VERSION ""

NS_ :

BS_:

BU_: External_Tool CADM LRRF MRRRL MRRRR

BO_ 1539 MRR_RR_Detection_022_028: 64 MRRRR
 SG_ MRR_RR_CAN_DET_MID_TARGET_028 : 462|1@0+ (1,0) [0|1] ""  CADM
 SG_ MRR_RR_CAN_DET_MID_TARGET_027 : 461|1@0+ (1,0) [0|1] ""  CADM
 SG_ MRR_RR_CAN_DET_MID_TARGET_026 : 460|1@0+ (1,0) [0|1] ""  CADM
 SG_ MRR_RR_CAN_DET_MID_TARGET_025 : 459|1@0+ (1,0) [0|1] ""  CADM
 SG_ MRR_RR_CAN_DET_MID_TARGET_024 : 458|1@0+ (1,0) [0|1] ""  CADM
 SG_ MRR_RR_CAN_DET_MID_TARGET_023 : 457|1@0+ (1,0) [0|1] ""  CADM
 SG_ MRR_RR_CAN_DET_MID_TARGET_022 : 456|1@0+ (1,0) [0|1] ""  CADM
 SG_ MRR_RR_CAN_DET_Near_TARGET_022 : 448|1@0+ (1,0) [0|1] ""  CADM
 SG_ MRR_RR_CAN_DET_Near_TARGET_023 : 449|1@0+ (1,0) [0|1] ""  CADM
 SG_ MRR_RR_CAN_DET_Near_TARGET_024 : 450|1@0+ (1,0) [0|1] ""  CADM
 SG_ MRR_RR_CAN_DET_Near_TARGET_025 : 451|1@0+ (1,0) [0|1] ""  CADM
 SG_ MRR_RR_CAN_DET_Near_TARGET_026 : 452|1@0+ (1,0) [0|1] ""  CADM
 SG_ MRR_RR_CAN_DET_Near_TARGET_027 : 453|1@0+ (1,0) [0|1] ""  CADM
 SG_ MRR_RR_CAN_DET_Near_TARGET_028 : 454|1@0+ (1,0) [0|1] ""  CADM
 SG_ MRR_RR_CAN_DET_ELEVATION_022 : 63|7@0+ (0.002748,-0.1745) [-0.1745|0.174496] "rad"  CADM
 SG_ MRR_RR_CAN_DET_CONFID_AZIMU_0018 : 33|2@0+ (1,0) [0|3] ""  CADM
 SG_ MRR_RR_CAN_DET_SUPER_RES_TA_0020 : 56|1@0+ (1,0) [0|1] ""  CADM
 SG_ MRR_RR_CAN_DET_CONFID_ELEVA_0020 : 49|1@0+ (1,0) [0|1] ""  CADM
 SG_ MRR_RR_CAN_DET_HOST_VEH_CLU_0020 : 48|1@0+ (1,0) [0|1] ""  CADM
 SG_ MRR_RR_CAN_DET_VALID_LEVEL_022 : 0|1@0+ (1,0) [0|1] ""  CADM
 SG_ MRR_RR_CAN_DET_AZIMUTH_022 : 47|14@0+ (0.0003834,-3.1416) [-3.1416|3.1396422] "rad"  CADM
 SG_ MRR_RR_CAN_DET_RANGE_022 : 31|14@0+ (0.015625,0) [0|255.984375] "m"  CADM
 SG_ MRR_RR_CAN_DET_RANGE_RATE_022 : 15|14@0+ (0.015625,-128) [-128|127.984375] "m/s"  CADM
 SG_ MRR_RR_CAN_DET_AMPLITUDE_022 : 7|7@0+ (1,-64) [-64|63] "dBsm"  CADM
 SG_ MRR_RR_CAN_SCAN_INDEX_2LSB_022 : 17|2@0+ (1,0) [0|3] ""  CADM
 SG_ MRR_RR_DET_MC_004 : 491|4@0+ (1,0) [0|15] ""  CADM
 SG_ MRR_RR_DET_CRC_004 : 503|16@0+ (1,0) [0|65535] ""  CADM
 SG_ MRR_RR_CAN_DET_ELEVATION_028 : 447|7@0+ (0.002748,-0.1745) [-0.1745|0.174496] "rad"  CADM
 SG_ MRR_RR_CAN_DET_SUPER_RES_TA_0021 : 440|1@0+ (1,0) [0|1] ""  CADM
 SG_ MRR_RR_CAN_DET_AZIMUTH_028 : 431|14@0+ (0.0003834,-3.1416) [-3.1416|3.1396422] "rad"  CADM
 SG_ MRR_RR_CAN_DET_CONFID_ELEVA_0021 : 433|1@0+ (1,0) [0|1] ""  CADM
 SG_ MRR_RR_CAN_DET_HOST_VEH_CLU_0021 : 432|1@0+ (1,0) [0|1] ""  CADM
 SG_ MRR_RR_CAN_DET_RANGE_028 : 415|14@0+ (0.015625,0) [0|255.984375] "m"  CADM
 SG_ MRR_RR_CAN_DET_CONFID_AZIMU_0019 : 417|2@0+ (1,0) [0|3] ""  CADM
 SG_ MRR_RR_CAN_DET_RANGE_RATE_028 : 399|14@0+ (0.015625,-128) [-128|127.984375] "m/s"  CADM
 SG_ MRR_RR_CAN_SCAN_INDEX_2LSB_028 : 401|2@0+ (1,0) [0|3] ""  CADM
 SG_ MRR_RR_CAN_DET_AMPLITUDE_028 : 391|7@0+ (1,-64) [-64|63] "dBsm"  CADM
 SG_ MRR_RR_CAN_DET_VALID_LEVEL_028 : 384|1@0+ (1,0) [0|1] ""  CADM
 SG_ MRR_RR_CAN_DET_ELEVATION_027 : 383|7@0+ (0.002748,-0.1745) [-0.1745|0.174496] "rad"  CADM
 SG_ MRR_RR_CAN_DET_SUPER_RES_TA_0022 : 376|1@0+ (1,0) [0|1] ""  CADM
 SG_ MRR_RR_CAN_DET_AZIMUTH_027 : 367|14@0+ (0.0003834,-3.1416) [-3.1416|3.1396422] "rad"  CADM
 SG_ MRR_RR_CAN_DET_CONFID_ELEVA_0022 : 369|1@0+ (1,0) [0|1] ""  CADM
 SG_ MRR_RR_CAN_DET_HOST_VEH_CLU_0022 : 368|1@0+ (1,0) [0|1] ""  CADM
 SG_ MRR_RR_CAN_DET_RANGE_027 : 351|14@0+ (0.015625,0) [0|255.984375] "m"  CADM
 SG_ MRR_RR_CAN_DET_CONFID_AZIMU_0020 : 353|2@0+ (1,0) [0|3] ""  CADM
 SG_ MRR_RR_CAN_DET_RANGE_RATE_027 : 335|14@0+ (0.015625,-128) [-128|127.984375] "m/s"  CADM
 SG_ MRR_RR_CAN_SCAN_INDEX_2LSB_027 : 337|2@0+ (1,0) [0|3] ""  CADM
 SG_ MRR_RR_CAN_DET_AMPLITUDE_027 : 327|7@0+ (1,-64) [-64|63] "dBsm"  CADM
 SG_ MRR_RR_CAN_DET_VALID_LEVEL_027 : 320|1@0+ (1,0) [0|1] ""  CADM
 SG_ MRR_RR_CAN_DET_ELEVATION_026 : 319|7@0+ (0.002748,-0.1745) [-0.1745|0.174496] "rad"  CADM
 SG_ MRR_RR_CAN_DET_SUPER_RES_TA_0023 : 312|1@0+ (1,0) [0|1] ""  CADM
 SG_ MRR_RR_CAN_DET_AZIMUTH_026 : 303|14@0+ (0.0003834,-3.1416) [-3.1416|3.1396422] "rad"  CADM
 SG_ MRR_RR_CAN_DET_CONFID_ELEVA_0023 : 305|1@0+ (1,0) [0|1] ""  CADM
 SG_ MRR_RR_CAN_DET_HOST_VEH_CLU_0023 : 304|1@0+ (1,0) [0|1] ""  CADM
 SG_ MRR_RR_CAN_DET_RANGE_026 : 287|14@0+ (0.015625,0) [0|255.984375] "m"  CADM
 SG_ MRR_RR_CAN_DET_CONFID_AZIMU_0021 : 289|2@0+ (1,0) [0|3] ""  CADM
 SG_ MRR_RR_CAN_DET_RANGE_RATE_026 : 271|14@0+ (0.015625,-128) [-128|127.984375] "m/s"  CADM
 SG_ MRR_RR_CAN_SCAN_INDEX_2LSB_026 : 273|2@0+ (1,0) [0|3] ""  CADM
 SG_ MRR_RR_CAN_DET_AMPLITUDE_026 : 263|7@0+ (1,-64) [-64|63] "dBsm"  CADM
 SG_ MRR_RR_CAN_DET_VALID_LEVEL_026 : 256|1@0+ (1,0) [0|1] ""  CADM
 SG_ MRR_RR_CAN_DET_ELEVATION_025 : 255|7@0+ (0.002748,-0.1745) [-0.1745|0.174496] "rad"  CADM
 SG_ MRR_RR_CAN_DET_SUPER_RES_TA_0024 : 248|1@0+ (1,0) [0|1] ""  CADM
 SG_ MRR_RR_CAN_DET_AZIMUTH_025 : 239|14@0+ (0.0003834,-3.1416) [-3.1416|3.1396422] "rad"  CADM
 SG_ MRR_RR_CAN_DET_CONFID_ELEVA_0024 : 241|1@0+ (1,0) [0|1] ""  CADM
 SG_ MRR_RR_CAN_DET_HOST_VEH_CLU_0024 : 240|1@0+ (1,0) [0|1] ""  CADM
 SG_ MRR_RR_CAN_DET_RANGE_025 : 223|14@0+ (0.015625,0) [0|255.984375] "m"  CADM
 SG_ MRR_RR_CAN_DET_CONFID_AZIMU_0022 : 225|2@0+ (1,0) [0|3] ""  CADM
 SG_ MRR_RR_CAN_DET_RANGE_RATE_025 : 207|14@0+ (0.015625,-128) [-128|127.984375] "m/s"  CADM
 SG_ MRR_RR_CAN_SCAN_INDEX_2LSB_025 : 209|2@0+ (1,0) [0|3] ""  CADM
 SG_ MRR_RR_CAN_DET_AMPLITUDE_025 : 199|7@0+ (1,-64) [-64|63] "dBsm"  CADM
 SG_ MRR_RR_CAN_DET_VALID_LEVEL_025 : 192|1@0+ (1,0) [0|1] ""  CADM
 SG_ MRR_RR_CAN_DET_ELEVATION_024 : 191|7@0+ (0.002748,-0.1745) [-0.1745|0.174496] "rad"  CADM
 SG_ MRR_RR_CAN_DET_SUPER_RES_TA_0025 : 184|1@0+ (1,0) [0|1] ""  CADM
 SG_ MRR_RR_CAN_DET_AZIMUTH_024 : 175|14@0+ (0.0003834,-3.1416) [-3.1416|3.1396422] "rad"  CADM
 SG_ MRR_RR_CAN_DET_CONFID_ELEVA_0025 : 177|1@0+ (1,0) [0|1] ""  CADM
 SG_ MRR_RR_CAN_DET_HOST_VEH_CLU_0025 : 176|1@0+ (1,0) [0|1] ""  CADM
 SG_ MRR_RR_CAN_DET_RANGE_024 : 159|14@0+ (0.015625,0) [0|255.984375] "m"  CADM
 SG_ MRR_RR_CAN_DET_CONFID_AZIMU_0023 : 161|2@0+ (1,0) [0|3] ""  CADM
 SG_ MRR_RR_CAN_DET_RANGE_RATE_024 : 143|14@0+ (0.015625,-128) [-128|127.984375] "m/s"  CADM
 SG_ MRR_RR_CAN_SCAN_INDEX_2LSB_024 : 145|2@0+ (1,0) [0|3] ""  CADM
 SG_ MRR_RR_CAN_DET_AMPLITUDE_024 : 135|7@0+ (1,-64) [-64|63] "dBsm"  CADM
 SG_ MRR_RR_CAN_DET_VALID_LEVEL_024 : 128|1@0+ (1,0) [0|1] ""  CADM
 SG_ MRR_RR_CAN_DET_ELEVATION_023 : 127|7@0+ (0.002748,-0.1745) [-0.1745|0.174496] "rad"  CADM
 SG_ MRR_RR_CAN_DET_SUPER_RES_TA_0026 : 120|1@0+ (1,0) [0|1] ""  CADM
 SG_ MRR_RR_CAN_DET_AZIMUTH_023 : 111|14@0+ (0.0003834,-3.1416) [-3.1416|3.1396422] "rad"  CADM
 SG_ MRR_RR_CAN_DET_CONFID_ELEVA_0026 : 113|1@0+ (1,0) [0|1] ""  CADM
 SG_ MRR_RR_CAN_DET_HOST_VEH_CLU_0026 : 112|1@0+ (1,0) [0|1] ""  CADM
 SG_ MRR_RR_CAN_DET_RANGE_023 : 95|14@0+ (0.015625,0) [0|255.984375] "m"  CADM
 SG_ MRR_RR_CAN_DET_CONFID_AZIMU_0024 : 97|2@0+ (1,0) [0|3] ""  CADM
 SG_ MRR_RR_CAN_DET_RANGE_RATE_023 : 79|14@0+ (0.015625,-128) [-128|127.984375] "m/s"  CADM
 SG_ MRR_RR_CAN_SCAN_INDEX_2LSB_023 : 81|2@0+ (1,0) [0|3] ""  CADM
 SG_ MRR_RR_CAN_DET_AMPLITUDE_023 : 71|7@0+ (1,-64) [-64|63] "dBsm"  CADM
 SG_ MRR_RR_CAN_DET_VALID_LEVEL_023 : 64|1@0+ (1,0) [0|1] ""  CADM

BO_ 1540 MRR_RR_Detection_029_035: 64 MRRRR
 SG_ MRR_RR_CAN_DET_MID_TARGET_035 : 462|1@0+ (1,0) [0|1] ""  CADM
 SG_ MRR_RR_CAN_DET_MID_TARGET_034 : 461|1@0+ (1,0) [0|1] ""  CADM
 SG_ MRR_RR_CAN_DET_MID_TARGET_033 : 460|1@0+ (1,0) [0|1] ""  CADM
 SG_ MRR_RR_CAN_DET_MID_TARGET_032 : 459|1@0+ (1,0) [0|1] ""  CADM
 SG_ MRR_RR_CAN_DET_MID_TARGET_031 : 458|1@0+ (1,0) [0|1] ""  CADM
 SG_ MRR_RR_CAN_DET_MID_TARGET_030 : 457|1@0+ (1,0) [0|1] ""  CADM
 SG_ MRR_RR_CAN_DET_MID_TARGET_029 : 456|1@0+ (1,0) [0|1] ""  CADM
 SG_ MRR_RR_CAN_DET_Near_TARGET_029 : 448|1@0+ (1,0) [0|1] ""  CADM
 SG_ MRR_RR_CAN_DET_Near_TARGET_030 : 449|1@0+ (1,0) [0|1] ""  CADM
 SG_ MRR_RR_CAN_DET_Near_TARGET_031 : 450|1@0+ (1,0) [0|1] ""  CADM
 SG_ MRR_RR_CAN_DET_Near_TARGET_032 : 451|1@0+ (1,0) [0|1] ""  CADM
 SG_ MRR_RR_CAN_DET_Near_TARGET_033 : 452|1@0+ (1,0) [0|1] ""  CADM
 SG_ MRR_RR_CAN_DET_Near_TARGET_034 : 453|1@0+ (1,0) [0|1] ""  CADM
 SG_ MRR_RR_CAN_DET_Near_TARGET_035 : 454|1@0+ (1,0) [0|1] ""  CADM
 SG_ MRR_RR_CAN_DET_ELEVATION_029 : 63|7@0+ (0.002748,-0.1745) [-0.1745|0.174496] "rad"  CADM
 SG_ MRR_RR_CAN_DET_CONFID_AZIMU_0025 : 33|2@0+ (1,0) [0|3] ""  CADM
 SG_ MRR_RR_CAN_DET_SUPER_RES_TA_0027 : 56|1@0+ (1,0) [0|1] ""  CADM
 SG_ MRR_RR_CAN_DET_CONFID_ELEVA_0027 : 49|1@0+ (1,0) [0|1] ""  CADM
 SG_ MRR_RR_CAN_DET_HOST_VEH_CLU_0027 : 48|1@0+ (1,0) [0|1] ""  CADM
 SG_ MRR_RR_CAN_DET_VALID_LEVEL_029 : 0|1@0+ (1,0) [0|1] ""  CADM
 SG_ MRR_RR_CAN_DET_AZIMUTH_029 : 47|14@0+ (0.0003834,-3.1416) [-3.1416|3.1396422] "rad"  CADM
 SG_ MRR_RR_CAN_DET_RANGE_029 : 31|14@0+ (0.015625,0) [0|255.984375] "m"  CADM
 SG_ MRR_RR_CAN_DET_RANGE_RATE_029 : 15|14@0+ (0.015625,-128) [-128|127.984375] "m/s"  CADM
 SG_ MRR_RR_CAN_DET_AMPLITUDE_029 : 7|7@0+ (1,-64) [-64|63] "dBsm"  CADM
 SG_ MRR_RR_CAN_SCAN_INDEX_2LSB_029 : 17|2@0+ (1,0) [0|3] ""  CADM
 SG_ MRR_RR_DET_MC_005 : 491|4@0+ (1,0) [0|15] ""  CADM
 SG_ MRR_RR_DET_CRC_005 : 503|16@0+ (1,0) [0|65535] ""  CADM
 SG_ MRR_RR_CAN_DET_ELEVATION_035 : 447|7@0+ (0.002748,-0.1745) [-0.1745|0.174496] "rad"  CADM
 SG_ MRR_RR_CAN_DET_SUPER_RES_TA_0028 : 440|1@0+ (1,0) [0|1] ""  CADM
 SG_ MRR_RR_CAN_DET_AZIMUTH_035 : 431|14@0+ (0.0003834,-3.1416) [-3.1416|3.1396422] "rad"  CADM
 SG_ MRR_RR_CAN_DET_CONFID_ELEVA_0028 : 433|1@0+ (1,0) [0|1] ""  CADM
 SG_ MRR_RR_CAN_DET_HOST_VEH_CLU_0028 : 432|1@0+ (1,0) [0|1] ""  CADM
 SG_ MRR_RR_CAN_DET_RANGE_035 : 415|14@0+ (0.015625,0) [0|255.984375] "m"  CADM
 SG_ MRR_RR_CAN_DET_CONFID_AZIMUTH_03 : 417|2@0+ (1,0) [0|3] ""  CADM
 SG_ MRR_RR_CAN_DET_RANGE_RATE_035 : 399|14@0+ (0.015625,-128) [-128|127.984375] "m/s"  CADM
 SG_ MRR_RR_CAN_SCAN_INDEX_2LSB_035 : 401|2@0+ (1,0) [0|3] ""  CADM
 SG_ MRR_RR_CAN_DET_AMPLITUDE_035 : 391|7@0+ (1,-64) [-64|63] "dBsm"  CADM
 SG_ MRR_RR_CAN_DET_VALID_LEVEL_035 : 384|1@0+ (1,0) [0|1] ""  CADM
 SG_ MRR_RR_CAN_DET_ELEVATION_034 : 383|7@0+ (0.002748,-0.1745) [-0.1745|0.174496] "rad"  CADM
 SG_ MRR_RR_CAN_DET_SUPER_RES_TA_0029 : 376|1@0+ (1,0) [0|1] ""  CADM
 SG_ MRR_RR_CAN_DET_AZIMUTH_034 : 367|14@0+ (0.0003834,-3.1416) [-3.1416|3.1396422] "rad"  CADM
 SG_ MRR_RR_CAN_DET_CONFID_ELEVA_0029 : 369|1@0+ (1,0) [0|1] ""  CADM
 SG_ MRR_RR_CAN_DET_HOST_VEH_CLU_0029 : 368|1@0+ (1,0) [0|1] ""  CADM
 SG_ MRR_RR_CAN_DET_RANGE_034 : 351|14@0+ (0.015625,0) [0|255.984375] "m"  CADM
 SG_ MRR_RR_CAN_DET_CONFID_AZIMU_0026 : 353|2@0+ (1,0) [0|3] ""  CADM
 SG_ MRR_RR_CAN_DET_RANGE_RATE_034 : 335|14@0+ (0.015625,-128) [-128|127.984375] "m/s"  CADM
 SG_ MRR_RR_CAN_SCAN_INDEX_2LSB_034 : 337|2@0+ (1,0) [0|3] ""  CADM
 SG_ MRR_RR_CAN_DET_AMPLITUDE_034 : 327|7@0+ (1,-64) [-64|63] "dBsm"  CADM
 SG_ MRR_RR_CAN_DET_VALID_LEVEL_034 : 320|1@0+ (1,0) [0|1] ""  CADM
 SG_ MRR_RR_CAN_DET_ELEVATION_033 : 319|7@0+ (0.002748,-0.1745) [-0.1745|0.174496] "rad"  CADM
 SG_ MRR_RR_CAN_DET_SUPER_RES_TA_0030 : 312|1@0+ (1,0) [0|1] ""  CADM
 SG_ MRR_RR_CAN_DET_AZIMUTH_033 : 303|14@0+ (0.0003834,-3.1416) [-3.1416|3.1396422] "rad"  CADM
 SG_ MRR_RR_CAN_DET_CONFID_ELEVA_0030 : 305|1@0+ (1,0) [0|1] ""  CADM
 SG_ MRR_RR_CAN_DET_HOST_VEH_CLU_0030 : 304|1@0+ (1,0) [0|1] ""  CADM
 SG_ MRR_RR_CAN_DET_RANGE_033 : 287|14@0+ (0.015625,0) [0|255.984375] "m"  CADM
 SG_ MRR_RR_CAN_DET_CONFID_AZIMU_0027 : 289|2@0+ (1,0) [0|3] ""  CADM
 SG_ MRR_RR_CAN_DET_RANGE_RATE_033 : 271|14@0+ (0.015625,-128) [-128|127.984375] "m/s"  CADM
 SG_ MRR_RR_CAN_SCAN_INDEX_2LSB_033 : 273|2@0+ (1,0) [0|3] ""  CADM
 SG_ MRR_RR_CAN_DET_AMPLITUDE_033 : 263|7@0+ (1,-64) [-64|63] "dBsm"  CADM
 SG_ MRR_RR_CAN_DET_VALID_LEVEL_033 : 256|1@0+ (1,0) [0|1] ""  CADM
 SG_ MRR_RR_CAN_DET_ELEVATION_032 : 255|7@0+ (0.002748,-0.1745) [-0.1745|0.174496] "rad"  CADM
 SG_ MRR_RR_CAN_DET_SUPER_RES_TA_0031 : 248|1@0+ (1,0) [0|1] ""  CADM
 SG_ MRR_RR_CAN_DET_AZIMUTH_032 : 239|14@0+ (0.0003834,-3.1416) [-3.1416|3.1396422] "rad"  CADM
 SG_ MRR_RR_CAN_DET_CONFID_ELEVA_0031 : 241|1@0+ (1,0) [0|1] ""  CADM
 SG_ MRR_RR_CAN_DET_HOST_VEH_CLU_0031 : 240|1@0+ (1,0) [0|1] ""  CADM
 SG_ MRR_RR_CAN_DET_RANGE_032 : 223|14@0+ (0.015625,0) [0|255.984375] "m"  CADM
 SG_ MRR_RR_CAN_DET_CONFID_AZIMU_0028 : 225|2@0+ (1,0) [0|3] ""  CADM
 SG_ MRR_RR_CAN_DET_RANGE_RATE_032 : 207|14@0+ (0.015625,-128) [-128|127.984375] "m/s"  CADM
 SG_ MRR_RR_CAN_SCAN_INDEX_2LSB_032 : 209|2@0+ (1,0) [0|3] ""  CADM
 SG_ MRR_RR_CAN_DET_AMPLITUDE_032 : 199|7@0+ (1,-64) [-64|63] "dBsm"  CADM
 SG_ MRR_RR_CAN_DET_VALID_LEVEL_032 : 192|1@0+ (1,0) [0|1] ""  CADM
 SG_ MRR_RR_CAN_DET_ELEVATION_031 : 191|7@0+ (0.002748,-0.1745) [-0.1745|0.174496] "rad"  CADM
 SG_ MRR_RR_CAN_DET_SUPER_RES_TA_0032 : 184|1@0+ (1,0) [0|1] ""  CADM
 SG_ MRR_RR_CAN_DET_AZIMUTH_031 : 175|14@0+ (0.0003834,-3.1416) [-3.1416|3.1396422] "rad"  CADM
 SG_ MRR_RR_CAN_DET_CONFID_ELEVA_0032 : 177|1@0+ (1,0) [0|1] ""  CADM
 SG_ MRR_RR_CAN_DET_HOST_VEH_CLU_0032 : 176|1@0+ (1,0) [0|1] ""  CADM
 SG_ MRR_RR_CAN_DET_RANGE_031 : 159|14@0+ (0.015625,0) [0|255.984375] "m"  CADM
 SG_ MRR_RR_CAN_DET_CONFID_AZIMU_0029 : 161|2@0+ (1,0) [0|3] ""  CADM
 SG_ MRR_RR_CAN_DET_RANGE_RATE_031 : 143|14@0+ (0.015625,-128) [-128|127.984375] "m/s"  CADM
 SG_ MRR_RR_CAN_SCAN_INDEX_2LSB_031 : 145|2@0+ (1,0) [0|3] ""  CADM
 SG_ MRR_RR_CAN_DET_AMPLITUDE_031 : 135|7@0+ (1,-64) [-64|63] "dBsm"  CADM
 SG_ MRR_RR_CAN_DET_VALID_LEVEL_031 : 128|1@0+ (1,0) [0|1] ""  CADM
 SG_ MRR_RR_CAN_DET_ELEVATION_030 : 127|7@0+ (0.002748,-0.1745) [-0.1745|0.174496] "rad"  CADM
 SG_ MRR_RR_CAN_DET_SUPER_RES_TA_0033 : 120|1@0+ (1,0) [0|1] ""  CADM
 SG_ MRR_RR_CAN_DET_AZIMUTH_030 : 111|14@0+ (0.0003834,-3.1416) [-3.1416|3.1396422] "rad"  CADM
 SG_ MRR_RR_CAN_DET_CONFID_ELEVA_0033 : 113|1@0+ (1,0) [0|1] ""  CADM
 SG_ MRR_RR_CAN_DET_HOST_VEH_CLU_0033 : 112|1@0+ (1,0) [0|1] ""  CADM
 SG_ MRR_RR_CAN_DET_RANGE_030 : 95|14@0+ (0.015625,0) [0|255.984375] "m"  CADM
 SG_ MRR_RR_CAN_DET_CONFID_AZIMU_0030 : 97|2@0+ (1,0) [0|3] ""  CADM
 SG_ MRR_RR_CAN_DET_RANGE_RATE_030 : 79|14@0+ (0.015625,-128) [-128|127.984375] "m/s"  CADM
 SG_ MRR_RR_CAN_SCAN_INDEX_2LSB_030 : 81|2@0+ (1,0) [0|3] ""  CADM
 SG_ MRR_RR_CAN_DET_AMPLITUDE_030 : 71|7@0+ (1,-64) [-64|63] "dBsm"  CADM
 SG_ MRR_RR_CAN_DET_VALID_LEVEL_030 : 64|1@0+ (1,0) [0|1] ""  CADM

BO_ 1541 MRR_RR_Detection_036_042: 64 MRRRR
 SG_ MRR_RR_CAN_DET_MID_TARGET_042 : 462|1@0+ (1,0) [0|1] ""  CADM
 SG_ MRR_RR_CAN_DET_MID_TARGET_041 : 461|1@0+ (1,0) [0|1] ""  CADM
 SG_ MRR_RR_CAN_DET_MID_TARGET_040 : 460|1@0+ (1,0) [0|1] ""  CADM
 SG_ MRR_RR_CAN_DET_MID_TARGET_039 : 459|1@0+ (1,0) [0|1] ""  CADM
 SG_ MRR_RR_CAN_DET_MID_TARGET_038 : 458|1@0+ (1,0) [0|1] ""  CADM
 SG_ MRR_RR_CAN_DET_MID_TARGET_037 : 457|1@0+ (1,0) [0|1] ""  CADM
 SG_ MRR_RR_CAN_DET_MID_TARGET_036 : 456|1@0+ (1,0) [0|1] ""  CADM
 SG_ MRR_RR_CAN_DET_Near_TARGET_036 : 448|1@0+ (1,0) [0|1] ""  CADM
 SG_ MRR_RR_CAN_DET_Near_TARGET_037 : 449|1@0+ (1,0) [0|1] ""  CADM
 SG_ MRR_RR_CAN_DET_Near_TARGET_038 : 450|1@0+ (1,0) [0|1] ""  CADM
 SG_ MRR_RR_CAN_DET_Near_TARGET_039 : 451|1@0+ (1,0) [0|1] ""  CADM
 SG_ MRR_RR_CAN_DET_Near_TARGET_040 : 452|1@0+ (1,0) [0|1] ""  CADM
 SG_ MRR_RR_CAN_DET_Near_TARGET_041 : 453|1@0+ (1,0) [0|1] ""  CADM
 SG_ MRR_RR_CAN_DET_Near_TARGET_042 : 454|1@0+ (1,0) [0|1] ""  CADM
 SG_ MRR_RR_CAN_DET_ELEVATION_036 : 63|7@0+ (0.002748,-0.1745) [-0.1745|0.174496] "rad"  CADM
 SG_ MRR_RR_CAN_DET_CONFID_AZIMU_0031 : 33|2@0+ (1,0) [0|3] ""  CADM
 SG_ MRR_RR_CAN_DET_SUPER_RES_TA_0034 : 56|1@0+ (1,0) [0|1] ""  CADM
 SG_ MRR_RR_CAN_DET_CONFID_ELEVA_0034 : 49|1@0+ (1,0) [0|1] ""  CADM
 SG_ MRR_RR_CAN_DET_HOST_VEH_CLU_0034 : 48|1@0+ (1,0) [0|1] ""  CADM
 SG_ MRR_RR_CAN_DET_VALID_LEVEL_036 : 0|1@0+ (1,0) [0|1] ""  CADM
 SG_ MRR_RR_CAN_DET_AZIMUTH_036 : 47|14@0+ (0.0003834,-3.1416) [-3.1416|3.1396422] "rad"  CADM
 SG_ MRR_RR_CAN_DET_RANGE_036 : 31|14@0+ (0.015625,0) [0|255.984375] "m"  CADM
 SG_ MRR_RR_CAN_DET_RANGE_RATE_036 : 15|14@0+ (0.015625,-128) [-128|127.984375] "m/s"  CADM
 SG_ MRR_RR_CAN_DET_AMPLITUDE_036 : 7|7@0+ (1,-64) [-64|63] "dBsm"  CADM
 SG_ MRR_RR_CAN_SCAN_INDEX_2LSB_036 : 17|2@0+ (1,0) [0|3] ""  CADM
 SG_ MRR_RR_DET_MC_006 : 491|4@0+ (1,0) [0|15] ""  CADM
 SG_ MRR_RR_DET_CRC_006 : 503|16@0+ (1,0) [0|65535] ""  CADM
 SG_ MRR_RR_CAN_DET_ELEVATION_042 : 447|7@0+ (0.002748,-0.1745) [-0.1745|0.174496] "rad"  CADM
 SG_ MRR_RR_CAN_DET_SUPER_RES_TA_0035 : 440|1@0+ (1,0) [0|1] ""  CADM
 SG_ MRR_RR_CAN_DET_AZIMUTH_042 : 431|14@0+ (0.0003834,-3.1416) [-3.1416|3.1396422] "rad"  CADM
 SG_ MRR_RR_CAN_DET_CONFID_ELEVA_0035 : 433|1@0+ (1,0) [0|1] ""  CADM
 SG_ MRR_RR_CAN_DET_HOST_VEH_CLU_0035 : 432|1@0+ (1,0) [0|1] ""  CADM
 SG_ MRR_RR_CAN_DET_RANGE_042 : 415|14@0+ (0.015625,0) [0|255.984375] "m"  CADM
 SG_ MRR_RR_CAN_DET_CONFID_AZIMUTH_04 : 417|2@0+ (1,0) [0|3] ""  CADM
 SG_ MRR_RR_CAN_DET_RANGE_RATE_042 : 399|14@0+ (0.015625,-128) [-128|127.984375] "m/s"  CADM
 SG_ MRR_RR_CAN_SCAN_INDEX_2LSB_042 : 401|2@0+ (1,0) [0|3] ""  CADM
 SG_ MRR_RR_CAN_DET_AMPLITUDE_042 : 391|7@0+ (1,-64) [-64|63] "dBsm"  CADM
 SG_ MRR_RR_CAN_DET_VALID_LEVEL_042 : 384|1@0+ (1,0) [0|1] ""  CADM
 SG_ MRR_RR_CAN_DET_ELEVATION_041 : 383|7@0+ (0.002748,-0.1745) [-0.1745|0.174496] "rad"  CADM
 SG_ MRR_RR_CAN_DET_SUPER_RES_TA_0036 : 376|1@0+ (1,0) [0|1] ""  CADM
 SG_ MRR_RR_CAN_DET_AZIMUTH_041 : 367|14@0+ (0.0003834,-3.1416) [-3.1416|3.1396422] "rad"  CADM
 SG_ MRR_RR_CAN_DET_CONFID_ELEVA_0036 : 369|1@0+ (1,0) [0|1] ""  CADM
 SG_ MRR_RR_CAN_DET_HOST_VEH_CLU_0036 : 368|1@0+ (1,0) [0|1] ""  CADM
 SG_ MRR_RR_CAN_DET_RANGE_041 : 351|14@0+ (0.015625,0) [0|255.984375] "m"  CADM
 SG_ MRR_RR_CAN_DET_CONFID_AZIMU_0032 : 353|2@0+ (1,0) [0|3] ""  CADM
 SG_ MRR_RR_CAN_DET_RANGE_RATE_041 : 335|14@0+ (0.015625,-128) [-128|127.984375] "m/s"  CADM
 SG_ MRR_RR_CAN_SCAN_INDEX_2LSB_041 : 337|2@0+ (1,0) [0|3] ""  CADM
 SG_ MRR_RR_CAN_DET_AMPLITUDE_041 : 327|7@0+ (1,-64) [-64|63] "dBsm"  CADM
 SG_ MRR_RR_CAN_DET_VALID_LEVEL_041 : 320|1@0+ (1,0) [0|1] ""  CADM
 SG_ MRR_RR_CAN_DET_ELEVATION_040 : 319|7@0+ (0.002748,-0.1745) [-0.1745|0.174496] "rad"  CADM
 SG_ MRR_RR_CAN_DET_SUPER_RES_TA_0037 : 312|1@0+ (1,0) [0|1] ""  CADM
 SG_ MRR_RR_CAN_DET_AZIMUTH_040 : 303|14@0+ (0.0003834,-3.1416) [-3.1416|3.1396422] "rad"  CADM
 SG_ MRR_RR_CAN_DET_CONFID_ELEVA_0037 : 305|1@0+ (1,0) [0|1] ""  CADM
 SG_ MRR_RR_CAN_DET_HOST_VEH_CLU_0037 : 304|1@0+ (1,0) [0|1] ""  CADM
 SG_ MRR_RR_CAN_DET_RANGE_040 : 287|14@0+ (0.015625,0) [0|255.984375] "m"  CADM
 SG_ MRR_RR_CAN_DET_CONFID_AZIMU_0033 : 289|2@0+ (1,0) [0|3] ""  CADM
 SG_ MRR_RR_CAN_DET_RANGE_RATE_040 : 271|14@0+ (0.015625,-128) [-128|127.984375] "m/s"  CADM
 SG_ MRR_RR_CAN_SCAN_INDEX_2LSB_040 : 273|2@0+ (1,0) [0|3] ""  CADM
 SG_ MRR_RR_CAN_DET_AMPLITUDE_040 : 263|7@0+ (1,-64) [-64|63] "dBsm"  CADM
 SG_ MRR_RR_CAN_DET_VALID_LEVEL_040 : 256|1@0+ (1,0) [0|1] ""  CADM
 SG_ MRR_RR_CAN_DET_ELEVATION_039 : 255|7@0+ (0.002748,-0.1745) [-0.1745|0.174496] "rad"  CADM
 SG_ MRR_RR_CAN_DET_SUPER_RES_TA_0038 : 248|1@0+ (1,0) [0|1] ""  CADM
 SG_ MRR_RR_CAN_DET_AZIMUTH_039 : 239|14@0+ (0.0003834,-3.1416) [-3.1416|3.1396422] "rad"  CADM
 SG_ MRR_RR_CAN_DET_CONFID_ELEVA_0038 : 241|1@0+ (1,0) [0|1] ""  CADM
 SG_ MRR_RR_CAN_DET_HOST_VEH_CLU_0038 : 240|1@0+ (1,0) [0|1] ""  CADM
 SG_ MRR_RR_CAN_DET_RANGE_039 : 223|14@0+ (0.015625,0) [0|255.984375] "m"  CADM
 SG_ MRR_RR_CAN_DET_CONFID_AZIMU_0034 : 225|2@0+ (1,0) [0|3] ""  CADM
 SG_ MRR_RR_CAN_DET_RANGE_RATE_039 : 207|14@0+ (0.015625,-128) [-128|127.984375] "m/s"  CADM
 SG_ MRR_RR_CAN_SCAN_INDEX_2LSB_039 : 209|2@0+ (1,0) [0|3] ""  CADM
 SG_ MRR_RR_CAN_DET_AMPLITUDE_039 : 199|7@0+ (1,-64) [-64|63] "dBsm"  CADM
 SG_ MRR_RR_CAN_DET_VALID_LEVEL_039 : 192|1@0+ (1,0) [0|1] ""  CADM
 SG_ MRR_RR_CAN_DET_ELEVATION_038 : 191|7@0+ (0.002748,-0.1745) [-0.1745|0.174496] "rad"  CADM
 SG_ MRR_RR_CAN_DET_SUPER_RES_TA_0039 : 184|1@0+ (1,0) [0|1] ""  CADM
 SG_ MRR_RR_CAN_DET_AZIMUTH_038 : 175|14@0+ (0.0003834,-3.1416) [-3.1416|3.1396422] "rad"  CADM
 SG_ MRR_RR_CAN_DET_CONFID_ELEVA_0039 : 177|1@0+ (1,0) [0|1] ""  CADM
 SG_ MRR_RR_CAN_DET_HOST_VEH_CLU_0039 : 176|1@0+ (1,0) [0|1] ""  CADM
 SG_ MRR_RR_CAN_DET_RANGE_038 : 159|14@0+ (0.015625,0) [0|255.984375] "m"  CADM
 SG_ MRR_RR_CAN_DET_CONFID_AZIMU_0035 : 161|2@0+ (1,0) [0|3] ""  CADM
 SG_ MRR_RR_CAN_DET_RANGE_RATE_038 : 143|14@0+ (0.015625,-128) [-128|127.984375] "m/s"  CADM
 SG_ MRR_RR_CAN_SCAN_INDEX_2LSB_038 : 145|2@0+ (1,0) [0|3] ""  CADM
 SG_ MRR_RR_CAN_DET_AMPLITUDE_038 : 135|7@0+ (1,-64) [-64|63] "dBsm"  CADM
 SG_ MRR_RR_CAN_DET_VALID_LEVEL_038 : 128|1@0+ (1,0) [0|1] ""  CADM
 SG_ MRR_RR_CAN_DET_ELEVATION_037 : 127|7@0+ (0.002748,-0.1745) [-0.1745|0.174496] "rad"  CADM
 SG_ MRR_RR_CAN_DET_SUPER_RES_TA_0040 : 120|1@0+ (1,0) [0|1] ""  CADM
 SG_ MRR_RR_CAN_DET_AZIMUTH_037 : 111|14@0+ (0.0003834,-3.1416) [-3.1416|3.1396422] "rad"  CADM
 SG_ MRR_RR_CAN_DET_CONFID_ELEVA_0040 : 113|1@0+ (1,0) [0|1] ""  CADM
 SG_ MRR_RR_CAN_DET_HOST_VEH_CLU_0040 : 112|1@0+ (1,0) [0|1] ""  CADM
 SG_ MRR_RR_CAN_DET_RANGE_037 : 95|14@0+ (0.015625,0) [0|255.984375] "m"  CADM
 SG_ MRR_RR_CAN_DET_CONFID_AZIMU_0036 : 97|2@0+ (1,0) [0|3] ""  CADM
 SG_ MRR_RR_CAN_DET_RANGE_RATE_037 : 79|14@0+ (0.015625,-128) [-128|127.984375] "m/s"  CADM
 SG_ MRR_RR_CAN_SCAN_INDEX_2LSB_037 : 81|2@0+ (1,0) [0|3] ""  CADM
 SG_ MRR_RR_CAN_DET_AMPLITUDE_037 : 71|7@0+ (1,-64) [-64|63] "dBsm"  CADM
 SG_ MRR_RR_CAN_DET_VALID_LEVEL_037 : 64|1@0+ (1,0) [0|1] ""  CADM

BO_ 1542 MRR_RR_Detection_043_049: 64 MRRRR
 SG_ MRR_RR_CAN_DET_MID_TARGET_049 : 462|1@0+ (1,0) [0|1] ""  CADM
 SG_ MRR_RR_CAN_DET_MID_TARGET_048 : 461|1@0+ (1,0) [0|1] ""  CADM
 SG_ MRR_RR_CAN_DET_MID_TARGET_047 : 460|1@0+ (1,0) [0|1] ""  CADM
 SG_ MRR_RR_CAN_DET_MID_TARGET_046 : 459|1@0+ (1,0) [0|1] ""  CADM
 SG_ MRR_RR_CAN_DET_MID_TARGET_045 : 458|1@0+ (1,0) [0|1] ""  CADM
 SG_ MRR_RR_CAN_DET_MID_TARGET_044 : 457|1@0+ (1,0) [0|1] ""  CADM
 SG_ MRR_RR_CAN_DET_MID_TARGET_043 : 456|1@0+ (1,0) [0|1] ""  CADM
 SG_ MRR_RR_CAN_DET_Near_TARGET_043 : 448|1@0+ (1,0) [0|1] ""  CADM
 SG_ MRR_RR_CAN_DET_Near_TARGET_044 : 449|1@0+ (1,0) [0|1] ""  CADM
 SG_ MRR_RR_CAN_DET_Near_TARGET_045 : 450|1@0+ (1,0) [0|1] ""  CADM
 SG_ MRR_RR_CAN_DET_Near_TARGET_046 : 451|1@0+ (1,0) [0|1] ""  CADM
 SG_ MRR_RR_CAN_DET_Near_TARGET_047 : 452|1@0+ (1,0) [0|1] ""  CADM
 SG_ MRR_RR_CAN_DET_Near_TARGET_048 : 453|1@0+ (1,0) [0|1] ""  CADM
 SG_ MRR_RR_CAN_DET_Near_TARGET_049 : 454|1@0+ (1,0) [0|1] ""  CADM
 SG_ MRR_RR_CAN_DET_ELEVATION_043 : 63|7@0+ (0.002748,-0.1745) [-0.1745|0.174496] "rad"  CADM
 SG_ MRR_RR_CAN_DET_CONFID_AZIMU_0037 : 33|2@0+ (1,0) [0|3] ""  CADM
 SG_ MRR_RR_CAN_DET_SUPER_RES_TA_0041 : 56|1@0+ (1,0) [0|1] ""  CADM
 SG_ MRR_RR_CAN_DET_CONFID_ELEVA_0041 : 49|1@0+ (1,0) [0|1] ""  CADM
 SG_ MRR_RR_CAN_DET_HOST_VEH_CLU_0041 : 48|1@0+ (1,0) [0|1] ""  CADM
 SG_ MRR_RR_CAN_DET_VALID_LEVEL_043 : 0|1@0+ (1,0) [0|1] ""  CADM
 SG_ MRR_RR_CAN_DET_AZIMUTH_043 : 47|14@0+ (0.0003834,-3.1416) [-3.1416|3.1396422] "rad"  CADM
 SG_ MRR_RR_CAN_DET_RANGE_043 : 31|14@0+ (0.015625,0) [0|255.984375] "m"  CADM
 SG_ MRR_RR_CAN_DET_RANGE_RATE_043 : 15|14@0+ (0.015625,-128) [-128|127.984375] "m/s"  CADM
 SG_ MRR_RR_CAN_DET_AMPLITUDE_043 : 7|7@0+ (1,-64) [-64|63] "dBsm"  CADM
 SG_ MRR_RR_CAN_SCAN_INDEX_2LSB_043 : 17|2@0+ (1,0) [0|3] ""  CADM
 SG_ MRR_RR_DET_MC_007 : 491|4@0+ (1,0) [0|15] ""  CADM
 SG_ MRR_RR_DET_CRC_007 : 503|16@0+ (1,0) [0|65535] ""  CADM
 SG_ MRR_RR_CAN_DET_ELEVATION_049 : 447|7@0+ (0.002748,-0.1745) [-0.1745|0.174496] "rad"  CADM
 SG_ MRR_RR_CAN_DET_SUPER_RES_TA_0042 : 440|1@0+ (1,0) [0|1] ""  CADM
 SG_ MRR_RR_CAN_DET_AZIMUTH_049 : 431|14@0+ (0.0003834,-3.1416) [-3.1416|3.1396422] "rad"  CADM
 SG_ MRR_RR_CAN_DET_CONFID_ELEVA_0042 : 433|1@0+ (1,0) [0|1] ""  CADM
 SG_ MRR_RR_CAN_DET_HOST_VEH_CLU_0042 : 432|1@0+ (1,0) [0|1] ""  CADM
 SG_ MRR_RR_CAN_DET_RANGE_049 : 415|14@0+ (0.015625,0) [0|255.984375] "m"  CADM
 SG_ MRR_RR_CAN_DET_CONFID_AZIMU_0038 : 417|2@0+ (1,0) [0|3] ""  CADM
 SG_ MRR_RR_CAN_DET_RANGE_RATE_049 : 399|14@0+ (0.015625,-128) [-128|127.984375] "m/s"  CADM
 SG_ MRR_RR_CAN_SCAN_INDEX_2LSB_049 : 401|2@0+ (1,0) [0|3] ""  CADM
 SG_ MRR_RR_CAN_DET_AMPLITUDE_049 : 391|7@0+ (1,-64) [-64|63] "dBsm"  CADM
 SG_ MRR_RR_CAN_DET_VALID_LEVEL_049 : 384|1@0+ (1,0) [0|1] ""  CADM
 SG_ MRR_RR_CAN_DET_ELEVATION_048 : 383|7@0+ (0.002748,-0.1745) [-0.1745|0.174496] "rad"  CADM
 SG_ MRR_RR_CAN_DET_SUPER_RES_TA_0043 : 376|1@0+ (1,0) [0|1] ""  CADM
 SG_ MRR_RR_CAN_DET_AZIMUTH_048 : 367|14@0+ (0.0003834,-3.1416) [-3.1416|3.1396422] "rad"  CADM
 SG_ MRR_RR_CAN_DET_CONFID_ELEVA_0043 : 369|1@0+ (1,0) [0|1] ""  CADM
 SG_ MRR_RR_CAN_DET_HOST_VEH_CLU_0043 : 368|1@0+ (1,0) [0|1] ""  CADM
 SG_ MRR_RR_CAN_DET_RANGE_048 : 351|14@0+ (0.015625,0) [0|255.984375] "m"  CADM
 SG_ MRR_RR_CAN_DET_CONFID_AZIMU_0039 : 353|2@0+ (1,0) [0|3] ""  CADM
 SG_ MRR_RR_CAN_DET_RANGE_RATE_048 : 335|14@0+ (0.015625,-128) [-128|127.984375] "m/s"  CADM
 SG_ MRR_RR_CAN_SCAN_INDEX_2LSB_048 : 337|2@0+ (1,0) [0|3] ""  CADM
 SG_ MRR_RR_CAN_DET_AMPLITUDE_048 : 327|7@0+ (1,-64) [-64|63] "dBsm"  CADM
 SG_ MRR_RR_CAN_DET_VALID_LEVEL_048 : 320|1@0+ (1,0) [0|1] ""  CADM
 SG_ MRR_RR_CAN_DET_ELEVATION_047 : 319|7@0+ (0.002748,-0.1745) [-0.1745|0.174496] "rad"  CADM
 SG_ MRR_RR_CAN_DET_SUPER_RES_TA_0044 : 312|1@0+ (1,0) [0|1] ""  CADM
 SG_ MRR_RR_CAN_DET_AZIMUTH_047 : 303|14@0+ (0.0003834,-3.1416) [-3.1416|3.1396422] "rad"  CADM
 SG_ MRR_RR_CAN_DET_CONFID_ELEVA_0044 : 305|1@0+ (1,0) [0|1] ""  CADM
 SG_ MRR_RR_CAN_DET_HOST_VEH_CLU_0044 : 304|1@0+ (1,0) [0|1] ""  CADM
 SG_ MRR_RR_CAN_DET_RANGE_047 : 287|14@0+ (0.015625,0) [0|255.984375] "m"  CADM
 SG_ MRR_RR_CAN_DET_CONFID_AZIMU_0040 : 289|2@0+ (1,0) [0|3] ""  CADM
 SG_ MRR_RR_CAN_DET_RANGE_RATE_047 : 271|14@0+ (0.015625,-128) [-128|127.984375] "m/s"  CADM
 SG_ MRR_RR_CAN_SCAN_INDEX_2LSB_047 : 273|2@0+ (1,0) [0|3] ""  CADM
 SG_ MRR_RR_CAN_DET_AMPLITUDE_047 : 263|7@0+ (1,-64) [-64|63] "dBsm"  CADM
 SG_ MRR_RR_CAN_DET_VALID_LEVEL_047 : 256|1@0+ (1,0) [0|1] ""  CADM
 SG_ MRR_RR_CAN_DET_ELEVATION_046 : 255|7@0+ (0.002748,-0.1745) [-0.1745|0.174496] "rad"  CADM
 SG_ MRR_RR_CAN_DET_SUPER_RES_TA_0045 : 248|1@0+ (1,0) [0|1] ""  CADM
 SG_ MRR_RR_CAN_DET_AZIMUTH_046 : 239|14@0+ (0.0003834,-3.1416) [-3.1416|3.1396422] "rad"  CADM
 SG_ MRR_RR_CAN_DET_CONFID_ELEVA_0045 : 241|1@0+ (1,0) [0|1] ""  CADM
 SG_ MRR_RR_CAN_DET_HOST_VEH_CLU_0045 : 240|1@0+ (1,0) [0|1] ""  CADM
 SG_ MRR_RR_CAN_DET_RANGE_046 : 223|14@0+ (0.015625,0) [0|255.984375] "m"  CADM
 SG_ MRR_RR_CAN_DET_CONFID_AZIMU_0041 : 225|2@0+ (1,0) [0|3] ""  CADM
 SG_ MRR_RR_CAN_DET_RANGE_RATE_046 : 207|14@0+ (0.015625,-128) [-128|127.984375] "m/s"  CADM
 SG_ MRR_RR_CAN_SCAN_INDEX_2LSB_046 : 209|2@0+ (1,0) [0|3] ""  CADM
 SG_ MRR_RR_CAN_DET_AMPLITUDE_046 : 199|7@0+ (1,-64) [-64|63] "dBsm"  CADM
 SG_ MRR_RR_CAN_DET_VALID_LEVEL_046 : 192|1@0+ (1,0) [0|1] ""  CADM
 SG_ MRR_RR_CAN_DET_ELEVATION_045 : 191|7@0+ (0.002748,-0.1745) [-0.1745|0.174496] "rad"  CADM
 SG_ MRR_RR_CAN_DET_SUPER_RES_TA_0046 : 184|1@0+ (1,0) [0|1] ""  CADM
 SG_ MRR_RR_CAN_DET_AZIMUTH_045 : 175|14@0+ (0.0003834,-3.1416) [-3.1416|3.1396422] "rad"  CADM
 SG_ MRR_RR_CAN_DET_CONFID_ELEVA_0046 : 177|1@0+ (1,0) [0|1] ""  CADM
 SG_ MRR_RR_CAN_DET_HOST_VEH_CLU_0046 : 176|1@0+ (1,0) [0|1] ""  CADM
 SG_ MRR_RR_CAN_DET_RANGE_045 : 159|14@0+ (0.015625,0) [0|255.984375] "m"  CADM
 SG_ MRR_RR_CAN_DET_CONFID_AZIMU_0042 : 161|2@0+ (1,0) [0|3] ""  CADM
 SG_ MRR_RR_CAN_DET_RANGE_RATE_045 : 143|14@0+ (0.015625,-128) [-128|127.984375] "m/s"  CADM
 SG_ MRR_RR_CAN_SCAN_INDEX_2LSB_045 : 145|2@0+ (1,0) [0|3] ""  CADM
 SG_ MRR_RR_CAN_DET_AMPLITUDE_045 : 135|7@0+ (1,-64) [-64|63] "dBsm"  CADM
 SG_ MRR_RR_CAN_DET_VALID_LEVEL_045 : 128|1@0+ (1,0) [0|1] ""  CADM
 SG_ MRR_RR_CAN_DET_ELEVATION_044 : 127|7@0+ (0.002748,-0.1745) [-0.1745|0.174496] "rad"  CADM
 SG_ MRR_RR_CAN_DET_SUPER_RES_TA_0047 : 120|1@0+ (1,0) [0|1] ""  CADM
 SG_ MRR_RR_CAN_DET_AZIMUTH_044 : 111|14@0+ (0.0003834,-3.1416) [-3.1416|3.1396422] "rad"  CADM
 SG_ MRR_RR_CAN_DET_CONFID_ELEVA_0047 : 113|1@0+ (1,0) [0|1] ""  CADM
 SG_ MRR_RR_CAN_DET_HOST_VEH_CLU_0047 : 112|1@0+ (1,0) [0|1] ""  CADM
 SG_ MRR_RR_CAN_DET_RANGE_044 : 95|14@0+ (0.015625,0) [0|255.984375] "m"  CADM
 SG_ MRR_RR_CAN_DET_CONFID_AZIMU_0043 : 97|2@0+ (1,0) [0|3] ""  CADM
 SG_ MRR_RR_CAN_DET_RANGE_RATE_044 : 79|14@0+ (0.015625,-128) [-128|127.984375] "m/s"  CADM
 SG_ MRR_RR_CAN_SCAN_INDEX_2LSB_044 : 81|2@0+ (1,0) [0|3] ""  CADM
 SG_ MRR_RR_CAN_DET_AMPLITUDE_044 : 71|7@0+ (1,-64) [-64|63] "dBsm"  CADM
 SG_ MRR_RR_CAN_DET_VALID_LEVEL_044 : 64|1@0+ (1,0) [0|1] ""  CADM

BO_ 1543 MRR_RR_Detection_050_056: 64 MRRRR
 SG_ MRR_RR_CAN_DET_MID_TARGET_056 : 462|1@0+ (1,0) [0|1] ""  CADM
 SG_ MRR_RR_CAN_DET_MID_TARGET_055 : 461|1@0+ (1,0) [0|1] ""  CADM
 SG_ MRR_RR_CAN_DET_MID_TARGET_054 : 460|1@0+ (1,0) [0|1] ""  CADM
 SG_ MRR_RR_CAN_DET_MID_TARGET_053 : 459|1@0+ (1,0) [0|1] ""  CADM
 SG_ MRR_RR_CAN_DET_MID_TARGET_052 : 458|1@0+ (1,0) [0|1] ""  CADM
 SG_ MRR_RR_CAN_DET_MID_TARGET_051 : 457|1@0+ (1,0) [0|1] ""  CADM
 SG_ MRR_RR_CAN_DET_MID_TARGET_050 : 456|1@0+ (1,0) [0|1] ""  CADM
 SG_ MRR_RR_CAN_DET_Near_TARGET_050 : 448|1@0+ (1,0) [0|1] ""  CADM
 SG_ MRR_RR_CAN_DET_Near_TARGET_051 : 449|1@0+ (1,0) [0|1] ""  CADM
 SG_ MRR_RR_CAN_DET_Near_TARGET_052 : 450|1@0+ (1,0) [0|1] ""  CADM
 SG_ MRR_RR_CAN_DET_Near_TARGET_053 : 451|1@0+ (1,0) [0|1] ""  CADM
 SG_ MRR_RR_CAN_DET_Near_TARGET_054 : 452|1@0+ (1,0) [0|1] ""  CADM
 SG_ MRR_RR_CAN_DET_Near_TARGET_055 : 453|1@0+ (1,0) [0|1] ""  CADM
 SG_ MRR_RR_CAN_DET_Near_TARGET_056 : 454|1@0+ (1,0) [0|1] ""  CADM
 SG_ MRR_RR_CAN_DET_ELEVATION_050 : 63|7@0+ (0.002748,-0.1745) [-0.1745|0.174496] "rad"  CADM
 SG_ MRR_RR_CAN_DET_CONFID_AZIMUTH_05 : 33|2@0+ (1,0) [0|3] ""  CADM
 SG_ MRR_RR_CAN_DET_SUPER_RES_TA_0048 : 56|1@0+ (1,0) [0|1] ""  CADM
 SG_ MRR_RR_CAN_DET_CONFID_ELEVA_0048 : 49|1@0+ (1,0) [0|1] ""  CADM
 SG_ MRR_RR_CAN_DET_HOST_VEH_CLU_0048 : 48|1@0+ (1,0) [0|1] ""  CADM
 SG_ MRR_RR_CAN_DET_VALID_LEVEL_050 : 0|1@0+ (1,0) [0|1] ""  CADM
 SG_ MRR_RR_CAN_DET_AZIMUTH_050 : 47|14@0+ (0.0003834,-3.1416) [-3.1416|3.1396422] "rad"  CADM
 SG_ MRR_RR_CAN_DET_RANGE_050 : 31|14@0+ (0.015625,0) [0|255.984375] "m"  CADM
 SG_ MRR_RR_CAN_DET_RANGE_RATE_050 : 15|14@0+ (0.015625,-128) [-128|127.984375] "m/s"  CADM
 SG_ MRR_RR_CAN_DET_AMPLITUDE_050 : 7|7@0+ (1,-64) [-64|63] "dBsm"  CADM
 SG_ MRR_RR_CAN_SCAN_INDEX_2LSB_050 : 17|2@0+ (1,0) [0|3] ""  CADM
 SG_ MRR_RR_DET_MC_008 : 491|4@0+ (1,0) [0|15] ""  CADM
 SG_ MRR_RR_DET_CRC_008 : 503|16@0+ (1,0) [0|65535] ""  CADM
 SG_ MRR_RR_CAN_DET_ELEVATION_056 : 447|7@0+ (0.002748,-0.1745) [-0.1745|0.174496] "rad"  CADM
 SG_ MRR_RR_CAN_DET_SUPER_RES_TA_0049 : 440|1@0+ (1,0) [0|1] ""  CADM
 SG_ MRR_RR_CAN_DET_AZIMUTH_056 : 431|14@0+ (0.0003834,-3.1416) [-3.1416|3.1396422] "rad"  CADM
 SG_ MRR_RR_CAN_DET_CONFID_ELEVA_0049 : 433|1@0+ (1,0) [0|1] ""  CADM
 SG_ MRR_RR_CAN_DET_HOST_VEH_CLU_0049 : 432|1@0+ (1,0) [0|1] ""  CADM
 SG_ MRR_RR_CAN_DET_RANGE_056 : 415|14@0+ (0.015625,0) [0|255.984375] "m"  CADM
 SG_ MRR_RR_CAN_DET_CONFID_AZIMU_0044 : 417|2@0+ (1,0) [0|3] ""  CADM
 SG_ MRR_RR_CAN_DET_RANGE_RATE_056 : 399|14@0+ (0.015625,-128) [-128|127.984375] "m/s"  CADM
 SG_ MRR_RR_CAN_SCAN_INDEX_2LSB_056 : 401|2@0+ (1,0) [0|3] ""  CADM
 SG_ MRR_RR_CAN_DET_AMPLITUDE_056 : 391|7@0+ (1,-64) [-64|63] "dBsm"  CADM
 SG_ MRR_RR_CAN_DET_VALID_LEVEL_056 : 384|1@0+ (1,0) [0|1] ""  CADM
 SG_ MRR_RR_CAN_DET_ELEVATION_055 : 383|7@0+ (0.002748,-0.1745) [-0.1745|0.174496] "rad"  CADM
 SG_ MRR_RR_CAN_DET_SUPER_RES_TA_0050 : 376|1@0+ (1,0) [0|1] ""  CADM
 SG_ MRR_RR_CAN_DET_AZIMUTH_055 : 367|14@0+ (0.0003834,-3.1416) [-3.1416|3.1396422] "rad"  CADM
 SG_ MRR_RR_CAN_DET_CONFID_ELEVA_0050 : 369|1@0+ (1,0) [0|1] ""  CADM
 SG_ MRR_RR_CAN_DET_HOST_VEH_CLU_0050 : 368|1@0+ (1,0) [0|1] ""  CADM
 SG_ MRR_RR_CAN_DET_RANGE_055 : 351|14@0+ (0.015625,0) [0|255.984375] "m"  CADM
 SG_ MRR_RR_CAN_DET_CONFID_AZIMU_0045 : 353|2@0+ (1,0) [0|3] ""  CADM
 SG_ MRR_RR_CAN_DET_RANGE_RATE_055 : 335|14@0+ (0.015625,-128) [-128|127.984375] "m/s"  CADM
 SG_ MRR_RR_CAN_SCAN_INDEX_2LSB_055 : 337|2@0+ (1,0) [0|3] ""  CADM
 SG_ MRR_RR_CAN_DET_AMPLITUDE_055 : 327|7@0+ (1,-64) [-64|63] "dBsm"  CADM
 SG_ MRR_RR_CAN_DET_VALID_LEVEL_055 : 320|1@0+ (1,0) [0|1] ""  CADM
 SG_ MRR_RR_CAN_DET_ELEVATION_054 : 319|7@0+ (0.002748,-0.1745) [-0.1745|0.174496] "rad"  CADM
 SG_ MRR_RR_CAN_DET_SUPER_RES_TA_0051 : 312|1@0+ (1,0) [0|1] ""  CADM
 SG_ MRR_RR_CAN_DET_AZIMUTH_054 : 303|14@0+ (0.0003834,-3.1416) [-3.1416|3.1396422] "rad"  CADM
 SG_ MRR_RR_CAN_DET_CONFID_ELEVA_0051 : 305|1@0+ (1,0) [0|1] ""  CADM
 SG_ MRR_RR_CAN_DET_HOST_VEH_CLU_0051 : 304|1@0+ (1,0) [0|1] ""  CADM
 SG_ MRR_RR_CAN_DET_RANGE_054 : 287|14@0+ (0.015625,0) [0|255.984375] "m"  CADM
 SG_ MRR_RR_CAN_DET_CONFID_AZIMU_0046 : 289|2@0+ (1,0) [0|3] ""  CADM
 SG_ MRR_RR_CAN_DET_RANGE_RATE_054 : 271|14@0+ (0.015625,-128) [-128|127.984375] "m/s"  CADM
 SG_ MRR_RR_CAN_SCAN_INDEX_2LSB_054 : 273|2@0+ (1,0) [0|3] ""  CADM
 SG_ MRR_RR_CAN_DET_AMPLITUDE_054 : 263|7@0+ (1,-64) [-64|63] "dBsm"  CADM
 SG_ MRR_RR_CAN_DET_VALID_LEVEL_054 : 256|1@0+ (1,0) [0|1] ""  CADM
 SG_ MRR_RR_CAN_DET_ELEVATION_053 : 255|7@0+ (0.002748,-0.1745) [-0.1745|0.174496] "rad"  CADM
 SG_ MRR_RR_CAN_DET_SUPER_RES_TA_0052 : 248|1@0+ (1,0) [0|1] ""  CADM
 SG_ MRR_RR_CAN_DET_AZIMUTH_053 : 239|14@0+ (0.0003834,-3.1416) [-3.1416|3.1396422] "rad"  CADM
 SG_ MRR_RR_CAN_DET_CONFID_ELEVA_0052 : 241|1@0+ (1,0) [0|1] ""  CADM
 SG_ MRR_RR_CAN_DET_HOST_VEH_CLU_0052 : 240|1@0+ (1,0) [0|1] ""  CADM
 SG_ MRR_RR_CAN_DET_RANGE_053 : 223|14@0+ (0.015625,0) [0|255.984375] "m"  CADM
 SG_ MRR_RR_CAN_DET_CONFID_AZIMU_0047 : 225|2@0+ (1,0) [0|3] ""  CADM
 SG_ MRR_RR_CAN_DET_RANGE_RATE_053 : 207|14@0+ (0.015625,-128) [-128|127.984375] "m/s"  CADM
 SG_ MRR_RR_CAN_SCAN_INDEX_2LSB_053 : 209|2@0+ (1,0) [0|3] ""  CADM
 SG_ MRR_RR_CAN_DET_AMPLITUDE_053 : 199|7@0+ (1,-64) [-64|63] "dBsm"  CADM
 SG_ MRR_RR_CAN_DET_VALID_LEVEL_053 : 192|1@0+ (1,0) [0|1] ""  CADM
 SG_ MRR_RR_CAN_DET_ELEVATION_052 : 191|7@0+ (0.002748,-0.1745) [-0.1745|0.174496] "rad"  CADM
 SG_ MRR_RR_CAN_DET_SUPER_RES_TA_0053 : 184|1@0+ (1,0) [0|1] ""  CADM
 SG_ MRR_RR_CAN_DET_AZIMUTH_052 : 175|14@0+ (0.0003834,-3.1416) [-3.1416|3.1396422] "rad"  CADM
 SG_ MRR_RR_CAN_DET_CONFID_ELEVA_0053 : 177|1@0+ (1,0) [0|1] ""  CADM
 SG_ MRR_RR_CAN_DET_HOST_VEH_CLU_0053 : 176|1@0+ (1,0) [0|1] ""  CADM
 SG_ MRR_RR_CAN_DET_RANGE_052 : 159|14@0+ (0.015625,0) [0|255.984375] "m"  CADM
 SG_ MRR_RR_CAN_DET_CONFID_AZIMU_0048 : 161|2@0+ (1,0) [0|3] ""  CADM
 SG_ MRR_RR_CAN_DET_RANGE_RATE_052 : 143|14@0+ (0.015625,-128) [-128|127.984375] "m/s"  CADM
 SG_ MRR_RR_CAN_SCAN_INDEX_2LSB_052 : 145|2@0+ (1,0) [0|3] ""  CADM
 SG_ MRR_RR_CAN_DET_AMPLITUDE_052 : 135|7@0+ (1,-64) [-64|63] "dBsm"  CADM
 SG_ MRR_RR_CAN_DET_VALID_LEVEL_052 : 128|1@0+ (1,0) [0|1] ""  CADM
 SG_ MRR_RR_CAN_DET_ELEVATION_051 : 127|7@0+ (0.002748,-0.1745) [-0.1745|0.174496] "rad"  CADM
 SG_ MRR_RR_CAN_DET_SUPER_RES_TA_0054 : 120|1@0+ (1,0) [0|1] ""  CADM
 SG_ MRR_RR_CAN_DET_AZIMUTH_051 : 111|14@0+ (0.0003834,-3.1416) [-3.1416|3.1396422] "rad"  CADM
 SG_ MRR_RR_CAN_DET_CONFID_ELEVA_0054 : 113|1@0+ (1,0) [0|1] ""  CADM
 SG_ MRR_RR_CAN_DET_HOST_VEH_CLU_0054 : 112|1@0+ (1,0) [0|1] ""  CADM
 SG_ MRR_RR_CAN_DET_RANGE_051 : 95|14@0+ (0.015625,0) [0|255.984375] "m"  CADM
 SG_ MRR_RR_CAN_DET_CONFID_AZIMU_0049 : 97|2@0+ (1,0) [0|3] ""  CADM
 SG_ MRR_RR_CAN_DET_RANGE_RATE_051 : 79|14@0+ (0.015625,-128) [-128|127.984375] "m/s"  CADM
 SG_ MRR_RR_CAN_SCAN_INDEX_2LSB_051 : 81|2@0+ (1,0) [0|3] ""  CADM
 SG_ MRR_RR_CAN_DET_AMPLITUDE_051 : 71|7@0+ (1,-64) [-64|63] "dBsm"  CADM
 SG_ MRR_RR_CAN_DET_VALID_LEVEL_051 : 64|1@0+ (1,0) [0|1] ""  CADM

BO_ 1544 MRR_RR_Detection_057_063: 64 MRRRR
 SG_ MRR_RR_CAN_DET_MID_TARGET_063 : 462|1@0+ (1,0) [0|1] ""  CADM
 SG_ MRR_RR_CAN_DET_MID_TARGET_062 : 461|1@0+ (1,0) [0|1] ""  CADM
 SG_ MRR_RR_CAN_DET_MID_TARGET_061 : 460|1@0+ (1,0) [0|1] ""  CADM
 SG_ MRR_RR_CAN_DET_MID_TARGET_060 : 459|1@0+ (1,0) [0|1] ""  CADM
 SG_ MRR_RR_CAN_DET_MID_TARGET_059 : 458|1@0+ (1,0) [0|1] ""  CADM
 SG_ MRR_RR_CAN_DET_MID_TARGET_058 : 457|1@0+ (1,0) [0|1] ""  CADM
 SG_ MRR_RR_CAN_DET_MID_TARGET_057 : 456|1@0+ (1,0) [0|1] ""  CADM
 SG_ MRR_RR_CAN_DET_Near_TARGET_057 : 448|1@0+ (1,0) [0|1] ""  CADM
 SG_ MRR_RR_CAN_DET_Near_TARGET_058 : 449|1@0+ (1,0) [0|1] ""  CADM
 SG_ MRR_RR_CAN_DET_Near_TARGET_059 : 450|1@0+ (1,0) [0|1] ""  CADM
 SG_ MRR_RR_CAN_DET_Near_TARGET_060 : 451|1@0+ (1,0) [0|1] ""  CADM
 SG_ MRR_RR_CAN_DET_Near_TARGET_061 : 452|1@0+ (1,0) [0|1] ""  CADM
 SG_ MRR_RR_CAN_DET_Near_TARGET_062 : 453|1@0+ (1,0) [0|1] ""  CADM
 SG_ MRR_RR_CAN_DET_Near_TARGET_063 : 454|1@0+ (1,0) [0|1] ""  CADM
 SG_ MRR_RR_CAN_DET_ELEVATION_057 : 63|7@0+ (0.002748,-0.1745) [-0.1745|0.174496] "rad"  CADM
 SG_ MRR_RR_CAN_DET_CONFID_AZIMU_0050 : 33|2@0+ (1,0) [0|3] ""  CADM
 SG_ MRR_RR_CAN_DET_SUPER_RES_TA_0055 : 56|1@0+ (1,0) [0|1] ""  CADM
 SG_ MRR_RR_CAN_DET_CONFID_ELEVA_0055 : 49|1@0+ (1,0) [0|1] ""  CADM
 SG_ MRR_RR_CAN_DET_HOST_VEH_CLU_0055 : 48|1@0+ (1,0) [0|1] ""  CADM
 SG_ MRR_RR_CAN_DET_VALID_LEVEL_057 : 0|1@0+ (1,0) [0|1] ""  CADM
 SG_ MRR_RR_CAN_DET_AZIMUTH_057 : 47|14@0+ (0.0003834,-3.1416) [-3.1416|3.1396422] "rad"  CADM
 SG_ MRR_RR_CAN_DET_RANGE_057 : 31|14@0+ (0.015625,0) [0|255.984375] "m"  CADM
 SG_ MRR_RR_CAN_DET_RANGE_RATE_057 : 15|14@0+ (0.015625,-128) [-128|127.984375] "m/s"  CADM
 SG_ MRR_RR_CAN_DET_AMPLITUDE_057 : 7|7@0+ (1,-64) [-64|63] "dBsm"  CADM
 SG_ MRR_RR_CAN_SCAN_INDEX_2LSB_057 : 17|2@0+ (1,0) [0|3] ""  CADM
 SG_ MRR_RR_DET_MC_009 : 491|4@0+ (1,0) [0|15] ""  CADM
 SG_ MRR_RR_DET_CRC_009 : 503|16@0+ (1,0) [0|65535] ""  CADM
 SG_ MRR_RR_CAN_DET_ELEVATION_063 : 447|7@0+ (0.002748,-0.1745) [-0.1745|0.174496] "rad"  CADM
 SG_ MRR_RR_CAN_DET_SUPER_RES_TA_0056 : 440|1@0+ (1,0) [0|1] ""  CADM
 SG_ MRR_RR_CAN_DET_AZIMUTH_063 : 431|14@0+ (0.0003834,-3.1416) [-3.1416|3.1396422] "rad"  CADM
 SG_ MRR_RR_CAN_DET_CONFID_ELEVA_0056 : 433|1@0+ (1,0) [0|1] ""  CADM
 SG_ MRR_RR_CAN_DET_HOST_VEH_CLU_0056 : 432|1@0+ (1,0) [0|1] ""  CADM
 SG_ MRR_RR_CAN_DET_RANGE_063 : 415|14@0+ (0.015625,0) [0|255.984375] "m"  CADM
 SG_ MRR_RR_CAN_DET_CONFID_AZIMUTH_06 : 417|2@0+ (1,0) [0|3] ""  CADM
 SG_ MRR_RR_CAN_DET_RANGE_RATE_063 : 399|14@0+ (0.015625,-128) [-128|127.984375] "m/s"  CADM
 SG_ MRR_RR_CAN_SCAN_INDEX_2LSB_063 : 401|2@0+ (1,0) [0|3] ""  CADM
 SG_ MRR_RR_CAN_DET_AMPLITUDE_063 : 391|7@0+ (1,-64) [-64|63] "dBsm"  CADM
 SG_ MRR_RR_CAN_DET_VALID_LEVEL_063 : 384|1@0+ (1,0) [0|1] ""  CADM
 SG_ MRR_RR_CAN_DET_ELEVATION_062 : 383|7@0+ (0.002748,-0.1745) [-0.1745|0.174496] "rad"  CADM
 SG_ MRR_RR_CAN_DET_SUPER_RES_TA_0057 : 376|1@0+ (1,0) [0|1] ""  CADM
 SG_ MRR_RR_CAN_DET_AZIMUTH_062 : 367|14@0+ (0.0003834,-3.1416) [-3.1416|3.1396422] "rad"  CADM
 SG_ MRR_RR_CAN_DET_CONFID_ELEVA_0057 : 369|1@0+ (1,0) [0|1] ""  CADM
 SG_ MRR_RR_CAN_DET_HOST_VEH_CLU_0057 : 368|1@0+ (1,0) [0|1] ""  CADM
 SG_ MRR_RR_CAN_DET_RANGE_062 : 351|14@0+ (0.015625,0) [0|255.984375] "m"  CADM
 SG_ MRR_RR_CAN_DET_CONFID_AZIMU_0051 : 353|2@0+ (1,0) [0|3] ""  CADM
 SG_ MRR_RR_CAN_DET_RANGE_RATE_062 : 335|14@0+ (0.015625,-128) [-128|127.984375] "m/s"  CADM
 SG_ MRR_RR_CAN_SCAN_INDEX_2LSB_062 : 337|2@0+ (1,0) [0|3] ""  CADM
 SG_ MRR_RR_CAN_DET_AMPLITUDE_062 : 327|7@0+ (1,-64) [-64|63] "dBsm"  CADM
 SG_ MRR_RR_CAN_DET_VALID_LEVEL_062 : 320|1@0+ (1,0) [0|1] ""  CADM
 SG_ MRR_RR_CAN_DET_ELEVATION_061 : 319|7@0+ (0.002748,-0.1745) [-0.1745|0.174496] "rad"  CADM
 SG_ MRR_RR_CAN_DET_SUPER_RES_TA_0058 : 312|1@0+ (1,0) [0|1] ""  CADM
 SG_ MRR_RR_CAN_DET_AZIMUTH_061 : 303|14@0+ (0.0003834,-3.1416) [-3.1416|3.1396422] "rad"  CADM
 SG_ MRR_RR_CAN_DET_CONFID_ELEVA_0058 : 305|1@0+ (1,0) [0|1] ""  CADM
 SG_ MRR_RR_CAN_DET_HOST_VEH_CLU_0058 : 304|1@0+ (1,0) [0|1] ""  CADM
 SG_ MRR_RR_CAN_DET_RANGE_061 : 287|14@0+ (0.015625,0) [0|255.984375] "m"  CADM
 SG_ MRR_RR_CAN_DET_CONFID_AZIMU_0052 : 289|2@0+ (1,0) [0|3] ""  CADM
 SG_ MRR_RR_CAN_DET_RANGE_RATE_061 : 271|14@0+ (0.015625,-128) [-128|127.984375] "m/s"  CADM
 SG_ MRR_RR_CAN_SCAN_INDEX_2LSB_061 : 273|2@0+ (1,0) [0|3] ""  CADM
 SG_ MRR_RR_CAN_DET_AMPLITUDE_061 : 263|7@0+ (1,-64) [-64|63] "dBsm"  CADM
 SG_ MRR_RR_CAN_DET_VALID_LEVEL_061 : 256|1@0+ (1,0) [0|1] ""  CADM
 SG_ MRR_RR_CAN_DET_ELEVATION_060 : 255|7@0+ (0.002748,-0.1745) [-0.1745|0.174496] "rad"  CADM
 SG_ MRR_RR_CAN_DET_SUPER_RES_TA_0059 : 248|1@0+ (1,0) [0|1] ""  CADM
 SG_ MRR_RR_CAN_DET_AZIMUTH_060 : 239|14@0+ (0.0003834,-3.1416) [-3.1416|3.1396422] "rad"  CADM
 SG_ MRR_RR_CAN_DET_CONFID_ELEVA_0059 : 241|1@0+ (1,0) [0|1] ""  CADM
 SG_ MRR_RR_CAN_DET_HOST_VEH_CLU_0059 : 240|1@0+ (1,0) [0|1] ""  CADM
 SG_ MRR_RR_CAN_DET_RANGE_060 : 223|14@0+ (0.015625,0) [0|255.984375] "m"  CADM
 SG_ MRR_RR_CAN_DET_CONFID_AZIMU_0053 : 225|2@0+ (1,0) [0|3] ""  CADM
 SG_ MRR_RR_CAN_DET_RANGE_RATE_060 : 207|14@0+ (0.015625,-128) [-128|127.984375] "m/s"  CADM
 SG_ MRR_RR_CAN_SCAN_INDEX_2LSB_060 : 209|2@0+ (1,0) [0|3] ""  CADM
 SG_ MRR_RR_CAN_DET_AMPLITUDE_060 : 199|7@0+ (1,-64) [-64|63] "dBsm"  CADM
 SG_ MRR_RR_CAN_DET_VALID_LEVEL_060 : 192|1@0+ (1,0) [0|1] ""  CADM
 SG_ MRR_RR_CAN_DET_ELEVATION_059 : 191|7@0+ (0.002748,-0.1745) [-0.1745|0.174496] "rad"  CADM
 SG_ MRR_RR_CAN_DET_SUPER_RES_TA_0060 : 184|1@0+ (1,0) [0|1] ""  CADM
 SG_ MRR_RR_CAN_DET_AZIMUTH_059 : 175|14@0+ (0.0003834,-3.1416) [-3.1416|3.1396422] "rad"  CADM
 SG_ MRR_RR_CAN_DET_CONFID_ELEVA_0060 : 177|1@0+ (1,0) [0|1] ""  CADM
 SG_ MRR_RR_CAN_DET_HOST_VEH_CLU_0060 : 176|1@0+ (1,0) [0|1] ""  CADM
 SG_ MRR_RR_CAN_DET_RANGE_059 : 159|14@0+ (0.015625,0) [0|255.984375] "m"  CADM
 SG_ MRR_RR_CAN_DET_CONFID_AZIMU_0054 : 161|2@0+ (1,0) [0|3] ""  CADM
 SG_ MRR_RR_CAN_DET_RANGE_RATE_059 : 143|14@0+ (0.015625,-128) [-128|127.984375] "m/s"  CADM
 SG_ MRR_RR_CAN_SCAN_INDEX_2LSB_059 : 145|2@0+ (1,0) [0|3] ""  CADM
 SG_ MRR_RR_CAN_DET_AMPLITUDE_059 : 135|7@0+ (1,-64) [-64|63] "dBsm"  CADM
 SG_ MRR_RR_CAN_DET_VALID_LEVEL_059 : 128|1@0+ (1,0) [0|1] ""  CADM
 SG_ MRR_RR_CAN_DET_ELEVATION_058 : 127|7@0+ (0.002748,-0.1745) [-0.1745|0.174496] "rad"  CADM
 SG_ MRR_RR_CAN_DET_SUPER_RES_TA_0061 : 120|1@0+ (1,0) [0|1] ""  CADM
 SG_ MRR_RR_CAN_DET_AZIMUTH_058 : 111|14@0+ (0.0003834,-3.1416) [-3.1416|3.1396422] "rad"  CADM
 SG_ MRR_RR_CAN_DET_CONFID_ELEVA_0061 : 113|1@0+ (1,0) [0|1] ""  CADM
 SG_ MRR_RR_CAN_DET_HOST_VEH_CLU_0061 : 112|1@0+ (1,0) [0|1] ""  CADM
 SG_ MRR_RR_CAN_DET_RANGE_058 : 95|14@0+ (0.015625,0) [0|255.984375] "m"  CADM
 SG_ MRR_RR_CAN_DET_CONFID_AZIMU_0055 : 97|2@0+ (1,0) [0|3] ""  CADM
 SG_ MRR_RR_CAN_DET_RANGE_RATE_058 : 79|14@0+ (0.015625,-128) [-128|127.984375] "m/s"  CADM
 SG_ MRR_RR_CAN_SCAN_INDEX_2LSB_058 : 81|2@0+ (1,0) [0|3] ""  CADM
 SG_ MRR_RR_CAN_DET_AMPLITUDE_058 : 71|7@0+ (1,-64) [-64|63] "dBsm"  CADM
 SG_ MRR_RR_CAN_DET_VALID_LEVEL_058 : 64|1@0+ (1,0) [0|1] ""  CADM

BO_ 1545 MRR_RR_Detection_064: 12 MRRRR
 SG_ MRR_RR_CAN_DET_MID_TARGET_064 : 65|1@0+ (1,0) [0|1] ""  CADM
 SG_ MRR_RR_CAN_DET_Near_TARGET_064 : 64|1@0+ (1,0) [0|1] ""  CADM
 SG_ MRR_RR_DET_MC_010 : 75|4@0+ (1,0) [0|15] ""  CADM
 SG_ MRR_RR_DET_CRC_010 : 87|16@0+ (1,0) [0|65535] ""  CADM
 SG_ MRR_RR_CAN_DET_ELEVATION_064 : 63|7@0+ (0.002748,-0.1745) [-0.1745|0.174496] "rad"  CADM
 SG_ MRR_RR_CAN_DET_CONFID_AZIMU_0056 : 33|2@0+ (1,0) [0|3] ""  CADM
 SG_ MRR_RR_CAN_DET_SUPER_RES_TA_0062 : 56|1@0+ (1,0) [0|1] ""  CADM
 SG_ MRR_RR_CAN_DET_CONFID_ELEVA_0062 : 49|1@0+ (1,0) [0|1] ""  CADM
 SG_ MRR_RR_CAN_DET_HOST_VEH_CLU_0062 : 48|1@0+ (1,0) [0|1] ""  CADM
 SG_ MRR_RR_CAN_DET_VALID_LEVEL_064 : 0|1@0+ (1,0) [0|1] ""  CADM
 SG_ MRR_RR_CAN_DET_AZIMUTH_064 : 47|14@0+ (0.0003834,-3.1416) [-3.1416|3.1396422] "rad"  CADM
 SG_ MRR_RR_CAN_DET_RANGE_064 : 31|14@0+ (0.015625,0) [0|255.984375] "m"  CADM
 SG_ MRR_RR_CAN_DET_RANGE_RATE_064 : 15|14@0+ (0.015625,-128) [-128|127.984375] "m/s"  CADM
 SG_ MRR_RR_CAN_DET_AMPLITUDE_064 : 7|7@0+ (1,-64) [-64|63] "dBsm"  CADM
 SG_ MRR_RR_CAN_SCAN_INDEX_2LSB_064 : 17|2@0+ (1,0) [0|3] ""  CADM

BO_ 263 MRR_RR_Header_Timestamps: 20 MRRRR
 SG_ MRR_RR_Sensor_Position : 74|3@0+ (1,0) [0|7] ""  CADM
 SG_ MRR_RR_Sensor_Position_Lock : 135|1@0+ (1,0) [0|1] ""  CADM
 SG_ MRR_RR_CAN_NUMBER_OF_DET : 119|8@0+ (1,0) [0|255] ""  CADM
 SG_ MRR_RR_CAN_SCAN_INDEX_FUSED : 127|8@0+ (1,0) [0|255] ""  CADM
 SG_ MRR_RR_CAN_LOOK_ID : 76|2@0+ (1,0) [0|3] ""  CADM
 SG_ MRR_RR_CAN_LOOK_INDEX : 103|16@0+ (1,0) [0|65535] ""  CADM
 SG_ MRR_RR_CAN_DET_TIME_SINCE_MEAS : 71|11@0+ (0.1,0) [0|204.7] "ms"  CADM
 SG_ MRR_RR_TrackStatus_CRC : 151|16@0+ (1,0) [0|65535] ""  CADM
 SG_ MRR_RR_TrackStatus_MC : 139|4@0+ (1,0) [0|15] ""  CADM
 SG_ MRR_RR_CAN_ReSync_counter : 87|16@0+ (1,0) [0|65535] ""  CADM
 SG_ MRR_RR_CAN_TX_LOOK_INDEX_8 : 31|8@0+ (1,0) [0|255] ""  CADM
 SG_ MRR_RR_CAN_TX_SCAN_INDEX_TRACKER : 23|8@0+ (1,0) [0|255] ""  CADM
 SG_ MRR_RR_CAN_TX_SCN_INDEX_TRKER_FU : 7|8@0+ (1,0) [0|255] ""  CADM
 SG_ MRR_RR_CAN_TX_LOOK_TYPE : 15|1@0+ (1,0) [0|1] ""  CADM
 SG_ MRR_RR_CAN_TX_LOOK_ID : 14|7@0+ (1,0) [0|127] ""  CADM
 SG_ MRR_RR_CAN_TX_SYSTEM_TIME_STAMP : 39|32@0+ (1,0) [0|4294967295] "us"  CADM

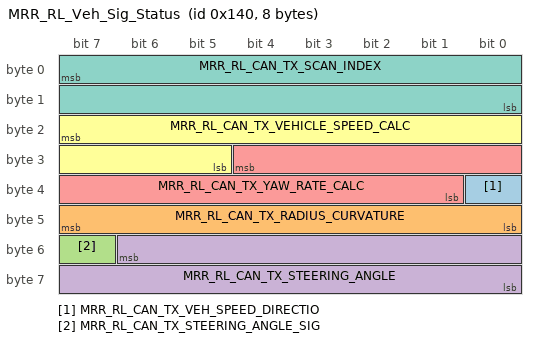
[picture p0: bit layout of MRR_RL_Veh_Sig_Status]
BO_ 320 MRR_RL_Veh_Sig_Status: 8 MRRRL
 SG_ MRR_RL_CAN_TX_VEH_SPEED_DIRECTIO : 32|1@0+ (1,0) [0|1] ""  CADM
 SG_ MRR_RL_CAN_TX_RADIUS_CURVATURE : 47|8@0- (25,0) [-3200|3175] "m"  CADM
 SG_ MRR_RL_CAN_TX_STEERING_ANGLE_SIG : 55|1@0+ (1,0) [0|1] ""  CADM
 SG_ MRR_RL_CAN_TX_STEERING_ANGLE : 54|15@0+ (1,0) [0|32767] "deg"  CADM
 SG_ MRR_RL_CAN_TX_YAW_RATE_CALC : 28|12@0- (0.0625,0) [-128|127.9375] "deg/s"  CADM
 SG_ MRR_RL_CAN_TX_VEHICLE_SPEED_CALC : 23|11@0+ (0.0625,0) [0|127.9375] "m/s"  CADM
 SG_ MRR_RL_CAN_TX_SCAN_INDEX : 7|16@0+ (1,0) [0|65535] ""  CADM

BO_ 327 MRR_RL_Header_Timestamps: 20 MRRRL
 SG_ MRR_RL_Sensor_Position : 74|3@0+ (1,0) [0|7] ""  CADM
 SG_ MRR_RL_Sensor_Position_Lock : 135|1@0+ (1,0) [0|1] ""  CADM
 SG_ MRR_RL_CAN_NUMBER_OF_DET : 119|8@0+ (1,0) [0|255] ""  CADM
 SG_ MRR_RL_CAN_SCAN_INDEX_FUSED : 127|8@0+ (1,0) [0|255] ""  CADM
 SG_ MRR_RL_CAN_LOOK_ID : 76|2@0+ (1,0) [0|3] ""  CADM
 SG_ MRR_RL_CAN_LOOK_INDEX : 103|16@0+ (1,0) [0|65535] ""  CADM
 SG_ MRR_RL_CAN_DET_TIME_SINCE_MEAS : 71|11@0+ (0.1,0) [0|204.7] "ms"  CADM
 SG_ MRR_RL_TrackStatus_CRC : 151|16@0+ (1,0) [0|65535] ""  CADM
 SG_ MRR_RL_TrackStatus_MC : 139|4@0+ (1,0) [0|15] ""  CADM
 SG_ MRR_RL_CAN_ReSync_counter : 87|16@0+ (1,0) [0|65535] ""  CADM
 SG_ MRR_RL_CAN_TX_LOOK_INDEX_8 : 31|8@0+ (1,0) [0|255] ""  CADM
 SG_ MRR_RL_CAN_TX_SCAN_INDEX_TRACKER : 23|8@0+ (1,0) [0|255] ""  CADM
 SG_ MRR_RL_CAN_TX_SCN_INDEX_TRKER_FU : 7|8@0+ (1,0) [0|255] ""  CADM
 SG_ MRR_RL_CAN_TX_LOOK_TYPE : 15|1@0+ (1,0) [0|1] ""  CADM
 SG_ MRR_RL_CAN_TX_LOOK_ID : 14|7@0+ (1,0) [0|127] ""  CADM
 SG_ MRR_RL_CAN_TX_SYSTEM_TIME_STAMP : 39|32@0+ (1,0) [0|4294967295] "us"  CADM

BO_ 322 MRR_RL_SW_Version_Status: 48 MRRRL
 SG_ MRR_RL_CAN_PCAN_PROTOCOL_PROMOTE : 263|8@0+ (1,0) [0|255] ""  CADM,External_Tool
 SG_ MRR_RL_CAN_TX_SW_VERSION_DSP : 295|24@0+ (1,0) [0|16777215] ""  External_Tool,CADM
 SG_ MRR_RL_CAN_TX_SW_VERSION_ARM : 271|24@0+ (1,0) [0|16777215] ""  External_Tool,CADM
 SG_ MRR_RL_CAN_TX_PCAN_PROTOCOL_MINO : 243|8@0+ (1,0) [0|255] ""  External_Tool,CADM
 SG_ MRR_RL_CAN_TX_PCAN_PROTOCOL_MAJO : 247|4@0+ (1,0) [0|15] ""  External_Tool,CADM
 SG_ MRR_RL_CAN_Dyn_Align_Algorithm_V : 223|8@0+ (1,0) [0|255] ""  External_Tool,CADM
 SG_ MRR_RL_CAN_Dyn_Align_Algori_0000 : 231|8@0+ (1,0) [0|255] ""  External_Tool,CADM
 SG_ MRR_RL_CAN_Dyn_Align_Algori_0001 : 239|8@0+ (1,0) [0|255] ""  External_Tool,CADM
 SG_ MRR_RL_Core_Radar_BB_Version_Fie : 215|8@0+ (1,0) [0|255] ""  CADM
 SG_ MRR_RL_Core_Radar_BB_Version_Pro : 207|8@0+ (1,0) [0|255] ""  CADM
 SG_ MRR_RL_Core_Radar_BB_Version_Min : 199|8@0+ (1,0) [0|255] ""  CADM
 SG_ MRR_RL_Core_Radar_BB_Version_Maj : 191|8@0+ (1,0) [0|255] ""  CADM
 SG_ MRR_RL_CAN_USC_Field : 183|8@0+ (1,0) [0|255] ""  CADM
 SG_ MRR_RL_CAN_USC_Promote : 175|8@0+ (1,0) [0|255] ""  CADM
 SG_ MRR_RL_CAN_USC_Minor : 167|8@0+ (1,0) [0|255] ""  CADM
 SG_ MRR_RL_CAN_USC_Major : 159|8@0+ (1,0) [0|255] ""  CADM
 SG_ MRR_RL_CAN_SMC_Field : 151|8@0+ (1,0) [0|255] ""  CADM
 SG_ MRR_RL_CAN_SMC_Promote : 143|8@0+ (1,0) [0|255] ""  CADM
 SG_ MRR_RL_CAN_SMC_Minor : 135|8@0+ (1,0) [0|255] ""  CADM
 SG_ MRR_RL_CAN_SMC_Major : 127|8@0+ (1,0) [0|255] ""  CADM
 SG_ MRR_RL_CAN_TX_Field : 23|8@0+ (1,0) [0|255] ""  CADM
 SG_ MRR_RL_CAN_TX_Promote : 13|6@0+ (1,0) [0|63] ""  CADM
 SG_ MRR_RL_CAN_TX_Major : 3|6@0+ (1,0) [0|63] ""  CADM
 SG_ MRR_RL_CAN_TX_Hardware : 7|4@0+ (1,0) [0|15] ""  CADM
 SG_ MRR_RL_CAN_TX_SERIAL_NUMBER_SEQU : 35|12@0+ (1,0) [0|4095] ""  CADM
 SG_ MRR_RL_CAN_TX_SERIAL_NUM_JULIAN_ : 38|3@0+ (1,2014) [2014|2021] ""  CADM
 SG_ MRR_RL_CAN_TX_SERIAL_NUM_JU_0000 : 31|9@0+ (1,0) [0|511] ""  CADM
 SG_ MRR_RL_CAN_TX_ARM_THROUGHPUT : 63|5@0+ (3.2258,0) [0|99.9998] ""  CADM
 SG_ MRR_RL_CAN_TX_SYSTEM_STATUS : 58|3@0+ (1,0) [0|7] ""  CADM
 SG_ MRR_RL_CAN_TX_LOOK_TYPE_1 : 50|1@0+ (1,0) [0|1] ""  CADM
 SG_ MRR_RL_CAN_TX_OVERHEAT_ERROR : 51|1@0+ (1,0) [0|1] ""  CADM
 SG_ MRR_RL_CAN_TX_RANGE_PERF_ERROR : 52|1@0+ (1,0) [0|1] ""  CADM
 SG_ MRR_RL_CAN_TX_COMM_ERROR : 53|1@0+ (1,0) [0|1] ""  CADM
 SG_ MRR_RL_CAN_TX_INTERNAL_ERROR : 54|1@0+ (1,0) [0|1] ""  CADM
 SG_ MRR_RL_CAN_TX_XCVR_OPERATIONAL : 55|1@0+ (1,0) [0|1] ""  CADM
 SG_ MRR_RL_CAN_PBL_Field_Revision : 119|8@0+ (1,0) [0|255] ""  CADM
 SG_ MRR_RL_CAN_PBL_Promote_Revision : 111|8@0+ (1,0) [0|255] ""  CADM
 SG_ MRR_RL_CAN_SW_Field_Revision : 87|8@0+ (1,0) [0|255] ""  CADM
 SG_ MRR_RL_CAN_SW_Promote_Revision : 79|8@0+ (1,0) [0|255] ""  CADM
 SG_ MRR_RL_CAN_SW_Field : 95|8@0+ (1,0) [0|255] ""  CADM
 SG_ MRR_RL_CAN_SW_Release_Revision : 71|8@0+ (1,0) [0|255] ""  CADM
 SG_ MRR_RL_CAN_PBL_Release_Revision : 103|8@0+ (1,0) [0|255] ""  CADM

BO_ 333 MRR_RL_Status_Temp_Volt: 12 MRRRL
 SG_ MRR_RL_CAN_Dolphin_AFC : 95|8@0+ (1,-50) [-50|205] "C"  CADM,External_Tool
 SG_ MRR_RL_CAN_Dolphin_Tx3 : 87|8@0+ (1,-50) [-50|205] "C"  CADM,External_Tool
 SG_ MRR_RL_CAN_Dolphin_Tx2 : 79|8@0+ (1,-50) [-50|205] "C"  CADM,External_Tool
 SG_ MRR_RL_CAN_1_8_V : 71|8@0+ (0.08,0) [0|20.4] "V"  External_Tool
 SG_ MRR_RL_CAN_BATT_VOLTS : 63|8@0+ (0.08,0) [0|20.4] "V"  External_Tool
 SG_ MRR_RL_CAN_1_25_V : 55|8@0+ (0.08,0) [0|20.4] "V"  External_Tool
 SG_ MRR_RL_CAN_5_V : 47|8@0+ (0.08,0) [0|20.4] "V"  External_Tool
 SG_ MRR_RL_CAN_1_1_V : 31|8@0+ (0.08,0) [0|20.4] "V"  External_Tool
 SG_ MRR_RL_CAN_2_3_V : 15|8@0+ (0.08,0) [0|20.4] "V"  External_Tool
 SG_ MRR_RL_CAN_Dolphin_Tx1 : 39|8@0+ (1,-50) [-50|205] "C"  CADM,External_Tool
 SG_ MRR_RL_CAN_RRU_Temp1 : 7|8@0+ (1,-50) [-50|205] "C"  CADM,External_Tool

BO_ 328 MRR_RL_Header_SensorCoverage: 12 MRRRL
 SG_ MRR_RL_Radar_Spec_Status_CRC : 87|16@0+ (1,0) [0|65535] ""  CADM,External_Tool
 SG_ MRR_RL_Radar_Spec_Status_MC : 75|4@0+ (1,0) [0|15] ""  CADM,External_Tool
 SG_ MRR_CAN_RadarWaveform_RL : 79|3@0+ (1,0) [0|7] ""  CADM,External_Tool
 SG_ MRR_RL_CAN_RANGE_COVERAGE : 7|14@0+ (0.015625,0) [0|255.984375] "m"  External_Tool,CADM
 SG_ MRR_RL_CAN_DOPPLER_COVERAGE : 23|14@0+ (0.015625,0) [0|255.984375] "m/s"  External_Tool,CADM
 SG_ MRR_RL_CAN_FOV_HOR : 39|8@0+ (1,0) [0|255] "deg"  External_Tool,CADM
 SG_ MRR_RL_CAN_FOV_VER : 47|8@0+ (1,0) [0|255] "deg"  External_Tool,CADM

BO_ 321 MRR_RL_HW_Version_Status: 64 MRRRL
 SG_ MRR_RL_Dolphin_Chip_ID_Part2 : 327|64@0+ (1,0) [0|1.84467440737096E+019] ""  CADM,External_Tool
 SG_ MRR_RL_Dolphin_Chip_ID_Part1 : 263|64@0+ (1,0) [0|1.84467440737096E+019] ""  CADM,External_Tool
 SG_ MRR_RL_RRU_Chip_ID_Part4 : 199|64@0+ (1,0) [0|1.84467440737096E+019] ""  CADM,External_Tool
 SG_ MRR_RL_RRU_Chip_ID_Part3 : 135|64@0+ (1,0) [0|1.84467440737096E+019] ""  CADM,External_Tool
 SG_ MRR_RL_RRU_Chip_ID_Part2 : 71|64@0+ (1,0) [0|1.84467440737096E+019] ""  CADM,External_Tool
 SG_ MRR_RL_RRU_Chip_ID_Part1 : 7|64@0+ (1,0) [0|1.84467440737096E+019] ""  CADM,External_Tool
 SG_ MRR_RL_CAN_TX_HW_VERSION : 391|4@0+ (1,0) [0|15] ""  CADM,External_Tool

BO_ 331 MRR_RL_Header_AlignmentState: 16 MRRRL
 SG_ MRR_RL_CAN_VRTCL_ALIGN_UPDATES_N : 87|16@0+ (1,0) [0|65535] ""  External_Tool,CADM
 SG_ MRR_RL_CAN_HRZNTL_ALIGN_UPDATES_ : 71|16@0+ (1,0) [0|65535] ""  CADM,External_Tool
 SG_ MRR_RL_Header_AlignmentState_CRC : 119|16@0+ (1,0) [0|65535] ""  CADM,External_Tool
 SG_ MRR_RL_Header_AlignmentState_MC : 107|4@0+ (1,0) [0|15] ""  CADM,External_Tool
 SG_ MRR_RL_Horizontal_Alignment_Stat : 27|4@0+ (1,0) [0|15] ""  CADM,External_Tool
 SG_ MRR_RL_Vertical_Alignment_Status : 59|4@0+ (1,0) [0|15] ""  CADM,External_Tool
 SG_ MRR_RL_Vertical_Alignment_State : 44|3@0+ (1,0) [0|7] ""  CADM,External_Tool
 SG_ MRR_RL_Horizontal_Alignment_0000 : 12|3@0+ (1,0) [0|7] ""  CADM,External_Tool
 SG_ MRR_RL_Align_Vertical_Ref : 55|10@0+ (0.000170608920038546,-0.0872664625997165) [-0.0872664625997165|0.0872664625997165] "Rad"  CADM,External_Tool
 SG_ MRR_RL_Align_Vertical_QF : 41|2@0+ (1,0) [0|3] ""  CADM,External_Tool
 SG_ MRR_RL_Align_Vertical_Angle : 39|10@0+ (0.000170608920038546,-0.0872664625997165) [-0.0872664625997165|0.0872664625997165] "Rad"  CADM,External_Tool
 SG_ MRR_RL_Align_Horizontal_Angle : 7|10@0+ (0.000341217840077093,-0.174532925199433) [-0.174532925199433|0.174532925199433] "Rad"  CADM,External_Tool
 SG_ MRR_RL_Align_Horizontal_Ref : 23|10@0+ (0.000341217840077093,-0.174532925199433) [-0.174532925199433|0.174532925199433] "Rad"  CADM,External_Tool
 SG_ MRR_RL_Align_Horizontal_QF : 9|2@0+ (1,0) [0|3] ""  CADM,External_Tool

BA_DEF_ SG_  "NWM_WakeupAllowed" ENUM  "0 No","1 Yes";
BA_DEF_ BO_  "GenMsgTimeoutTime" INT 0 2500;
BA_DEF_ BO_  "WakeupMessage" ENUM  "0 No","1 Yes";
BA_DEF_ SG_  "SignalDescription" STRING ;
BA_DEF_ SG_  "GenSigTimeoutTime_ABS_ESC" INT 0 100000;
BA_DEF_ SG_  "UsedOnPgmDBC" ENUM  "No","Yes";
BA_DEF_ BO_  "VFrameFormat" ENUM  "StandardCAN","ExtendedCAN","reserved","reserved","reserved","reserved","reserved","reserved","reserved","reserved","reserved","reserved","reserved","reserved","StandardCAN_FD","ExtendedCAN_FD";
BA_DEF_ BO_  "DiagConnection" INT 0 65535;
BA_DEF_ BO_  "CanTpBs" INT 0 255;
BA_DEF_ BO_  "EventRateOfChange" INT 10 10000;
BA_DEF_ BO_  "DiagState" ENUM  "No","Yes";
BA_DEF_ BO_  "DiagRequest" ENUM  "No","Yes";
BA_DEF_ BO_  "DiagResponse" ENUM  "No","Yes";
BA_DEF_ SG_  "GenSigCycleTime" INT 0 0;
BA_DEF_ SG_  "GenSigMarked" STRING ;
BA_DEF_ SG_  "GenSigVtName" STRING ;
BA_DEF_ SG_  "GenSigVtEn" STRING ;
BA_DEF_ SG_  "GenSigCmt" STRING ;
BA_DEF_ SG_  "GenSigSendType" ENUM  "Cyclic","OnWrite","vector_leerstring","OnChange","vector_leerstring","IfActive","vector_leerstring","NoSigSendType";
BA_DEF_ SG_  "GenSigInactiveValue" INT 0 100000;
BA_DEF_ SG_  "GenSigMissingSourceValue" INT 0 1000000000;
BA_DEF_ SG_  "GenSigStartValue" INT 0 1000000000;
BA_DEF_ BO_  "GenMsgILSupport" ENUM  "No","Yes";
BA_DEF_ BO_  "GenMsgSendType" ENUM  "FixedPeriodic","Event","EnabledPeriodic","NotUsed","NotUsed","EventPeriodic","NotUsed","NotUsed","NoMsgSendType";
BA_DEF_ BO_  "GenMsgCycleTime" INT 0 100000;
BA_DEF_ BO_  "GenMsgDelayTime" INT 0 10000;
BA_DEF_ BO_  "GenMsgNrOfRepetition" INT 0 100;
BA_DEF_ BO_  "GenMsgStartDelayTime" INT 0 10000;
BA_DEF_ BO_  "NetworkInitialization" ENUM  "No","Yes";
BA_DEF_ SG_  "SystemSignalLongSymbol" STRING ;
BA_DEF_DEF_  "NWM_WakeupAllowed" "0 No";
BA_DEF_DEF_  "GenMsgTimeoutTime" 2500;
BA_DEF_DEF_  "WakeupMessage" "0 No";
BA_DEF_DEF_  "SignalDescription" "";
BA_DEF_DEF_  "GenSigTimeoutTime_ABS_ESC" 0;
BA_DEF_DEF_  "UsedOnPgmDBC" "Yes";
BA_DEF_DEF_  "VFrameFormat" "StandardCAN_FD";
BA_DEF_DEF_  "DiagConnection" 0;
BA_DEF_DEF_  "CanTpBs" 255;
BA_DEF_DEF_  "EventRateOfChange" 10000;
BA_DEF_DEF_  "DiagState" "No";
BA_DEF_DEF_  "DiagRequest" "No";
BA_DEF_DEF_  "DiagResponse" "No";
BA_DEF_DEF_  "GenSigCycleTime" 0;
BA_DEF_DEF_  "GenSigMarked" "";
BA_DEF_DEF_  "GenSigVtName" "";
BA_DEF_DEF_  "GenSigVtEn" "";
BA_DEF_DEF_  "GenSigCmt" "";
BA_DEF_DEF_  "GenSigSendType" "NoSigSendType";
BA_DEF_DEF_  "GenSigInactiveValue" 0;
BA_DEF_DEF_  "GenSigMissingSourceValue" 0;
BA_DEF_DEF_  "GenSigStartValue" 0;
BA_DEF_DEF_  "GenMsgILSupport" "Yes";
BA_DEF_DEF_  "GenMsgSendType" "NoMsgSendType";
BA_DEF_DEF_  "GenMsgCycleTime" 0;
BA_DEF_DEF_  "GenMsgDelayTime" 0;
BA_DEF_DEF_  "GenMsgNrOfRepetition" 0;
BA_DEF_DEF_  "GenMsgStartDelayTime" 0;
BA_DEF_DEF_  "NetworkInitialization" "No";
BA_DEF_DEF_  "SystemSignalLongSymbol" "";
BA_ "GenMsgTimeoutTime" BO_ 1539 0;
BA_ "GenMsgSendType" BO_ 1539 1;
BA_ "GenMsgTimeoutTime" BO_ 1540 0;
BA_ "GenMsgSendType" BO_ 1540 1;
BA_ "GenMsgTimeoutTime" BO_ 1541 0;
BA_ "GenMsgSendType" BO_ 1541 1;
BA_ "GenMsgTimeoutTime" BO_ 1542 0;
BA_ "GenMsgSendType" BO_ 1542 1;
BA_ "GenMsgTimeoutTime" BO_ 1543 0;
BA_ "GenMsgSendType" BO_ 1543 1;
BA_ "GenMsgTimeoutTime" BO_ 1544 0;
BA_ "GenMsgSendType" BO_ 1544 1;
BA_ "GenMsgTimeoutTime" BO_ 1545 0;
BA_ "GenMsgSendType" BO_ 1545 1;
BA_ "GenMsgTimeoutTime" BO_ 263 0;
BA_ "GenMsgSendType" BO_ 263 1;
BA_ "GenMsgTimeoutTime" BO_ 320 0;
BA_ "GenMsgSendType" BO_ 320 1;
BA_ "GenMsgTimeoutTime" BO_ 327 0;
BA_ "GenMsgSendType" BO_ 327 1;
BA_ "GenMsgTimeoutTime" BO_ 322 0;
BA_ "GenMsgSendType" BO_ 322 0;
BA_ "GenMsgCycleTime" BO_ 322 1000;
BA_ "GenMsgTimeoutTime" BO_ 333 0;
BA_ "GenMsgCycleTime" BO_ 333 100;
BA_ "GenMsgSendType" BO_ 333 0;
BA_ "GenMsgTimeoutTime" BO_ 328 0;
BA_ "GenMsgSendType" BO_ 328 1;
BA_ "GenMsgTimeoutTime" BO_ 321 0;
BA_ "GenMsgSendType" BO_ 321 0;
BA_ "GenMsgCycleTime" BO_ 321 1000;
BA_ "GenMsgTimeoutTime" BO_ 331 0;
BA_ "GenMsgSendType" BO_ 331 1;
BA_ "GenSigSendType" SG_ 1539 MRR_RR_CAN_DET_MID_TARGET_028 1;
BA_ "SignalDescription" SG_ 1539 MRR_RR_CAN_DET_MID_TARGET_028 "MID_Target_Discrimination";
BA_ "SignalDescription" SG_ 1539 MRR_RR_CAN_DET_MID_TARGET_027 "MID_Target_Discrimination";
BA_ "SignalDescription" SG_ 1539 MRR_RR_CAN_DET_MID_TARGET_026 "MID_Target_Discrimination";
BA_ "SignalDescription" SG_ 1539 MRR_RR_CAN_DET_MID_TARGET_025 "MID_Target_Discrimination";
BA_ "SignalDescription" SG_ 1539 MRR_RR_CAN_DET_MID_TARGET_024 "MID_Target_Discrimination";
BA_ "SignalDescription" SG_ 1539 MRR_RR_CAN_DET_MID_TARGET_023 "MID_Target_Discrimination";
BA_ "SignalDescription" SG_ 1539 MRR_RR_CAN_DET_MID_TARGET_022 "MID_Target_Discrimination";
BA_ "SignalDescription" SG_ 1539 MRR_RR_CAN_DET_Near_TARGET_022 "Near_Target_Discrimination";
BA_ "SignalDescription" SG_ 1539 MRR_RR_CAN_DET_Near_TARGET_023 "Near_Target_Discrimination";
BA_ "SignalDescription" SG_ 1539 MRR_RR_CAN_DET_Near_TARGET_024 "Near_Target_Discrimination";
BA_ "SignalDescription" SG_ 1539 MRR_RR_CAN_DET_Near_TARGET_025 "Near_Target_Discrimination";
BA_ "SignalDescription" SG_ 1539 MRR_RR_CAN_DET_Near_TARGET_026 "Near_Target_Discrimination";
BA_ "SignalDescription" SG_ 1539 MRR_RR_CAN_DET_Near_TARGET_027 "Near_Target_Discrimination";
BA_ "SignalDescription" SG_ 1539 MRR_RR_CAN_DET_Near_TARGET_028 "Near_Target_Discrimination";
BA_ "GenSigCmt" SG_ 1539 MRR_RR_CAN_DET_ELEVATION_022 "Detected object elevation position";
BA_ "GenSigStartValue" SG_ 1539 MRR_RR_CAN_DET_ELEVATION_022 63.8646288209607;
BA_ "GenSigVtEn" SG_ 1539 MRR_RR_CAN_DET_CONFID_AZIMU_0018 "TRUE";
BA_ "GenSigCmt" SG_ 1539 MRR_RR_CAN_DET_CONFID_AZIMU_0018 "Signal to noise level";
BA_ "SystemSignalLongSymbol" SG_ 1539 MRR_RR_CAN_DET_CONFID_AZIMU_0018 "MRR_RR_CAN_DET_CONFID_AZIMUTH_022";
BA_ "GenSigCmt" SG_ 1539 MRR_RR_CAN_DET_SUPER_RES_TA_0020 "Super resolution target";
BA_ "SystemSignalLongSymbol" SG_ 1539 MRR_RR_CAN_DET_SUPER_RES_TA_0020 "MRR_RR_CAN_DET_SUPER_RES_TARGET_022";
BA_ "GenSigCmt" SG_ 1539 MRR_RR_CAN_DET_CONFID_ELEVA_0020 "Elevation Angle Confidence";
BA_ "SystemSignalLongSymbol" SG_ 1539 MRR_RR_CAN_DET_CONFID_ELEVA_0020 "MRR_RR_CAN_DET_CONFID_ELEVATION_022";
BA_ "GenSigCmt" SG_ 1539 MRR_RR_CAN_DET_HOST_VEH_CLU_0020 "Host vehicle clutter";
BA_ "SystemSignalLongSymbol" SG_ 1539 MRR_RR_CAN_DET_HOST_VEH_CLU_0020 "MRR_RR_CAN_DET_HOST_VEH_CLUTTER_022";
BA_ "GenSigCmt" SG_ 1539 MRR_RR_CAN_DET_VALID_LEVEL_022 "Detected object valid level";
BA_ "GenSigCmt" SG_ 1539 MRR_RR_CAN_DET_AZIMUTH_022 "Detected object azimuth position";
BA_ "GenSigStartValue" SG_ 1539 MRR_RR_CAN_DET_AZIMUTH_022 8194.05320813772;
BA_ "GenSigCmt" SG_ 1539 MRR_RR_CAN_DET_RANGE_022 "Detected object range";
BA_ "GenSigCmt" SG_ 1539 MRR_RR_CAN_DET_RANGE_RATE_022 "Detected object range rate";
BA_ "GenSigStartValue" SG_ 1539 MRR_RR_CAN_DET_RANGE_RATE_022 8192;
BA_ "GenSigCmt" SG_ 1539 MRR_RR_CAN_DET_AMPLITUDE_022 "Detected object amplitude";
BA_ "GenSigStartValue" SG_ 1539 MRR_RR_CAN_DET_AMPLITUDE_022 64;
BA_ "GenSigCmt" SG_ 1539 MRR_RR_CAN_SCAN_INDEX_2LSB_022 "The two LSB of scan index";
BA_ "GenSigStartValue" SG_ 1539 MRR_RR_CAN_DET_ELEVATION_028 63.8646288209607;
BA_ "GenSigCmt" SG_ 1539 MRR_RR_CAN_DET_ELEVATION_028 "Detected object elevation position";
BA_ "GenSigCmt" SG_ 1539 MRR_RR_CAN_DET_SUPER_RES_TA_0021 "Super resolution target";
BA_ "SystemSignalLongSymbol" SG_ 1539 MRR_RR_CAN_DET_SUPER_RES_TA_0021 "MRR_RR_CAN_DET_SUPER_RES_TARGET_028";
BA_ "GenSigCmt" SG_ 1539 MRR_RR_CAN_DET_AZIMUTH_028 "Detected object azimuth position";
BA_ "GenSigStartValue" SG_ 1539 MRR_RR_CAN_DET_AZIMUTH_028 8194.05320813772;
BA_ "GenSigCmt" SG_ 1539 MRR_RR_CAN_DET_CONFID_ELEVA_0021 "Elevation Angle Confidence";
BA_ "SystemSignalLongSymbol" SG_ 1539 MRR_RR_CAN_DET_CONFID_ELEVA_0021 "MRR_RR_CAN_DET_CONFID_ELEVATION_028";
BA_ "GenSigCmt" SG_ 1539 MRR_RR_CAN_DET_HOST_VEH_CLU_0021 "Host vehicle clutter";
BA_ "SystemSignalLongSymbol" SG_ 1539 MRR_RR_CAN_DET_HOST_VEH_CLU_0021 "MRR_RR_CAN_DET_HOST_VEH_CLUTTER_028";
BA_ "GenSigCmt" SG_ 1539 MRR_RR_CAN_DET_RANGE_028 "Detected object range";
BA_ "GenSigVtEn" SG_ 1539 MRR_RR_CAN_DET_CONFID_AZIMU_0019 "TRUE";
BA_ "GenSigCmt" SG_ 1539 MRR_RR_CAN_DET_CONFID_AZIMU_0019 "Signal to noise level";
BA_ "SystemSignalLongSymbol" SG_ 1539 MRR_RR_CAN_DET_CONFID_AZIMU_0019 "MRR_RR_CAN_DET_CONFID_AZIMUTH_028";
BA_ "GenSigCmt" SG_ 1539 MRR_RR_CAN_DET_RANGE_RATE_028 "Detected object range rate";
BA_ "GenSigStartValue" SG_ 1539 MRR_RR_CAN_DET_RANGE_RATE_028 8192;
BA_ "GenSigCmt" SG_ 1539 MRR_RR_CAN_SCAN_INDEX_2LSB_028 "The two LSB of scan index";
BA_ "GenSigCmt" SG_ 1539 MRR_RR_CAN_DET_AMPLITUDE_028 "Detected object amplitude";
BA_ "GenSigStartValue" SG_ 1539 MRR_RR_CAN_DET_AMPLITUDE_028 64;
BA_ "GenSigCmt" SG_ 1539 MRR_RR_CAN_DET_VALID_LEVEL_028 "Detected object valid level";
BA_ "GenSigCmt" SG_ 1539 MRR_RR_CAN_DET_ELEVATION_027 "Detected object elevation position";
BA_ "GenSigStartValue" SG_ 1539 MRR_RR_CAN_DET_ELEVATION_027 63.8646288209607;
BA_ "GenSigCmt" SG_ 1539 MRR_RR_CAN_DET_SUPER_RES_TA_0022 "Super resolution target";
BA_ "SystemSignalLongSymbol" SG_ 1539 MRR_RR_CAN_DET_SUPER_RES_TA_0022 "MRR_RR_CAN_DET_SUPER_RES_TARGET_027";
BA_ "GenSigCmt" SG_ 1539 MRR_RR_CAN_DET_AZIMUTH_027 "Detected object azimuth position";
BA_ "GenSigStartValue" SG_ 1539 MRR_RR_CAN_DET_AZIMUTH_027 8194.05320813772;
BA_ "GenSigCmt" SG_ 1539 MRR_RR_CAN_DET_CONFID_ELEVA_0022 "Elevation Angle Confidence";
BA_ "SystemSignalLongSymbol" SG_ 1539 MRR_RR_CAN_DET_CONFID_ELEVA_0022 "MRR_RR_CAN_DET_CONFID_ELEVATION_027";
BA_ "GenSigCmt" SG_ 1539 MRR_RR_CAN_DET_HOST_VEH_CLU_0022 "Host vehicle clutter";
BA_ "SystemSignalLongSymbol" SG_ 1539 MRR_RR_CAN_DET_HOST_VEH_CLU_0022 "MRR_RR_CAN_DET_HOST_VEH_CLUTTER_027";
BA_ "GenSigCmt" SG_ 1539 MRR_RR_CAN_DET_RANGE_027 "Detected object range";
BA_ "GenSigVtEn" SG_ 1539 MRR_RR_CAN_DET_CONFID_AZIMU_0020 "TRUE";
BA_ "GenSigCmt" SG_ 1539 MRR_RR_CAN_DET_CONFID_AZIMU_0020 "Signal to noise level";
BA_ "SystemSignalLongSymbol" SG_ 1539 MRR_RR_CAN_DET_CONFID_AZIMU_0020 "MRR_RR_CAN_DET_CONFID_AZIMUTH_027";
BA_ "GenSigCmt" SG_ 1539 MRR_RR_CAN_DET_RANGE_RATE_027 "Detected object range rate";
BA_ "GenSigStartValue" SG_ 1539 MRR_RR_CAN_DET_RANGE_RATE_027 8192;
BA_ "GenSigCmt" SG_ 1539 MRR_RR_CAN_SCAN_INDEX_2LSB_027 "The two LSB of scan index";
BA_ "GenSigCmt" SG_ 1539 MRR_RR_CAN_DET_AMPLITUDE_027 "Detected object amplitude";
BA_ "GenSigStartValue" SG_ 1539 MRR_RR_CAN_DET_AMPLITUDE_027 64;
BA_ "GenSigCmt" SG_ 1539 MRR_RR_CAN_DET_VALID_LEVEL_027 "Detected object valid level";
BA_ "GenSigCmt" SG_ 1539 MRR_RR_CAN_DET_ELEVATION_026 "Detected object elevation position";
BA_ "GenSigStartValue" SG_ 1539 MRR_RR_CAN_DET_ELEVATION_026 63.8646288209607;
BA_ "GenSigCmt" SG_ 1539 MRR_RR_CAN_DET_SUPER_RES_TA_0023 "Super resolution target";
BA_ "SystemSignalLongSymbol" SG_ 1539 MRR_RR_CAN_DET_SUPER_RES_TA_0023 "MRR_RR_CAN_DET_SUPER_RES_TARGET_026";
BA_ "GenSigCmt" SG_ 1539 MRR_RR_CAN_DET_AZIMUTH_026 "Detected object azimuth position";
BA_ "GenSigStartValue" SG_ 1539 MRR_RR_CAN_DET_AZIMUTH_026 8194.05320813772;
BA_ "GenSigCmt" SG_ 1539 MRR_RR_CAN_DET_CONFID_ELEVA_0023 "Elevation Angle Confidence";
BA_ "SystemSignalLongSymbol" SG_ 1539 MRR_RR_CAN_DET_CONFID_ELEVA_0023 "MRR_RR_CAN_DET_CONFID_ELEVATION_026";
BA_ "GenSigCmt" SG_ 1539 MRR_RR_CAN_DET_HOST_VEH_CLU_0023 "Host vehicle clutter";
BA_ "SystemSignalLongSymbol" SG_ 1539 MRR_RR_CAN_DET_HOST_VEH_CLU_0023 "MRR_RR_CAN_DET_HOST_VEH_CLUTTER_026";
BA_ "GenSigCmt" SG_ 1539 MRR_RR_CAN_DET_RANGE_026 "Detected object range";
BA_ "GenSigVtEn" SG_ 1539 MRR_RR_CAN_DET_CONFID_AZIMU_0021 "TRUE";
BA_ "GenSigCmt" SG_ 1539 MRR_RR_CAN_DET_CONFID_AZIMU_0021 "Signal to noise level";
BA_ "SystemSignalLongSymbol" SG_ 1539 MRR_RR_CAN_DET_CONFID_AZIMU_0021 "MRR_RR_CAN_DET_CONFID_AZIMUTH_026";
BA_ "GenSigCmt" SG_ 1539 MRR_RR_CAN_DET_RANGE_RATE_026 "Detected object range rate";
BA_ "GenSigStartValue" SG_ 1539 MRR_RR_CAN_DET_RANGE_RATE_026 8192;
BA_ "GenSigCmt" SG_ 1539 MRR_RR_CAN_SCAN_INDEX_2LSB_026 "The two LSB of scan index";
BA_ "GenSigCmt" SG_ 1539 MRR_RR_CAN_DET_AMPLITUDE_026 "Detected object amplitude";
BA_ "GenSigStartValue" SG_ 1539 MRR_RR_CAN_DET_AMPLITUDE_026 64;
BA_ "GenSigCmt" SG_ 1539 MRR_RR_CAN_DET_VALID_LEVEL_026 "Detected object valid level";
BA_ "GenSigCmt" SG_ 1539 MRR_RR_CAN_DET_ELEVATION_025 "Detected object elevation position";
BA_ "GenSigStartValue" SG_ 1539 MRR_RR_CAN_DET_ELEVATION_025 63.8646288209607;
BA_ "GenSigCmt" SG_ 1539 MRR_RR_CAN_DET_SUPER_RES_TA_0024 "Super resolution target";
BA_ "SystemSignalLongSymbol" SG_ 1539 MRR_RR_CAN_DET_SUPER_RES_TA_0024 "MRR_RR_CAN_DET_SUPER_RES_TARGET_025";
BA_ "GenSigCmt" SG_ 1539 MRR_RR_CAN_DET_AZIMUTH_025 "Detected object azimuth position";
BA_ "GenSigStartValue" SG_ 1539 MRR_RR_CAN_DET_AZIMUTH_025 8194.05320813772;
BA_ "GenSigCmt" SG_ 1539 MRR_RR_CAN_DET_CONFID_ELEVA_0024 "Elevation Angle Confidence";
BA_ "SystemSignalLongSymbol" SG_ 1539 MRR_RR_CAN_DET_CONFID_ELEVA_0024 "MRR_RR_CAN_DET_CONFID_ELEVATION_025";
BA_ "GenSigCmt" SG_ 1539 MRR_RR_CAN_DET_HOST_VEH_CLU_0024 "Host vehicle clutter";
BA_ "SystemSignalLongSymbol" SG_ 1539 MRR_RR_CAN_DET_HOST_VEH_CLU_0024 "MRR_RR_CAN_DET_HOST_VEH_CLUTTER_025";
BA_ "GenSigCmt" SG_ 1539 MRR_RR_CAN_DET_RANGE_025 "Detected object range";
BA_ "GenSigVtEn" SG_ 1539 MRR_RR_CAN_DET_CONFID_AZIMU_0022 "TRUE";
BA_ "GenSigCmt" SG_ 1539 MRR_RR_CAN_DET_CONFID_AZIMU_0022 "Signal to noise level";
BA_ "SystemSignalLongSymbol" SG_ 1539 MRR_RR_CAN_DET_CONFID_AZIMU_0022 "MRR_RR_CAN_DET_CONFID_AZIMUTH_025";
BA_ "GenSigCmt" SG_ 1539 MRR_RR_CAN_DET_RANGE_RATE_025 "Detected object range rate";
BA_ "GenSigStartValue" SG_ 1539 MRR_RR_CAN_DET_RANGE_RATE_025 8192;
BA_ "GenSigCmt" SG_ 1539 MRR_RR_CAN_SCAN_INDEX_2LSB_025 "The two LSB of scan index";
BA_ "GenSigCmt" SG_ 1539 MRR_RR_CAN_DET_AMPLITUDE_025 "Detected object amplitude";
BA_ "GenSigStartValue" SG_ 1539 MRR_RR_CAN_DET_AMPLITUDE_025 64;
BA_ "GenSigCmt" SG_ 1539 MRR_RR_CAN_DET_VALID_LEVEL_025 "Detected object valid level";
BA_ "GenSigCmt" SG_ 1539 MRR_RR_CAN_DET_ELEVATION_024 "Detected object elevation position";
BA_ "GenSigStartValue" SG_ 1539 MRR_RR_CAN_DET_ELEVATION_024 63.8646288209607;
BA_ "GenSigCmt" SG_ 1539 MRR_RR_CAN_DET_SUPER_RES_TA_0025 "Super resolution target";
BA_ "SystemSignalLongSymbol" SG_ 1539 MRR_RR_CAN_DET_SUPER_RES_TA_0025 "MRR_RR_CAN_DET_SUPER_RES_TARGET_024";
BA_ "GenSigCmt" SG_ 1539 MRR_RR_CAN_DET_AZIMUTH_024 "Detected object azimuth position";
BA_ "GenSigStartValue" SG_ 1539 MRR_RR_CAN_DET_AZIMUTH_024 8194.05320813772;
BA_ "GenSigCmt" SG_ 1539 MRR_RR_CAN_DET_CONFID_ELEVA_0025 "Elevation Angle Confidence";
BA_ "SystemSignalLongSymbol" SG_ 1539 MRR_RR_CAN_DET_CONFID_ELEVA_0025 "MRR_RR_CAN_DET_CONFID_ELEVATION_024";
BA_ "GenSigCmt" SG_ 1539 MRR_RR_CAN_DET_HOST_VEH_CLU_0025 "Host vehicle clutter";
BA_ "SystemSignalLongSymbol" SG_ 1539 MRR_RR_CAN_DET_HOST_VEH_CLU_0025 "MRR_RR_CAN_DET_HOST_VEH_CLUTTER_024";
BA_ "GenSigCmt" SG_ 1539 MRR_RR_CAN_DET_RANGE_024 "Detected object range";
BA_ "GenSigVtEn" SG_ 1539 MRR_RR_CAN_DET_CONFID_AZIMU_0023 "TRUE";
BA_ "GenSigCmt" SG_ 1539 MRR_RR_CAN_DET_CONFID_AZIMU_0023 "Signal to noise level";
BA_ "SystemSignalLongSymbol" SG_ 1539 MRR_RR_CAN_DET_CONFID_AZIMU_0023 "MRR_RR_CAN_DET_CONFID_AZIMUTH_024";
BA_ "GenSigCmt" SG_ 1539 MRR_RR_CAN_DET_RANGE_RATE_024 "Detected object range rate";
BA_ "GenSigStartValue" SG_ 1539 MRR_RR_CAN_DET_RANGE_RATE_024 8192;
BA_ "GenSigCmt" SG_ 1539 MRR_RR_CAN_SCAN_INDEX_2LSB_024 "The two LSB of scan index";
BA_ "GenSigCmt" SG_ 1539 MRR_RR_CAN_DET_AMPLITUDE_024 "Detected object amplitude";
BA_ "GenSigStartValue" SG_ 1539 MRR_RR_CAN_DET_AMPLITUDE_024 64;
BA_ "GenSigCmt" SG_ 1539 MRR_RR_CAN_DET_VALID_LEVEL_024 "Detected object valid level";
BA_ "GenSigCmt" SG_ 1539 MRR_RR_CAN_DET_ELEVATION_023 "Detected object elevation position";
BA_ "GenSigStartValue" SG_ 1539 MRR_RR_CAN_DET_ELEVATION_023 63.8646288209607;
BA_ "GenSigCmt" SG_ 1539 MRR_RR_CAN_DET_SUPER_RES_TA_0026 "Super resolution target";
BA_ "SystemSignalLongSymbol" SG_ 1539 MRR_RR_CAN_DET_SUPER_RES_TA_0026 "MRR_RR_CAN_DET_SUPER_RES_TARGET_023";
BA_ "GenSigCmt" SG_ 1539 MRR_RR_CAN_DET_AZIMUTH_023 "Detected object azimuth position";
BA_ "GenSigStartValue" SG_ 1539 MRR_RR_CAN_DET_AZIMUTH_023 8194.05320813772;
BA_ "GenSigCmt" SG_ 1539 MRR_RR_CAN_DET_CONFID_ELEVA_0026 "Elevation Angle Confidence";
BA_ "SystemSignalLongSymbol" SG_ 1539 MRR_RR_CAN_DET_CONFID_ELEVA_0026 "MRR_RR_CAN_DET_CONFID_ELEVATION_023";
BA_ "GenSigCmt" SG_ 1539 MRR_RR_CAN_DET_HOST_VEH_CLU_0026 "Host vehicle clutter";
BA_ "SystemSignalLongSymbol" SG_ 1539 MRR_RR_CAN_DET_HOST_VEH_CLU_0026 "MRR_RR_CAN_DET_HOST_VEH_CLUTTER_023";
BA_ "GenSigCmt" SG_ 1539 MRR_RR_CAN_DET_RANGE_023 "Detected object range";
BA_ "GenSigVtEn" SG_ 1539 MRR_RR_CAN_DET_CONFID_AZIMU_0024 "TRUE";
BA_ "GenSigCmt" SG_ 1539 MRR_RR_CAN_DET_CONFID_AZIMU_0024 "Signal to noise level";
BA_ "SystemSignalLongSymbol" SG_ 1539 MRR_RR_CAN_DET_CONFID_AZIMU_0024 "MRR_RR_CAN_DET_CONFID_AZIMUTH_023";
BA_ "GenSigCmt" SG_ 1539 MRR_RR_CAN_DET_RANGE_RATE_023 "Detected object range rate";
BA_ "GenSigStartValue" SG_ 1539 MRR_RR_CAN_DET_RANGE_RATE_023 8192;
BA_ "GenSigCmt" SG_ 1539 MRR_RR_CAN_SCAN_INDEX_2LSB_023 "The two LSB of scan index";
BA_ "GenSigCmt" SG_ 1539 MRR_RR_CAN_DET_AMPLITUDE_023 "Detected object amplitude";
BA_ "GenSigStartValue" SG_ 1539 MRR_RR_CAN_DET_AMPLITUDE_023 64;
BA_ "GenSigCmt" SG_ 1539 MRR_RR_CAN_DET_VALID_LEVEL_023 "Detected object valid level";
BA_ "GenSigSendType" SG_ 1540 MRR_RR_CAN_DET_MID_TARGET_035 1;
BA_ "SignalDescription" SG_ 1540 MRR_RR_CAN_DET_MID_TARGET_035 "MID_Target_Discrimination";
BA_ "SignalDescription" SG_ 1540 MRR_RR_CAN_DET_MID_TARGET_034 "MID_Target_Discrimination";
BA_ "SignalDescription" SG_ 1540 MRR_RR_CAN_DET_MID_TARGET_033 "MID_Target_Discrimination";
BA_ "SignalDescription" SG_ 1540 MRR_RR_CAN_DET_MID_TARGET_032 "MID_Target_Discrimination";
BA_ "SignalDescription" SG_ 1540 MRR_RR_CAN_DET_MID_TARGET_031 "MID_Target_Discrimination";
BA_ "SignalDescription" SG_ 1540 MRR_RR_CAN_DET_MID_TARGET_030 "MID_Target_Discrimination";
BA_ "SignalDescription" SG_ 1540 MRR_RR_CAN_DET_MID_TARGET_029 "MID_Target_Discrimination";
BA_ "SignalDescription" SG_ 1540 MRR_RR_CAN_DET_Near_TARGET_029 "Near_Target_Discrimination";
BA_ "SignalDescription" SG_ 1540 MRR_RR_CAN_DET_Near_TARGET_030 "Near_Target_Discrimination";
BA_ "SignalDescription" SG_ 1540 MRR_RR_CAN_DET_Near_TARGET_031 "Near_Target_Discrimination";
BA_ "SignalDescription" SG_ 1540 MRR_RR_CAN_DET_Near_TARGET_032 "Near_Target_Discrimination";
BA_ "SignalDescription" SG_ 1540 MRR_RR_CAN_DET_Near_TARGET_033 "Near_Target_Discrimination";
BA_ "SignalDescription" SG_ 1540 MRR_RR_CAN_DET_Near_TARGET_034 "Near_Target_Discrimination";
BA_ "SignalDescription" SG_ 1540 MRR_RR_CAN_DET_Near_TARGET_035 "Near_Target_Discrimination";
BA_ "GenSigCmt" SG_ 1540 MRR_RR_CAN_DET_ELEVATION_029 "Detected object elevation position";
BA_ "GenSigStartValue" SG_ 1540 MRR_RR_CAN_DET_ELEVATION_029 63.8646288209607;
BA_ "GenSigVtEn" SG_ 1540 MRR_RR_CAN_DET_CONFID_AZIMU_0025 "TRUE";
BA_ "GenSigCmt" SG_ 1540 MRR_RR_CAN_DET_CONFID_AZIMU_0025 "Signal to noise level";
BA_ "SystemSignalLongSymbol" SG_ 1540 MRR_RR_CAN_DET_CONFID_AZIMU_0025 "MRR_RR_CAN_DET_CONFID_AZIMUTH_029";
BA_ "GenSigCmt" SG_ 1540 MRR_RR_CAN_DET_SUPER_RES_TA_0027 "Super resolution target";
BA_ "SystemSignalLongSymbol" SG_ 1540 MRR_RR_CAN_DET_SUPER_RES_TA_0027 "MRR_RR_CAN_DET_SUPER_RES_TARGET_029";
BA_ "GenSigCmt" SG_ 1540 MRR_RR_CAN_DET_CONFID_ELEVA_0027 "Elevation Angle Confidence";
BA_ "SystemSignalLongSymbol" SG_ 1540 MRR_RR_CAN_DET_CONFID_ELEVA_0027 "MRR_RR_CAN_DET_CONFID_ELEVATION_029";
BA_ "GenSigCmt" SG_ 1540 MRR_RR_CAN_DET_HOST_VEH_CLU_0027 "Host vehicle clutter";
BA_ "SystemSignalLongSymbol" SG_ 1540 MRR_RR_CAN_DET_HOST_VEH_CLU_0027 "MRR_RR_CAN_DET_HOST_VEH_CLUTTER_029";
BA_ "GenSigCmt" SG_ 1540 MRR_RR_CAN_DET_VALID_LEVEL_029 "Detected object valid level";
BA_ "GenSigCmt" SG_ 1540 MRR_RR_CAN_DET_AZIMUTH_029 "Detected object azimuth position";
BA_ "GenSigStartValue" SG_ 1540 MRR_RR_CAN_DET_AZIMUTH_029 8194.05320813772;
BA_ "GenSigCmt" SG_ 1540 MRR_RR_CAN_DET_RANGE_029 "Detected object range";
BA_ "GenSigCmt" SG_ 1540 MRR_RR_CAN_DET_RANGE_RATE_029 "Detected object range rate";
BA_ "GenSigStartValue" SG_ 1540 MRR_RR_CAN_DET_RANGE_RATE_029 8192;
BA_ "GenSigCmt" SG_ 1540 MRR_RR_CAN_DET_AMPLITUDE_029 "Detected object amplitude";
BA_ "GenSigStartValue" SG_ 1540 MRR_RR_CAN_DET_AMPLITUDE_029 64;
BA_ "GenSigCmt" SG_ 1540 MRR_RR_CAN_SCAN_INDEX_2LSB_029 "The two LSB of scan index";
BA_ "GenSigStartValue" SG_ 1540 MRR_RR_CAN_DET_ELEVATION_035 63.8646288209607;
BA_ "GenSigCmt" SG_ 1540 MRR_RR_CAN_DET_ELEVATION_035 "Detected object elevation position";
BA_ "GenSigCmt" SG_ 1540 MRR_RR_CAN_DET_SUPER_RES_TA_0028 "Super resolution target";
BA_ "SystemSignalLongSymbol" SG_ 1540 MRR_RR_CAN_DET_SUPER_RES_TA_0028 "MRR_RR_CAN_DET_SUPER_RES_TARGET_035";
BA_ "GenSigCmt" SG_ 1540 MRR_RR_CAN_DET_AZIMUTH_035 "Detected object azimuth position";
BA_ "GenSigStartValue" SG_ 1540 MRR_RR_CAN_DET_AZIMUTH_035 8194.05320813772;
BA_ "GenSigCmt" SG_ 1540 MRR_RR_CAN_DET_CONFID_ELEVA_0028 "Elevation Angle Confidence";
BA_ "SystemSignalLongSymbol" SG_ 1540 MRR_RR_CAN_DET_CONFID_ELEVA_0028 "MRR_RR_CAN_DET_CONFID_ELEVATION_035";
BA_ "GenSigCmt" SG_ 1540 MRR_RR_CAN_DET_HOST_VEH_CLU_0028 "Host vehicle clutter";
BA_ "SystemSignalLongSymbol" SG_ 1540 MRR_RR_CAN_DET_HOST_VEH_CLU_0028 "MRR_RR_CAN_DET_HOST_VEH_CLUTTER_035";
BA_ "GenSigCmt" SG_ 1540 MRR_RR_CAN_DET_RANGE_035 "Detected object range";
BA_ "GenSigVtEn" SG_ 1540 MRR_RR_CAN_DET_CONFID_AZIMUTH_03 "TRUE";
BA_ "GenSigCmt" SG_ 1540 MRR_RR_CAN_DET_CONFID_AZIMUTH_03 "Signal to noise level";
BA_ "SystemSignalLongSymbol" SG_ 1540 MRR_RR_CAN_DET_CONFID_AZIMUTH_03 "MRR_RR_CAN_DET_CONFID_AZIMUTH_035";
BA_ "GenSigCmt" SG_ 1540 MRR_RR_CAN_DET_RANGE_RATE_035 "Detected object range rate";
BA_ "GenSigStartValue" SG_ 1540 MRR_RR_CAN_DET_RANGE_RATE_035 8192;
BA_ "GenSigCmt" SG_ 1540 MRR_RR_CAN_SCAN_INDEX_2LSB_035 "The two LSB of scan index";
BA_ "GenSigCmt" SG_ 1540 MRR_RR_CAN_DET_AMPLITUDE_035 "Detected object amplitude";
BA_ "GenSigStartValue" SG_ 1540 MRR_RR_CAN_DET_AMPLITUDE_035 64;
BA_ "GenSigCmt" SG_ 1540 MRR_RR_CAN_DET_VALID_LEVEL_035 "Detected object valid level";
BA_ "GenSigCmt" SG_ 1540 MRR_RR_CAN_DET_ELEVATION_034 "Detected object elevation position";
BA_ "GenSigStartValue" SG_ 1540 MRR_RR_CAN_DET_ELEVATION_034 63.8646288209607;
BA_ "GenSigCmt" SG_ 1540 MRR_RR_CAN_DET_SUPER_RES_TA_0029 "Super resolution target";
BA_ "SystemSignalLongSymbol" SG_ 1540 MRR_RR_CAN_DET_SUPER_RES_TA_0029 "MRR_RR_CAN_DET_SUPER_RES_TARGET_034";
BA_ "GenSigCmt" SG_ 1540 MRR_RR_CAN_DET_AZIMUTH_034 "Detected object azimuth position";
BA_ "GenSigStartValue" SG_ 1540 MRR_RR_CAN_DET_AZIMUTH_034 8194.05320813772;
BA_ "GenSigCmt" SG_ 1540 MRR_RR_CAN_DET_CONFID_ELEVA_0029 "Elevation Angle Confidence";
BA_ "SystemSignalLongSymbol" SG_ 1540 MRR_RR_CAN_DET_CONFID_ELEVA_0029 "MRR_RR_CAN_DET_CONFID_ELEVATION_034";
BA_ "GenSigCmt" SG_ 1540 MRR_RR_CAN_DET_HOST_VEH_CLU_0029 "Host vehicle clutter";
BA_ "SystemSignalLongSymbol" SG_ 1540 MRR_RR_CAN_DET_HOST_VEH_CLU_0029 "MRR_RR_CAN_DET_HOST_VEH_CLUTTER_034";
BA_ "GenSigCmt" SG_ 1540 MRR_RR_CAN_DET_RANGE_034 "Detected object range";
BA_ "GenSigVtEn" SG_ 1540 MRR_RR_CAN_DET_CONFID_AZIMU_0026 "TRUE";
BA_ "GenSigCmt" SG_ 1540 MRR_RR_CAN_DET_CONFID_AZIMU_0026 "Signal to noise level";
BA_ "SystemSignalLongSymbol" SG_ 1540 MRR_RR_CAN_DET_CONFID_AZIMU_0026 "MRR_RR_CAN_DET_CONFID_AZIMUTH_034";
BA_ "GenSigCmt" SG_ 1540 MRR_RR_CAN_DET_RANGE_RATE_034 "Detected object range rate";
BA_ "GenSigStartValue" SG_ 1540 MRR_RR_CAN_DET_RANGE_RATE_034 8192;
BA_ "GenSigCmt" SG_ 1540 MRR_RR_CAN_SCAN_INDEX_2LSB_034 "The two LSB of scan index";
BA_ "GenSigCmt" SG_ 1540 MRR_RR_CAN_DET_AMPLITUDE_034 "Detected object amplitude";
BA_ "GenSigStartValue" SG_ 1540 MRR_RR_CAN_DET_AMPLITUDE_034 64;
BA_ "GenSigCmt" SG_ 1540 MRR_RR_CAN_DET_VALID_LEVEL_034 "Detected object valid level";
BA_ "GenSigCmt" SG_ 1540 MRR_RR_CAN_DET_ELEVATION_033 "Detected object elevation position";
BA_ "GenSigStartValue" SG_ 1540 MRR_RR_CAN_DET_ELEVATION_033 63.8646288209607;
BA_ "GenSigCmt" SG_ 1540 MRR_RR_CAN_DET_SUPER_RES_TA_0030 "Super resolution target";
BA_ "SystemSignalLongSymbol" SG_ 1540 MRR_RR_CAN_DET_SUPER_RES_TA_0030 "MRR_RR_CAN_DET_SUPER_RES_TARGET_033";
BA_ "GenSigCmt" SG_ 1540 MRR_RR_CAN_DET_AZIMUTH_033 "Detected object azimuth position";
BA_ "GenSigStartValue" SG_ 1540 MRR_RR_CAN_DET_AZIMUTH_033 8194.05320813772;
BA_ "GenSigCmt" SG_ 1540 MRR_RR_CAN_DET_CONFID_ELEVA_0030 "Elevation Angle Confidence";
BA_ "SystemSignalLongSymbol" SG_ 1540 MRR_RR_CAN_DET_CONFID_ELEVA_0030 "MRR_RR_CAN_DET_CONFID_ELEVATION_033";
BA_ "GenSigCmt" SG_ 1540 MRR_RR_CAN_DET_HOST_VEH_CLU_0030 "Host vehicle clutter";
BA_ "SystemSignalLongSymbol" SG_ 1540 MRR_RR_CAN_DET_HOST_VEH_CLU_0030 "MRR_RR_CAN_DET_HOST_VEH_CLUTTER_033";
BA_ "GenSigCmt" SG_ 1540 MRR_RR_CAN_DET_RANGE_033 "Detected object range";
BA_ "GenSigVtEn" SG_ 1540 MRR_RR_CAN_DET_CONFID_AZIMU_0027 "TRUE";
BA_ "GenSigCmt" SG_ 1540 MRR_RR_CAN_DET_CONFID_AZIMU_0027 "Signal to noise level";
BA_ "SystemSignalLongSymbol" SG_ 1540 MRR_RR_CAN_DET_CONFID_AZIMU_0027 "MRR_RR_CAN_DET_CONFID_AZIMUTH_033";
BA_ "GenSigCmt" SG_ 1540 MRR_RR_CAN_DET_RANGE_RATE_033 "Detected object range rate";
BA_ "GenSigStartValue" SG_ 1540 MRR_RR_CAN_DET_RANGE_RATE_033 8192;
BA_ "GenSigCmt" SG_ 1540 MRR_RR_CAN_SCAN_INDEX_2LSB_033 "The two LSB of scan index";
BA_ "GenSigCmt" SG_ 1540 MRR_RR_CAN_DET_AMPLITUDE_033 "Detected object amplitude";
BA_ "GenSigStartValue" SG_ 1540 MRR_RR_CAN_DET_AMPLITUDE_033 64;
BA_ "GenSigCmt" SG_ 1540 MRR_RR_CAN_DET_VALID_LEVEL_033 "Detected object valid level";
BA_ "GenSigCmt" SG_ 1540 MRR_RR_CAN_DET_ELEVATION_032 "Detected object elevation position";
BA_ "GenSigStartValue" SG_ 1540 MRR_RR_CAN_DET_ELEVATION_032 63.8646288209607;
BA_ "GenSigCmt" SG_ 1540 MRR_RR_CAN_DET_SUPER_RES_TA_0031 "Super resolution target";
BA_ "SystemSignalLongSymbol" SG_ 1540 MRR_RR_CAN_DET_SUPER_RES_TA_0031 "MRR_RR_CAN_DET_SUPER_RES_TARGET_032";
BA_ "GenSigCmt" SG_ 1540 MRR_RR_CAN_DET_AZIMUTH_032 "Detected object azimuth position";
BA_ "GenSigStartValue" SG_ 1540 MRR_RR_CAN_DET_AZIMUTH_032 8194.05320813772;
BA_ "GenSigCmt" SG_ 1540 MRR_RR_CAN_DET_CONFID_ELEVA_0031 "Elevation Angle Confidence";
BA_ "SystemSignalLongSymbol" SG_ 1540 MRR_RR_CAN_DET_CONFID_ELEVA_0031 "MRR_RR_CAN_DET_CONFID_ELEVATION_032";
BA_ "GenSigCmt" SG_ 1540 MRR_RR_CAN_DET_HOST_VEH_CLU_0031 "Host vehicle clutter";
BA_ "SystemSignalLongSymbol" SG_ 1540 MRR_RR_CAN_DET_HOST_VEH_CLU_0031 "MRR_RR_CAN_DET_HOST_VEH_CLUTTER_032";
BA_ "GenSigCmt" SG_ 1540 MRR_RR_CAN_DET_RANGE_032 "Detected object range";
BA_ "GenSigVtEn" SG_ 1540 MRR_RR_CAN_DET_CONFID_AZIMU_0028 "TRUE";
BA_ "GenSigCmt" SG_ 1540 MRR_RR_CAN_DET_CONFID_AZIMU_0028 "Signal to noise level";
BA_ "SystemSignalLongSymbol" SG_ 1540 MRR_RR_CAN_DET_CONFID_AZIMU_0028 "MRR_RR_CAN_DET_CONFID_AZIMUTH_032";
BA_ "GenSigCmt" SG_ 1540 MRR_RR_CAN_DET_RANGE_RATE_032 "Detected object range rate";
BA_ "GenSigStartValue" SG_ 1540 MRR_RR_CAN_DET_RANGE_RATE_032 8192;
BA_ "GenSigCmt" SG_ 1540 MRR_RR_CAN_SCAN_INDEX_2LSB_032 "The two LSB of scan index";
BA_ "GenSigCmt" SG_ 1540 MRR_RR_CAN_DET_AMPLITUDE_032 "Detected object amplitude";
BA_ "GenSigStartValue" SG_ 1540 MRR_RR_CAN_DET_AMPLITUDE_032 64;
BA_ "GenSigCmt" SG_ 1540 MRR_RR_CAN_DET_VALID_LEVEL_032 "Detected object valid level";
BA_ "GenSigCmt" SG_ 1540 MRR_RR_CAN_DET_ELEVATION_031 "Detected object elevation position";
BA_ "GenSigStartValue" SG_ 1540 MRR_RR_CAN_DET_ELEVATION_031 63.8646288209607;
BA_ "GenSigCmt" SG_ 1540 MRR_RR_CAN_DET_SUPER_RES_TA_0032 "Super resolution target";
BA_ "SystemSignalLongSymbol" SG_ 1540 MRR_RR_CAN_DET_SUPER_RES_TA_0032 "MRR_RR_CAN_DET_SUPER_RES_TARGET_031";
BA_ "GenSigCmt" SG_ 1540 MRR_RR_CAN_DET_AZIMUTH_031 "Detected object azimuth position";
BA_ "GenSigStartValue" SG_ 1540 MRR_RR_CAN_DET_AZIMUTH_031 8194.05320813772;
BA_ "GenSigCmt" SG_ 1540 MRR_RR_CAN_DET_CONFID_ELEVA_0032 "Elevation Angle Confidence";
BA_ "SystemSignalLongSymbol" SG_ 1540 MRR_RR_CAN_DET_CONFID_ELEVA_0032 "MRR_RR_CAN_DET_CONFID_ELEVATION_031";
BA_ "GenSigCmt" SG_ 1540 MRR_RR_CAN_DET_HOST_VEH_CLU_0032 "Host vehicle clutter";
BA_ "SystemSignalLongSymbol" SG_ 1540 MRR_RR_CAN_DET_HOST_VEH_CLU_0032 "MRR_RR_CAN_DET_HOST_VEH_CLUTTER_031";
BA_ "GenSigCmt" SG_ 1540 MRR_RR_CAN_DET_RANGE_031 "Detected object range";
BA_ "GenSigVtEn" SG_ 1540 MRR_RR_CAN_DET_CONFID_AZIMU_0029 "TRUE";
BA_ "GenSigCmt" SG_ 1540 MRR_RR_CAN_DET_CONFID_AZIMU_0029 "Signal to noise level";
BA_ "SystemSignalLongSymbol" SG_ 1540 MRR_RR_CAN_DET_CONFID_AZIMU_0029 "MRR_RR_CAN_DET_CONFID_AZIMUTH_031";
BA_ "GenSigCmt" SG_ 1540 MRR_RR_CAN_DET_RANGE_RATE_031 "Detected object range rate";
BA_ "GenSigStartValue" SG_ 1540 MRR_RR_CAN_DET_RANGE_RATE_031 8192;
BA_ "GenSigCmt" SG_ 1540 MRR_RR_CAN_SCAN_INDEX_2LSB_031 "The two LSB of scan index";
BA_ "GenSigCmt" SG_ 1540 MRR_RR_CAN_DET_AMPLITUDE_031 "Detected object amplitude";
BA_ "GenSigStartValue" SG_ 1540 MRR_RR_CAN_DET_AMPLITUDE_031 64;
BA_ "GenSigCmt" SG_ 1540 MRR_RR_CAN_DET_VALID_LEVEL_031 "Detected object valid level";
BA_ "GenSigCmt" SG_ 1540 MRR_RR_CAN_DET_ELEVATION_030 "Detected object elevation position";
BA_ "GenSigStartValue" SG_ 1540 MRR_RR_CAN_DET_ELEVATION_030 63.8646288209607;
BA_ "GenSigCmt" SG_ 1540 MRR_RR_CAN_DET_SUPER_RES_TA_0033 "Super resolution target";
BA_ "SystemSignalLongSymbol" SG_ 1540 MRR_RR_CAN_DET_SUPER_RES_TA_0033 "MRR_RR_CAN_DET_SUPER_RES_TARGET_030";
BA_ "GenSigCmt" SG_ 1540 MRR_RR_CAN_DET_AZIMUTH_030 "Detected object azimuth position";
BA_ "GenSigStartValue" SG_ 1540 MRR_RR_CAN_DET_AZIMUTH_030 8194.05320813772;
BA_ "GenSigCmt" SG_ 1540 MRR_RR_CAN_DET_CONFID_ELEVA_0033 "Elevation Angle Confidence";
BA_ "SystemSignalLongSymbol" SG_ 1540 MRR_RR_CAN_DET_CONFID_ELEVA_0033 "MRR_RR_CAN_DET_CONFID_ELEVATION_030";
BA_ "GenSigCmt" SG_ 1540 MRR_RR_CAN_DET_HOST_VEH_CLU_0033 "Host vehicle clutter";
BA_ "SystemSignalLongSymbol" SG_ 1540 MRR_RR_CAN_DET_HOST_VEH_CLU_0033 "MRR_RR_CAN_DET_HOST_VEH_CLUTTER_030";
BA_ "GenSigCmt" SG_ 1540 MRR_RR_CAN_DET_RANGE_030 "Detected object range";
BA_ "GenSigVtEn" SG_ 1540 MRR_RR_CAN_DET_CONFID_AZIMU_0030 "TRUE";
BA_ "GenSigCmt" SG_ 1540 MRR_RR_CAN_DET_CONFID_AZIMU_0030 "Signal to noise level";
BA_ "SystemSignalLongSymbol" SG_ 1540 MRR_RR_CAN_DET_CONFID_AZIMU_0030 "MRR_RR_CAN_DET_CONFID_AZIMUTH_030";
BA_ "GenSigCmt" SG_ 1540 MRR_RR_CAN_DET_RANGE_RATE_030 "Detected object range rate";
BA_ "GenSigStartValue" SG_ 1540 MRR_RR_CAN_DET_RANGE_RATE_030 8192;
BA_ "GenSigCmt" SG_ 1540 MRR_RR_CAN_SCAN_INDEX_2LSB_030 "The two LSB of scan index";
BA_ "GenSigCmt" SG_ 1540 MRR_RR_CAN_DET_AMPLITUDE_030 "Detected object amplitude";
BA_ "GenSigStartValue" SG_ 1540 MRR_RR_CAN_DET_AMPLITUDE_030 64;
BA_ "GenSigCmt" SG_ 1540 MRR_RR_CAN_DET_VALID_LEVEL_030 "Detected object valid level";
BA_ "GenSigSendType" SG_ 1541 MRR_RR_CAN_DET_MID_TARGET_042 1;
BA_ "SignalDescription" SG_ 1541 MRR_RR_CAN_DET_MID_TARGET_042 "MID_Target_Discrimination";
BA_ "SignalDescription" SG_ 1541 MRR_RR_CAN_DET_MID_TARGET_041 "MID_Target_Discrimination";
BA_ "SignalDescription" SG_ 1541 MRR_RR_CAN_DET_MID_TARGET_040 "MID_Target_Discrimination";
BA_ "SignalDescription" SG_ 1541 MRR_RR_CAN_DET_MID_TARGET_039 "MID_Target_Discrimination";
BA_ "SignalDescription" SG_ 1541 MRR_RR_CAN_DET_MID_TARGET_038 "MID_Target_Discrimination";
BA_ "SignalDescription" SG_ 1541 MRR_RR_CAN_DET_MID_TARGET_037 "MID_Target_Discrimination";
BA_ "SignalDescription" SG_ 1541 MRR_RR_CAN_DET_MID_TARGET_036 "MID_Target_Discrimination";
BA_ "SignalDescription" SG_ 1541 MRR_RR_CAN_DET_Near_TARGET_036 "Near_Target_Discrimination";
BA_ "SignalDescription" SG_ 1541 MRR_RR_CAN_DET_Near_TARGET_037 "Near_Target_Discrimination";
BA_ "SignalDescription" SG_ 1541 MRR_RR_CAN_DET_Near_TARGET_038 "Near_Target_Discrimination";
BA_ "SignalDescription" SG_ 1541 MRR_RR_CAN_DET_Near_TARGET_039 "Near_Target_Discrimination";
BA_ "SignalDescription" SG_ 1541 MRR_RR_CAN_DET_Near_TARGET_040 "Near_Target_Discrimination";
BA_ "SignalDescription" SG_ 1541 MRR_RR_CAN_DET_Near_TARGET_041 "Near_Target_Discrimination";
BA_ "SignalDescription" SG_ 1541 MRR_RR_CAN_DET_Near_TARGET_042 "Near_Target_Discrimination";
BA_ "GenSigCmt" SG_ 1541 MRR_RR_CAN_DET_ELEVATION_036 "Detected object elevation position";
BA_ "GenSigStartValue" SG_ 1541 MRR_RR_CAN_DET_ELEVATION_036 63.8646288209607;
BA_ "GenSigVtEn" SG_ 1541 MRR_RR_CAN_DET_CONFID_AZIMU_0031 "TRUE";
BA_ "GenSigCmt" SG_ 1541 MRR_RR_CAN_DET_CONFID_AZIMU_0031 "Signal to noise level";
BA_ "SystemSignalLongSymbol" SG_ 1541 MRR_RR_CAN_DET_CONFID_AZIMU_0031 "MRR_RR_CAN_DET_CONFID_AZIMUTH_036";
BA_ "GenSigCmt" SG_ 1541 MRR_RR_CAN_DET_SUPER_RES_TA_0034 "Super resolution target";
BA_ "SystemSignalLongSymbol" SG_ 1541 MRR_RR_CAN_DET_SUPER_RES_TA_0034 "MRR_RR_CAN_DET_SUPER_RES_TARGET_036";
BA_ "GenSigCmt" SG_ 1541 MRR_RR_CAN_DET_CONFID_ELEVA_0034 "Elevation Angle Confidence";
BA_ "SystemSignalLongSymbol" SG_ 1541 MRR_RR_CAN_DET_CONFID_ELEVA_0034 "MRR_RR_CAN_DET_CONFID_ELEVATION_036";
BA_ "GenSigCmt" SG_ 1541 MRR_RR_CAN_DET_HOST_VEH_CLU_0034 "Host vehicle clutter";
BA_ "SystemSignalLongSymbol" SG_ 1541 MRR_RR_CAN_DET_HOST_VEH_CLU_0034 "MRR_RR_CAN_DET_HOST_VEH_CLUTTER_036";
BA_ "GenSigCmt" SG_ 1541 MRR_RR_CAN_DET_VALID_LEVEL_036 "Detected object valid level";
BA_ "GenSigCmt" SG_ 1541 MRR_RR_CAN_DET_AZIMUTH_036 "Detected object azimuth position";
BA_ "GenSigStartValue" SG_ 1541 MRR_RR_CAN_DET_AZIMUTH_036 8194.05320813772;
BA_ "GenSigCmt" SG_ 1541 MRR_RR_CAN_DET_RANGE_036 "Detected object range";
BA_ "GenSigCmt" SG_ 1541 MRR_RR_CAN_DET_RANGE_RATE_036 "Detected object range rate";
BA_ "GenSigStartValue" SG_ 1541 MRR_RR_CAN_DET_RANGE_RATE_036 8192;
BA_ "GenSigCmt" SG_ 1541 MRR_RR_CAN_DET_AMPLITUDE_036 "Detected object amplitude";
BA_ "GenSigStartValue" SG_ 1541 MRR_RR_CAN_DET_AMPLITUDE_036 64;
BA_ "GenSigCmt" SG_ 1541 MRR_RR_CAN_SCAN_INDEX_2LSB_036 "The two LSB of scan index";
BA_ "GenSigStartValue" SG_ 1541 MRR_RR_CAN_DET_ELEVATION_042 63.8646288209607;
BA_ "GenSigCmt" SG_ 1541 MRR_RR_CAN_DET_ELEVATION_042 "Detected object elevation position";
BA_ "GenSigCmt" SG_ 1541 MRR_RR_CAN_DET_SUPER_RES_TA_0035 "Super resolution target";
BA_ "SystemSignalLongSymbol" SG_ 1541 MRR_RR_CAN_DET_SUPER_RES_TA_0035 "MRR_RR_CAN_DET_SUPER_RES_TARGET_042";
BA_ "GenSigCmt" SG_ 1541 MRR_RR_CAN_DET_AZIMUTH_042 "Detected object azimuth position";
BA_ "GenSigStartValue" SG_ 1541 MRR_RR_CAN_DET_AZIMUTH_042 8194.05320813772;
BA_ "GenSigCmt" SG_ 1541 MRR_RR_CAN_DET_CONFID_ELEVA_0035 "Elevation Angle Confidence";
BA_ "SystemSignalLongSymbol" SG_ 1541 MRR_RR_CAN_DET_CONFID_ELEVA_0035 "MRR_RR_CAN_DET_CONFID_ELEVATION_042";
BA_ "GenSigCmt" SG_ 1541 MRR_RR_CAN_DET_HOST_VEH_CLU_0035 "Host vehicle clutter";
BA_ "SystemSignalLongSymbol" SG_ 1541 MRR_RR_CAN_DET_HOST_VEH_CLU_0035 "MRR_RR_CAN_DET_HOST_VEH_CLUTTER_042";
BA_ "GenSigCmt" SG_ 1541 MRR_RR_CAN_DET_RANGE_042 "Detected object range";
BA_ "GenSigVtEn" SG_ 1541 MRR_RR_CAN_DET_CONFID_AZIMUTH_04 "TRUE";
BA_ "GenSigCmt" SG_ 1541 MRR_RR_CAN_DET_CONFID_AZIMUTH_04 "Signal to noise level";
BA_ "SystemSignalLongSymbol" SG_ 1541 MRR_RR_CAN_DET_CONFID_AZIMUTH_04 "MRR_RR_CAN_DET_CONFID_AZIMUTH_042";
BA_ "GenSigCmt" SG_ 1541 MRR_RR_CAN_DET_RANGE_RATE_042 "Detected object range rate";
BA_ "GenSigStartValue" SG_ 1541 MRR_RR_CAN_DET_RANGE_RATE_042 8192;
BA_ "GenSigCmt" SG_ 1541 MRR_RR_CAN_SCAN_INDEX_2LSB_042 "The two LSB of scan index";
BA_ "GenSigCmt" SG_ 1541 MRR_RR_CAN_DET_AMPLITUDE_042 "Detected object amplitude";
BA_ "GenSigStartValue" SG_ 1541 MRR_RR_CAN_DET_AMPLITUDE_042 64;
BA_ "GenSigCmt" SG_ 1541 MRR_RR_CAN_DET_VALID_LEVEL_042 "Detected object valid level";
BA_ "GenSigCmt" SG_ 1541 MRR_RR_CAN_DET_ELEVATION_041 "Detected object elevation position";
BA_ "GenSigStartValue" SG_ 1541 MRR_RR_CAN_DET_ELEVATION_041 63.8646288209607;
BA_ "GenSigCmt" SG_ 1541 MRR_RR_CAN_DET_SUPER_RES_TA_0036 "Super resolution target";
BA_ "SystemSignalLongSymbol" SG_ 1541 MRR_RR_CAN_DET_SUPER_RES_TA_0036 "MRR_RR_CAN_DET_SUPER_RES_TARGET_041";
BA_ "GenSigCmt" SG_ 1541 MRR_RR_CAN_DET_AZIMUTH_041 "Detected object azimuth position";
BA_ "GenSigStartValue" SG_ 1541 MRR_RR_CAN_DET_AZIMUTH_041 8194.05320813772;
BA_ "GenSigCmt" SG_ 1541 MRR_RR_CAN_DET_CONFID_ELEVA_0036 "Elevation Angle Confidence";
BA_ "SystemSignalLongSymbol" SG_ 1541 MRR_RR_CAN_DET_CONFID_ELEVA_0036 "MRR_RR_CAN_DET_CONFID_ELEVATION_041";
BA_ "GenSigCmt" SG_ 1541 MRR_RR_CAN_DET_HOST_VEH_CLU_0036 "Host vehicle clutter";
BA_ "SystemSignalLongSymbol" SG_ 1541 MRR_RR_CAN_DET_HOST_VEH_CLU_0036 "MRR_RR_CAN_DET_HOST_VEH_CLUTTER_041";
BA_ "GenSigCmt" SG_ 1541 MRR_RR_CAN_DET_RANGE_041 "Detected object range";
BA_ "GenSigVtEn" SG_ 1541 MRR_RR_CAN_DET_CONFID_AZIMU_0032 "TRUE";
BA_ "GenSigCmt" SG_ 1541 MRR_RR_CAN_DET_CONFID_AZIMU_0032 "Signal to noise level";
BA_ "SystemSignalLongSymbol" SG_ 1541 MRR_RR_CAN_DET_CONFID_AZIMU_0032 "MRR_RR_CAN_DET_CONFID_AZIMUTH_041";
BA_ "GenSigCmt" SG_ 1541 MRR_RR_CAN_DET_RANGE_RATE_041 "Detected object range rate";
BA_ "GenSigStartValue" SG_ 1541 MRR_RR_CAN_DET_RANGE_RATE_041 8192;
BA_ "GenSigCmt" SG_ 1541 MRR_RR_CAN_SCAN_INDEX_2LSB_041 "The two LSB of scan index";
BA_ "GenSigCmt" SG_ 1541 MRR_RR_CAN_DET_AMPLITUDE_041 "Detected object amplitude";
BA_ "GenSigStartValue" SG_ 1541 MRR_RR_CAN_DET_AMPLITUDE_041 64;
BA_ "GenSigCmt" SG_ 1541 MRR_RR_CAN_DET_VALID_LEVEL_041 "Detected object valid level";
BA_ "GenSigCmt" SG_ 1541 MRR_RR_CAN_DET_ELEVATION_040 "Detected object elevation position";
BA_ "GenSigStartValue" SG_ 1541 MRR_RR_CAN_DET_ELEVATION_040 63.8646288209607;
BA_ "GenSigCmt" SG_ 1541 MRR_RR_CAN_DET_SUPER_RES_TA_0037 "Super resolution target";
BA_ "SystemSignalLongSymbol" SG_ 1541 MRR_RR_CAN_DET_SUPER_RES_TA_0037 "MRR_RR_CAN_DET_SUPER_RES_TARGET_040";
BA_ "GenSigCmt" SG_ 1541 MRR_RR_CAN_DET_AZIMUTH_040 "Detected object azimuth position";
BA_ "GenSigStartValue" SG_ 1541 MRR_RR_CAN_DET_AZIMUTH_040 8194.05320813772;
BA_ "GenSigCmt" SG_ 1541 MRR_RR_CAN_DET_CONFID_ELEVA_0037 "Elevation Angle Confidence";
BA_ "SystemSignalLongSymbol" SG_ 1541 MRR_RR_CAN_DET_CONFID_ELEVA_0037 "MRR_RR_CAN_DET_CONFID_ELEVATION_040";
BA_ "GenSigCmt" SG_ 1541 MRR_RR_CAN_DET_HOST_VEH_CLU_0037 "Host vehicle clutter";
BA_ "SystemSignalLongSymbol" SG_ 1541 MRR_RR_CAN_DET_HOST_VEH_CLU_0037 "MRR_RR_CAN_DET_HOST_VEH_CLUTTER_040";
BA_ "GenSigCmt" SG_ 1541 MRR_RR_CAN_DET_RANGE_040 "Detected object range";
BA_ "GenSigVtEn" SG_ 1541 MRR_RR_CAN_DET_CONFID_AZIMU_0033 "TRUE";
BA_ "GenSigCmt" SG_ 1541 MRR_RR_CAN_DET_CONFID_AZIMU_0033 "Signal to noise level";
BA_ "SystemSignalLongSymbol" SG_ 1541 MRR_RR_CAN_DET_CONFID_AZIMU_0033 "MRR_RR_CAN_DET_CONFID_AZIMUTH_040";
BA_ "GenSigCmt" SG_ 1541 MRR_RR_CAN_DET_RANGE_RATE_040 "Detected object range rate";
BA_ "GenSigStartValue" SG_ 1541 MRR_RR_CAN_DET_RANGE_RATE_040 8192;
BA_ "GenSigCmt" SG_ 1541 MRR_RR_CAN_SCAN_INDEX_2LSB_040 "The two LSB of scan index";
BA_ "GenSigCmt" SG_ 1541 MRR_RR_CAN_DET_AMPLITUDE_040 "Detected object amplitude";
BA_ "GenSigStartValue" SG_ 1541 MRR_RR_CAN_DET_AMPLITUDE_040 64;
BA_ "GenSigCmt" SG_ 1541 MRR_RR_CAN_DET_VALID_LEVEL_040 "Detected object valid level";
BA_ "GenSigCmt" SG_ 1541 MRR_RR_CAN_DET_ELEVATION_039 "Detected object elevation position";
BA_ "GenSigStartValue" SG_ 1541 MRR_RR_CAN_DET_ELEVATION_039 63.8646288209607;
BA_ "GenSigCmt" SG_ 1541 MRR_RR_CAN_DET_SUPER_RES_TA_0038 "Super resolution target";
BA_ "SystemSignalLongSymbol" SG_ 1541 MRR_RR_CAN_DET_SUPER_RES_TA_0038 "MRR_RR_CAN_DET_SUPER_RES_TARGET_039";
BA_ "GenSigCmt" SG_ 1541 MRR_RR_CAN_DET_AZIMUTH_039 "Detected object azimuth position";
BA_ "GenSigStartValue" SG_ 1541 MRR_RR_CAN_DET_AZIMUTH_039 8194.05320813772;
BA_ "GenSigCmt" SG_ 1541 MRR_RR_CAN_DET_CONFID_ELEVA_0038 "Elevation Angle Confidence";
BA_ "SystemSignalLongSymbol" SG_ 1541 MRR_RR_CAN_DET_CONFID_ELEVA_0038 "MRR_RR_CAN_DET_CONFID_ELEVATION_039";
BA_ "GenSigCmt" SG_ 1541 MRR_RR_CAN_DET_HOST_VEH_CLU_0038 "Host vehicle clutter";
BA_ "SystemSignalLongSymbol" SG_ 1541 MRR_RR_CAN_DET_HOST_VEH_CLU_0038 "MRR_RR_CAN_DET_HOST_VEH_CLUTTER_039";
BA_ "GenSigCmt" SG_ 1541 MRR_RR_CAN_DET_RANGE_039 "Detected object range";
BA_ "GenSigVtEn" SG_ 1541 MRR_RR_CAN_DET_CONFID_AZIMU_0034 "TRUE";
BA_ "GenSigCmt" SG_ 1541 MRR_RR_CAN_DET_CONFID_AZIMU_0034 "Signal to noise level";
BA_ "SystemSignalLongSymbol" SG_ 1541 MRR_RR_CAN_DET_CONFID_AZIMU_0034 "MRR_RR_CAN_DET_CONFID_AZIMUTH_039";
BA_ "GenSigCmt" SG_ 1541 MRR_RR_CAN_DET_RANGE_RATE_039 "Detected object range rate";
BA_ "GenSigStartValue" SG_ 1541 MRR_RR_CAN_DET_RANGE_RATE_039 8192;
BA_ "GenSigCmt" SG_ 1541 MRR_RR_CAN_SCAN_INDEX_2LSB_039 "The two LSB of scan index";
BA_ "GenSigCmt" SG_ 1541 MRR_RR_CAN_DET_AMPLITUDE_039 "Detected object amplitude";
BA_ "GenSigStartValue" SG_ 1541 MRR_RR_CAN_DET_AMPLITUDE_039 64;
BA_ "GenSigCmt" SG_ 1541 MRR_RR_CAN_DET_VALID_LEVEL_039 "Detected object valid level";
BA_ "GenSigCmt" SG_ 1541 MRR_RR_CAN_DET_ELEVATION_038 "Detected object elevation position";
BA_ "GenSigStartValue" SG_ 1541 MRR_RR_CAN_DET_ELEVATION_038 63.8646288209607;
BA_ "GenSigCmt" SG_ 1541 MRR_RR_CAN_DET_SUPER_RES_TA_0039 "Super resolution target";
BA_ "SystemSignalLongSymbol" SG_ 1541 MRR_RR_CAN_DET_SUPER_RES_TA_0039 "MRR_RR_CAN_DET_SUPER_RES_TARGET_038";
BA_ "GenSigCmt" SG_ 1541 MRR_RR_CAN_DET_AZIMUTH_038 "Detected object azimuth position";
BA_ "GenSigStartValue" SG_ 1541 MRR_RR_CAN_DET_AZIMUTH_038 8194.05320813772;
BA_ "GenSigCmt" SG_ 1541 MRR_RR_CAN_DET_CONFID_ELEVA_0039 "Elevation Angle Confidence";
BA_ "SystemSignalLongSymbol" SG_ 1541 MRR_RR_CAN_DET_CONFID_ELEVA_0039 "MRR_RR_CAN_DET_CONFID_ELEVATION_038";
BA_ "GenSigCmt" SG_ 1541 MRR_RR_CAN_DET_HOST_VEH_CLU_0039 "Host vehicle clutter";
BA_ "SystemSignalLongSymbol" SG_ 1541 MRR_RR_CAN_DET_HOST_VEH_CLU_0039 "MRR_RR_CAN_DET_HOST_VEH_CLUTTER_038";
BA_ "GenSigCmt" SG_ 1541 MRR_RR_CAN_DET_RANGE_038 "Detected object range";
BA_ "GenSigVtEn" SG_ 1541 MRR_RR_CAN_DET_CONFID_AZIMU_0035 "TRUE";
BA_ "GenSigCmt" SG_ 1541 MRR_RR_CAN_DET_CONFID_AZIMU_0035 "Signal to noise level";
BA_ "SystemSignalLongSymbol" SG_ 1541 MRR_RR_CAN_DET_CONFID_AZIMU_0035 "MRR_RR_CAN_DET_CONFID_AZIMUTH_038";
BA_ "GenSigCmt" SG_ 1541 MRR_RR_CAN_DET_RANGE_RATE_038 "Detected object range rate";
BA_ "GenSigStartValue" SG_ 1541 MRR_RR_CAN_DET_RANGE_RATE_038 8192;
BA_ "GenSigCmt" SG_ 1541 MRR_RR_CAN_SCAN_INDEX_2LSB_038 "The two LSB of scan index";
BA_ "GenSigCmt" SG_ 1541 MRR_RR_CAN_DET_AMPLITUDE_038 "Detected object amplitude";
BA_ "GenSigStartValue" SG_ 1541 MRR_RR_CAN_DET_AMPLITUDE_038 64;
BA_ "GenSigCmt" SG_ 1541 MRR_RR_CAN_DET_VALID_LEVEL_038 "Detected object valid level";
BA_ "GenSigCmt" SG_ 1541 MRR_RR_CAN_DET_ELEVATION_037 "Detected object elevation position";
BA_ "GenSigStartValue" SG_ 1541 MRR_RR_CAN_DET_ELEVATION_037 63.8646288209607;
BA_ "GenSigCmt" SG_ 1541 MRR_RR_CAN_DET_SUPER_RES_TA_0040 "Super resolution target";
BA_ "SystemSignalLongSymbol" SG_ 1541 MRR_RR_CAN_DET_SUPER_RES_TA_0040 "MRR_RR_CAN_DET_SUPER_RES_TARGET_037";
BA_ "GenSigCmt" SG_ 1541 MRR_RR_CAN_DET_AZIMUTH_037 "Detected object azimuth position";
BA_ "GenSigStartValue" SG_ 1541 MRR_RR_CAN_DET_AZIMUTH_037 8194.05320813772;
BA_ "GenSigCmt" SG_ 1541 MRR_RR_CAN_DET_CONFID_ELEVA_0040 "Elevation Angle Confidence";
BA_ "SystemSignalLongSymbol" SG_ 1541 MRR_RR_CAN_DET_CONFID_ELEVA_0040 "MRR_RR_CAN_DET_CONFID_ELEVATION_037";
BA_ "GenSigCmt" SG_ 1541 MRR_RR_CAN_DET_HOST_VEH_CLU_0040 "Host vehicle clutter";
BA_ "SystemSignalLongSymbol" SG_ 1541 MRR_RR_CAN_DET_HOST_VEH_CLU_0040 "MRR_RR_CAN_DET_HOST_VEH_CLUTTER_037";
BA_ "GenSigCmt" SG_ 1541 MRR_RR_CAN_DET_RANGE_037 "Detected object range";
BA_ "GenSigVtEn" SG_ 1541 MRR_RR_CAN_DET_CONFID_AZIMU_0036 "TRUE";
BA_ "GenSigCmt" SG_ 1541 MRR_RR_CAN_DET_CONFID_AZIMU_0036 "Signal to noise level";
BA_ "SystemSignalLongSymbol" SG_ 1541 MRR_RR_CAN_DET_CONFID_AZIMU_0036 "MRR_RR_CAN_DET_CONFID_AZIMUTH_037";
BA_ "GenSigCmt" SG_ 1541 MRR_RR_CAN_DET_RANGE_RATE_037 "Detected object range rate";
BA_ "GenSigStartValue" SG_ 1541 MRR_RR_CAN_DET_RANGE_RATE_037 8192;
BA_ "GenSigCmt" SG_ 1541 MRR_RR_CAN_SCAN_INDEX_2LSB_037 "The two LSB of scan index";
BA_ "GenSigCmt" SG_ 1541 MRR_RR_CAN_DET_AMPLITUDE_037 "Detected object amplitude";
BA_ "GenSigStartValue" SG_ 1541 MRR_RR_CAN_DET_AMPLITUDE_037 64;
BA_ "GenSigCmt" SG_ 1541 MRR_RR_CAN_DET_VALID_LEVEL_037 "Detected object valid level";
BA_ "GenSigSendType" SG_ 1542 MRR_RR_CAN_DET_MID_TARGET_049 1;
BA_ "SignalDescription" SG_ 1542 MRR_RR_CAN_DET_MID_TARGET_049 "MID_Target_Discrimination";
BA_ "SignalDescription" SG_ 1542 MRR_RR_CAN_DET_MID_TARGET_048 "MID_Target_Discrimination";
BA_ "SignalDescription" SG_ 1542 MRR_RR_CAN_DET_MID_TARGET_047 "MID_Target_Discrimination";
BA_ "SignalDescription" SG_ 1542 MRR_RR_CAN_DET_MID_TARGET_046 "MID_Target_Discrimination";
BA_ "SignalDescription" SG_ 1542 MRR_RR_CAN_DET_MID_TARGET_045 "MID_Target_Discrimination";
BA_ "SignalDescription" SG_ 1542 MRR_RR_CAN_DET_MID_TARGET_044 "MID_Target_Discrimination";
BA_ "SignalDescription" SG_ 1542 MRR_RR_CAN_DET_MID_TARGET_043 "MID_Target_Discrimination";
BA_ "SignalDescription" SG_ 1542 MRR_RR_CAN_DET_Near_TARGET_043 "Near_Target_Discrimination";
BA_ "SignalDescription" SG_ 1542 MRR_RR_CAN_DET_Near_TARGET_044 "Near_Target_Discrimination";
BA_ "SignalDescription" SG_ 1542 MRR_RR_CAN_DET_Near_TARGET_045 "Near_Target_Discrimination";
BA_ "SignalDescription" SG_ 1542 MRR_RR_CAN_DET_Near_TARGET_046 "Near_Target_Discrimination";
BA_ "SignalDescription" SG_ 1542 MRR_RR_CAN_DET_Near_TARGET_047 "Near_Target_Discrimination";
BA_ "SignalDescription" SG_ 1542 MRR_RR_CAN_DET_Near_TARGET_048 "Near_Target_Discrimination";
BA_ "SignalDescription" SG_ 1542 MRR_RR_CAN_DET_Near_TARGET_049 "Near_Target_Discrimination";
BA_ "GenSigCmt" SG_ 1542 MRR_RR_CAN_DET_ELEVATION_043 "Detected object elevation position";
BA_ "GenSigStartValue" SG_ 1542 MRR_RR_CAN_DET_ELEVATION_043 63.8646288209607;
BA_ "GenSigCmt" SG_ 1542 MRR_RR_CAN_DET_CONFID_AZIMU_0037 "Signal to noise level";
BA_ "GenSigVtEn" SG_ 1542 MRR_RR_CAN_DET_CONFID_AZIMU_0037 "TRUE";
BA_ "SystemSignalLongSymbol" SG_ 1542 MRR_RR_CAN_DET_CONFID_AZIMU_0037 "MRR_RR_CAN_DET_CONFID_AZIMUTH_043";
BA_ "GenSigCmt" SG_ 1542 MRR_RR_CAN_DET_SUPER_RES_TA_0041 "Super resolution target";
BA_ "SystemSignalLongSymbol" SG_ 1542 MRR_RR_CAN_DET_SUPER_RES_TA_0041 "MRR_RR_CAN_DET_SUPER_RES_TARGET_043";
BA_ "GenSigCmt" SG_ 1542 MRR_RR_CAN_DET_CONFID_ELEVA_0041 "Elevation Angle Confidence";
BA_ "SystemSignalLongSymbol" SG_ 1542 MRR_RR_CAN_DET_CONFID_ELEVA_0041 "MRR_RR_CAN_DET_CONFID_ELEVATION_043";
BA_ "GenSigCmt" SG_ 1542 MRR_RR_CAN_DET_HOST_VEH_CLU_0041 "Host vehicle clutter";
BA_ "SystemSignalLongSymbol" SG_ 1542 MRR_RR_CAN_DET_HOST_VEH_CLU_0041 "MRR_RR_CAN_DET_HOST_VEH_CLUTTER_043";
BA_ "GenSigCmt" SG_ 1542 MRR_RR_CAN_DET_VALID_LEVEL_043 "Detected object valid level";
BA_ "GenSigCmt" SG_ 1542 MRR_RR_CAN_DET_AZIMUTH_043 "Detected object azimuth position";
BA_ "GenSigStartValue" SG_ 1542 MRR_RR_CAN_DET_AZIMUTH_043 8194.05320813772;
BA_ "GenSigCmt" SG_ 1542 MRR_RR_CAN_DET_RANGE_043 "Detected object range";
BA_ "GenSigCmt" SG_ 1542 MRR_RR_CAN_DET_RANGE_RATE_043 "Detected object range rate";
BA_ "GenSigStartValue" SG_ 1542 MRR_RR_CAN_DET_RANGE_RATE_043 8192;
BA_ "GenSigCmt" SG_ 1542 MRR_RR_CAN_DET_AMPLITUDE_043 "Detected object amplitude";
BA_ "GenSigStartValue" SG_ 1542 MRR_RR_CAN_DET_AMPLITUDE_043 64;
BA_ "GenSigCmt" SG_ 1542 MRR_RR_CAN_SCAN_INDEX_2LSB_043 "The two LSB of scan index";
BA_ "GenSigStartValue" SG_ 1542 MRR_RR_CAN_DET_ELEVATION_049 63.8646288209607;
BA_ "GenSigCmt" SG_ 1542 MRR_RR_CAN_DET_ELEVATION_049 "Detected object elevation position";
BA_ "GenSigCmt" SG_ 1542 MRR_RR_CAN_DET_SUPER_RES_TA_0042 "Super resolution target";
BA_ "SystemSignalLongSymbol" SG_ 1542 MRR_RR_CAN_DET_SUPER_RES_TA_0042 "MRR_RR_CAN_DET_SUPER_RES_TARGET_049";
BA_ "GenSigCmt" SG_ 1542 MRR_RR_CAN_DET_AZIMUTH_049 "Detected object azimuth position";
BA_ "GenSigStartValue" SG_ 1542 MRR_RR_CAN_DET_AZIMUTH_049 8194.05320813772;
BA_ "GenSigCmt" SG_ 1542 MRR_RR_CAN_DET_CONFID_ELEVA_0042 "Elevation Angle Confidence";
BA_ "SystemSignalLongSymbol" SG_ 1542 MRR_RR_CAN_DET_CONFID_ELEVA_0042 "MRR_RR_CAN_DET_CONFID_ELEVATION_049";
BA_ "GenSigCmt" SG_ 1542 MRR_RR_CAN_DET_HOST_VEH_CLU_0042 "Host vehicle clutter";
BA_ "SystemSignalLongSymbol" SG_ 1542 MRR_RR_CAN_DET_HOST_VEH_CLU_0042 "MRR_RR_CAN_DET_HOST_VEH_CLUTTER_049";
BA_ "GenSigCmt" SG_ 1542 MRR_RR_CAN_DET_RANGE_049 "Detected object range";
BA_ "GenSigCmt" SG_ 1542 MRR_RR_CAN_DET_CONFID_AZIMU_0038 "Signal to noise level";
BA_ "GenSigVtEn" SG_ 1542 MRR_RR_CAN_DET_CONFID_AZIMU_0038 "TRUE";
BA_ "SystemSignalLongSymbol" SG_ 1542 MRR_RR_CAN_DET_CONFID_AZIMU_0038 "MRR_RR_CAN_DET_CONFID_AZIMUTH_049";
BA_ "GenSigCmt" SG_ 1542 MRR_RR_CAN_DET_RANGE_RATE_049 "Detected object range rate";
BA_ "GenSigStartValue" SG_ 1542 MRR_RR_CAN_DET_RANGE_RATE_049 8192;
BA_ "GenSigCmt" SG_ 1542 MRR_RR_CAN_SCAN_INDEX_2LSB_049 "The two LSB of scan index";
BA_ "GenSigCmt" SG_ 1542 MRR_RR_CAN_DET_AMPLITUDE_049 "Detected object amplitude";
BA_ "GenSigStartValue" SG_ 1542 MRR_RR_CAN_DET_AMPLITUDE_049 64;
BA_ "GenSigCmt" SG_ 1542 MRR_RR_CAN_DET_VALID_LEVEL_049 "Detected object valid level";
BA_ "GenSigCmt" SG_ 1542 MRR_RR_CAN_DET_ELEVATION_048 "Detected object elevation position";
BA_ "GenSigStartValue" SG_ 1542 MRR_RR_CAN_DET_ELEVATION_048 63.8646288209607;
BA_ "GenSigCmt" SG_ 1542 MRR_RR_CAN_DET_SUPER_RES_TA_0043 "Super resolution target";
BA_ "SystemSignalLongSymbol" SG_ 1542 MRR_RR_CAN_DET_SUPER_RES_TA_0043 "MRR_RR_CAN_DET_SUPER_RES_TARGET_048";
BA_ "GenSigCmt" SG_ 1542 MRR_RR_CAN_DET_AZIMUTH_048 "Detected object azimuth position";
BA_ "GenSigStartValue" SG_ 1542 MRR_RR_CAN_DET_AZIMUTH_048 8194.05320813772;
BA_ "GenSigCmt" SG_ 1542 MRR_RR_CAN_DET_CONFID_ELEVA_0043 "Elevation Angle Confidence";
BA_ "SystemSignalLongSymbol" SG_ 1542 MRR_RR_CAN_DET_CONFID_ELEVA_0043 "MRR_RR_CAN_DET_CONFID_ELEVATION_048";
BA_ "GenSigCmt" SG_ 1542 MRR_RR_CAN_DET_HOST_VEH_CLU_0043 "Host vehicle clutter";
BA_ "SystemSignalLongSymbol" SG_ 1542 MRR_RR_CAN_DET_HOST_VEH_CLU_0043 "MRR_RR_CAN_DET_HOST_VEH_CLUTTER_048";
BA_ "GenSigCmt" SG_ 1542 MRR_RR_CAN_DET_RANGE_048 "Detected object range";
BA_ "GenSigCmt" SG_ 1542 MRR_RR_CAN_DET_CONFID_AZIMU_0039 "Signal to noise level";
BA_ "GenSigVtEn" SG_ 1542 MRR_RR_CAN_DET_CONFID_AZIMU_0039 "TRUE";
BA_ "SystemSignalLongSymbol" SG_ 1542 MRR_RR_CAN_DET_CONFID_AZIMU_0039 "MRR_RR_CAN_DET_CONFID_AZIMUTH_048";
BA_ "GenSigCmt" SG_ 1542 MRR_RR_CAN_DET_RANGE_RATE_048 "Detected object range rate";
BA_ "GenSigStartValue" SG_ 1542 MRR_RR_CAN_DET_RANGE_RATE_048 8192;
BA_ "GenSigCmt" SG_ 1542 MRR_RR_CAN_SCAN_INDEX_2LSB_048 "The two LSB of scan index";
BA_ "GenSigCmt" SG_ 1542 MRR_RR_CAN_DET_AMPLITUDE_048 "Detected object amplitude";
BA_ "GenSigStartValue" SG_ 1542 MRR_RR_CAN_DET_AMPLITUDE_048 64;
BA_ "GenSigCmt" SG_ 1542 MRR_RR_CAN_DET_VALID_LEVEL_048 "Detected object valid level";
BA_ "GenSigCmt" SG_ 1542 MRR_RR_CAN_DET_ELEVATION_047 "Detected object elevation position";
BA_ "GenSigStartValue" SG_ 1542 MRR_RR_CAN_DET_ELEVATION_047 63.8646288209607;
BA_ "GenSigCmt" SG_ 1542 MRR_RR_CAN_DET_SUPER_RES_TA_0044 "Super resolution target";
BA_ "SystemSignalLongSymbol" SG_ 1542 MRR_RR_CAN_DET_SUPER_RES_TA_0044 "MRR_RR_CAN_DET_SUPER_RES_TARGET_047";
BA_ "GenSigCmt" SG_ 1542 MRR_RR_CAN_DET_AZIMUTH_047 "Detected object azimuth position";
BA_ "GenSigStartValue" SG_ 1542 MRR_RR_CAN_DET_AZIMUTH_047 8194.05320813772;
BA_ "GenSigCmt" SG_ 1542 MRR_RR_CAN_DET_CONFID_ELEVA_0044 "Elevation Angle Confidence";
BA_ "SystemSignalLongSymbol" SG_ 1542 MRR_RR_CAN_DET_CONFID_ELEVA_0044 "MRR_RR_CAN_DET_CONFID_ELEVATION_047";
BA_ "GenSigCmt" SG_ 1542 MRR_RR_CAN_DET_HOST_VEH_CLU_0044 "Host vehicle clutter";
BA_ "SystemSignalLongSymbol" SG_ 1542 MRR_RR_CAN_DET_HOST_VEH_CLU_0044 "MRR_RR_CAN_DET_HOST_VEH_CLUTTER_047";
BA_ "GenSigCmt" SG_ 1542 MRR_RR_CAN_DET_RANGE_047 "Detected object range";
BA_ "GenSigCmt" SG_ 1542 MRR_RR_CAN_DET_CONFID_AZIMU_0040 "Signal to noise level";
BA_ "GenSigVtEn" SG_ 1542 MRR_RR_CAN_DET_CONFID_AZIMU_0040 "TRUE";
BA_ "SystemSignalLongSymbol" SG_ 1542 MRR_RR_CAN_DET_CONFID_AZIMU_0040 "MRR_RR_CAN_DET_CONFID_AZIMUTH_047";
BA_ "GenSigCmt" SG_ 1542 MRR_RR_CAN_DET_RANGE_RATE_047 "Detected object range rate";
BA_ "GenSigStartValue" SG_ 1542 MRR_RR_CAN_DET_RANGE_RATE_047 8192;
BA_ "GenSigCmt" SG_ 1542 MRR_RR_CAN_SCAN_INDEX_2LSB_047 "The two LSB of scan index";
BA_ "GenSigCmt" SG_ 1542 MRR_RR_CAN_DET_AMPLITUDE_047 "Detected object amplitude";
BA_ "GenSigStartValue" SG_ 1542 MRR_RR_CAN_DET_AMPLITUDE_047 64;
BA_ "GenSigCmt" SG_ 1542 MRR_RR_CAN_DET_VALID_LEVEL_047 "Detected object valid level";
BA_ "GenSigCmt" SG_ 1542 MRR_RR_CAN_DET_ELEVATION_046 "Detected object elevation position";
BA_ "GenSigStartValue" SG_ 1542 MRR_RR_CAN_DET_ELEVATION_046 63.8646288209607;
BA_ "GenSigCmt" SG_ 1542 MRR_RR_CAN_DET_SUPER_RES_TA_0045 "Super resolution target";
BA_ "SystemSignalLongSymbol" SG_ 1542 MRR_RR_CAN_DET_SUPER_RES_TA_0045 "MRR_RR_CAN_DET_SUPER_RES_TARGET_046";
BA_ "GenSigCmt" SG_ 1542 MRR_RR_CAN_DET_AZIMUTH_046 "Detected object azimuth position";
BA_ "GenSigStartValue" SG_ 1542 MRR_RR_CAN_DET_AZIMUTH_046 8194.05320813772;
BA_ "GenSigCmt" SG_ 1542 MRR_RR_CAN_DET_CONFID_ELEVA_0045 "Elevation Angle Confidence";
BA_ "SystemSignalLongSymbol" SG_ 1542 MRR_RR_CAN_DET_CONFID_ELEVA_0045 "MRR_RR_CAN_DET_CONFID_ELEVATION_046";
BA_ "GenSigCmt" SG_ 1542 MRR_RR_CAN_DET_HOST_VEH_CLU_0045 "Host vehicle clutter";
BA_ "SystemSignalLongSymbol" SG_ 1542 MRR_RR_CAN_DET_HOST_VEH_CLU_0045 "MRR_RR_CAN_DET_HOST_VEH_CLUTTER_046";
BA_ "GenSigCmt" SG_ 1542 MRR_RR_CAN_DET_RANGE_046 "Detected object range";
BA_ "GenSigCmt" SG_ 1542 MRR_RR_CAN_DET_CONFID_AZIMU_0041 "Signal to noise level";
BA_ "GenSigVtEn" SG_ 1542 MRR_RR_CAN_DET_CONFID_AZIMU_0041 "TRUE";
BA_ "SystemSignalLongSymbol" SG_ 1542 MRR_RR_CAN_DET_CONFID_AZIMU_0041 "MRR_RR_CAN_DET_CONFID_AZIMUTH_046";
BA_ "GenSigCmt" SG_ 1542 MRR_RR_CAN_DET_RANGE_RATE_046 "Detected object range rate";
BA_ "GenSigStartValue" SG_ 1542 MRR_RR_CAN_DET_RANGE_RATE_046 8192;
BA_ "GenSigCmt" SG_ 1542 MRR_RR_CAN_SCAN_INDEX_2LSB_046 "The two LSB of scan index";
BA_ "GenSigCmt" SG_ 1542 MRR_RR_CAN_DET_AMPLITUDE_046 "Detected object amplitude";
BA_ "GenSigStartValue" SG_ 1542 MRR_RR_CAN_DET_AMPLITUDE_046 64;
BA_ "GenSigCmt" SG_ 1542 MRR_RR_CAN_DET_VALID_LEVEL_046 "Detected object valid level";
BA_ "GenSigCmt" SG_ 1542 MRR_RR_CAN_DET_ELEVATION_045 "Detected object elevation position";
BA_ "GenSigStartValue" SG_ 1542 MRR_RR_CAN_DET_ELEVATION_045 63.8646288209607;
BA_ "GenSigCmt" SG_ 1542 MRR_RR_CAN_DET_SUPER_RES_TA_0046 "Super resolution target";
BA_ "SystemSignalLongSymbol" SG_ 1542 MRR_RR_CAN_DET_SUPER_RES_TA_0046 "MRR_RR_CAN_DET_SUPER_RES_TARGET_045";
BA_ "GenSigCmt" SG_ 1542 MRR_RR_CAN_DET_AZIMUTH_045 "Detected object azimuth position";
BA_ "GenSigStartValue" SG_ 1542 MRR_RR_CAN_DET_AZIMUTH_045 8194.05320813772;
BA_ "GenSigCmt" SG_ 1542 MRR_RR_CAN_DET_CONFID_ELEVA_0046 "Elevation Angle Confidence";
BA_ "SystemSignalLongSymbol" SG_ 1542 MRR_RR_CAN_DET_CONFID_ELEVA_0046 "MRR_RR_CAN_DET_CONFID_ELEVATION_045";
BA_ "GenSigCmt" SG_ 1542 MRR_RR_CAN_DET_HOST_VEH_CLU_0046 "Host vehicle clutter";
BA_ "SystemSignalLongSymbol" SG_ 1542 MRR_RR_CAN_DET_HOST_VEH_CLU_0046 "MRR_RR_CAN_DET_HOST_VEH_CLUTTER_045";
BA_ "GenSigCmt" SG_ 1542 MRR_RR_CAN_DET_RANGE_045 "Detected object range";
BA_ "GenSigCmt" SG_ 1542 MRR_RR_CAN_DET_CONFID_AZIMU_0042 "Signal to noise level";
BA_ "GenSigVtEn" SG_ 1542 MRR_RR_CAN_DET_CONFID_AZIMU_0042 "TRUE";
BA_ "SystemSignalLongSymbol" SG_ 1542 MRR_RR_CAN_DET_CONFID_AZIMU_0042 "MRR_RR_CAN_DET_CONFID_AZIMUTH_045";
BA_ "GenSigCmt" SG_ 1542 MRR_RR_CAN_DET_RANGE_RATE_045 "Detected object range rate";
BA_ "GenSigStartValue" SG_ 1542 MRR_RR_CAN_DET_RANGE_RATE_045 8192;
BA_ "GenSigCmt" SG_ 1542 MRR_RR_CAN_SCAN_INDEX_2LSB_045 "The two LSB of scan index";
BA_ "GenSigCmt" SG_ 1542 MRR_RR_CAN_DET_AMPLITUDE_045 "Detected object amplitude";
BA_ "GenSigStartValue" SG_ 1542 MRR_RR_CAN_DET_AMPLITUDE_045 64;
BA_ "GenSigCmt" SG_ 1542 MRR_RR_CAN_DET_VALID_LEVEL_045 "Detected object valid level";
BA_ "GenSigCmt" SG_ 1542 MRR_RR_CAN_DET_ELEVATION_044 "Detected object elevation position";
BA_ "GenSigStartValue" SG_ 1542 MRR_RR_CAN_DET_ELEVATION_044 63.8646288209607;
BA_ "GenSigCmt" SG_ 1542 MRR_RR_CAN_DET_SUPER_RES_TA_0047 "Super resolution target";
BA_ "SystemSignalLongSymbol" SG_ 1542 MRR_RR_CAN_DET_SUPER_RES_TA_0047 "MRR_RR_CAN_DET_SUPER_RES_TARGET_044";
BA_ "GenSigCmt" SG_ 1542 MRR_RR_CAN_DET_AZIMUTH_044 "Detected object azimuth position";
BA_ "GenSigStartValue" SG_ 1542 MRR_RR_CAN_DET_AZIMUTH_044 8194.05320813772;
BA_ "GenSigCmt" SG_ 1542 MRR_RR_CAN_DET_CONFID_ELEVA_0047 "Elevation Angle Confidence";
BA_ "SystemSignalLongSymbol" SG_ 1542 MRR_RR_CAN_DET_CONFID_ELEVA_0047 "MRR_RR_CAN_DET_CONFID_ELEVATION_044";
BA_ "GenSigCmt" SG_ 1542 MRR_RR_CAN_DET_HOST_VEH_CLU_0047 "Host vehicle clutter";
BA_ "SystemSignalLongSymbol" SG_ 1542 MRR_RR_CAN_DET_HOST_VEH_CLU_0047 "MRR_RR_CAN_DET_HOST_VEH_CLUTTER_044";
BA_ "GenSigCmt" SG_ 1542 MRR_RR_CAN_DET_RANGE_044 "Detected object range";
BA_ "GenSigCmt" SG_ 1542 MRR_RR_CAN_DET_CONFID_AZIMU_0043 "Signal to noise level";
BA_ "GenSigVtEn" SG_ 1542 MRR_RR_CAN_DET_CONFID_AZIMU_0043 "TRUE";
BA_ "SystemSignalLongSymbol" SG_ 1542 MRR_RR_CAN_DET_CONFID_AZIMU_0043 "MRR_RR_CAN_DET_CONFID_AZIMUTH_044";
BA_ "GenSigCmt" SG_ 1542 MRR_RR_CAN_DET_RANGE_RATE_044 "Detected object range rate";
BA_ "GenSigStartValue" SG_ 1542 MRR_RR_CAN_DET_RANGE_RATE_044 8192;
BA_ "GenSigCmt" SG_ 1542 MRR_RR_CAN_SCAN_INDEX_2LSB_044 "The two LSB of scan index";
BA_ "GenSigCmt" SG_ 1542 MRR_RR_CAN_DET_AMPLITUDE_044 "Detected object amplitude";
BA_ "GenSigStartValue" SG_ 1542 MRR_RR_CAN_DET_AMPLITUDE_044 64;
BA_ "GenSigCmt" SG_ 1542 MRR_RR_CAN_DET_VALID_LEVEL_044 "Detected object valid level";
BA_ "GenSigSendType" SG_ 1543 MRR_RR_CAN_DET_MID_TARGET_056 1;
BA_ "SignalDescription" SG_ 1543 MRR_RR_CAN_DET_MID_TARGET_056 "MID_Target_Discrimination";
BA_ "SignalDescription" SG_ 1543 MRR_RR_CAN_DET_MID_TARGET_055 "MID_Target_Discrimination";
BA_ "SignalDescription" SG_ 1543 MRR_RR_CAN_DET_MID_TARGET_054 "MID_Target_Discrimination";
BA_ "SignalDescription" SG_ 1543 MRR_RR_CAN_DET_MID_TARGET_053 "MID_Target_Discrimination";
BA_ "SignalDescription" SG_ 1543 MRR_RR_CAN_DET_MID_TARGET_052 "MID_Target_Discrimination";
BA_ "SignalDescription" SG_ 1543 MRR_RR_CAN_DET_MID_TARGET_051 "MID_Target_Discrimination";
BA_ "SignalDescription" SG_ 1543 MRR_RR_CAN_DET_MID_TARGET_050 "MID_Target_Discrimination";
BA_ "SignalDescription" SG_ 1543 MRR_RR_CAN_DET_Near_TARGET_050 "Near_Target_Discrimination";
BA_ "SignalDescription" SG_ 1543 MRR_RR_CAN_DET_Near_TARGET_051 "Near_Target_Discrimination";
BA_ "SignalDescription" SG_ 1543 MRR_RR_CAN_DET_Near_TARGET_052 "Near_Target_Discrimination";
BA_ "SignalDescription" SG_ 1543 MRR_RR_CAN_DET_Near_TARGET_053 "Near_Target_Discrimination";
BA_ "SignalDescription" SG_ 1543 MRR_RR_CAN_DET_Near_TARGET_054 "Near_Target_Discrimination";
BA_ "SignalDescription" SG_ 1543 MRR_RR_CAN_DET_Near_TARGET_055 "Near_Target_Discrimination";
BA_ "SignalDescription" SG_ 1543 MRR_RR_CAN_DET_Near_TARGET_056 "Near_Target_Discrimination";
BA_ "GenSigCmt" SG_ 1543 MRR_RR_CAN_DET_ELEVATION_050 "Detected object elevation position";
BA_ "GenSigStartValue" SG_ 1543 MRR_RR_CAN_DET_ELEVATION_050 63.8646288209607;
BA_ "GenSigCmt" SG_ 1543 MRR_RR_CAN_DET_CONFID_AZIMUTH_05 "Signal to noise level";
BA_ "GenSigVtEn" SG_ 1543 MRR_RR_CAN_DET_CONFID_AZIMUTH_05 "TRUE";
BA_ "SystemSignalLongSymbol" SG_ 1543 MRR_RR_CAN_DET_CONFID_AZIMUTH_05 "MRR_RR_CAN_DET_CONFID_AZIMUTH_050";
BA_ "GenSigCmt" SG_ 1543 MRR_RR_CAN_DET_SUPER_RES_TA_0048 "Super resolution target";
BA_ "SystemSignalLongSymbol" SG_ 1543 MRR_RR_CAN_DET_SUPER_RES_TA_0048 "MRR_RR_CAN_DET_SUPER_RES_TARGET_050";
BA_ "GenSigCmt" SG_ 1543 MRR_RR_CAN_DET_CONFID_ELEVA_0048 "Elevation Angle Confidence";
BA_ "SystemSignalLongSymbol" SG_ 1543 MRR_RR_CAN_DET_CONFID_ELEVA_0048 "MRR_RR_CAN_DET_CONFID_ELEVATION_050";
BA_ "GenSigCmt" SG_ 1543 MRR_RR_CAN_DET_HOST_VEH_CLU_0048 "Host vehicle clutter";
BA_ "SystemSignalLongSymbol" SG_ 1543 MRR_RR_CAN_DET_HOST_VEH_CLU_0048 "MRR_RR_CAN_DET_HOST_VEH_CLUTTER_050";
BA_ "GenSigCmt" SG_ 1543 MRR_RR_CAN_DET_VALID_LEVEL_050 "Detected object valid level";
BA_ "GenSigCmt" SG_ 1543 MRR_RR_CAN_DET_AZIMUTH_050 "Detected object azimuth position";
BA_ "GenSigStartValue" SG_ 1543 MRR_RR_CAN_DET_AZIMUTH_050 8194.05320813772;
BA_ "GenSigCmt" SG_ 1543 MRR_RR_CAN_DET_RANGE_050 "Detected object range";
BA_ "GenSigCmt" SG_ 1543 MRR_RR_CAN_DET_RANGE_RATE_050 "Detected object range rate";
BA_ "GenSigStartValue" SG_ 1543 MRR_RR_CAN_DET_RANGE_RATE_050 8192;
BA_ "GenSigCmt" SG_ 1543 MRR_RR_CAN_DET_AMPLITUDE_050 "Detected object amplitude";
BA_ "GenSigStartValue" SG_ 1543 MRR_RR_CAN_DET_AMPLITUDE_050 64;
BA_ "GenSigCmt" SG_ 1543 MRR_RR_CAN_SCAN_INDEX_2LSB_050 "The two LSB of scan index";
BA_ "GenSigStartValue" SG_ 1543 MRR_RR_CAN_DET_ELEVATION_056 63.8646288209607;
BA_ "GenSigCmt" SG_ 1543 MRR_RR_CAN_DET_ELEVATION_056 "Detected object elevation position";
BA_ "GenSigCmt" SG_ 1543 MRR_RR_CAN_DET_SUPER_RES_TA_0049 "Super resolution target";
BA_ "SystemSignalLongSymbol" SG_ 1543 MRR_RR_CAN_DET_SUPER_RES_TA_0049 "MRR_RR_CAN_DET_SUPER_RES_TARGET_056";
BA_ "GenSigCmt" SG_ 1543 MRR_RR_CAN_DET_AZIMUTH_056 "Detected object azimuth position";
BA_ "GenSigStartValue" SG_ 1543 MRR_RR_CAN_DET_AZIMUTH_056 8194.05320813772;
BA_ "GenSigCmt" SG_ 1543 MRR_RR_CAN_DET_CONFID_ELEVA_0049 "Elevation Angle Confidence";
BA_ "SystemSignalLongSymbol" SG_ 1543 MRR_RR_CAN_DET_CONFID_ELEVA_0049 "MRR_RR_CAN_DET_CONFID_ELEVATION_056";
BA_ "GenSigCmt" SG_ 1543 MRR_RR_CAN_DET_HOST_VEH_CLU_0049 "Host vehicle clutter";
BA_ "SystemSignalLongSymbol" SG_ 1543 MRR_RR_CAN_DET_HOST_VEH_CLU_0049 "MRR_RR_CAN_DET_HOST_VEH_CLUTTER_056";
BA_ "GenSigCmt" SG_ 1543 MRR_RR_CAN_DET_RANGE_056 "Detected object range";
BA_ "GenSigCmt" SG_ 1543 MRR_RR_CAN_DET_CONFID_AZIMU_0044 "Signal to noise level";
BA_ "GenSigVtEn" SG_ 1543 MRR_RR_CAN_DET_CONFID_AZIMU_0044 "TRUE";
BA_ "SystemSignalLongSymbol" SG_ 1543 MRR_RR_CAN_DET_CONFID_AZIMU_0044 "MRR_RR_CAN_DET_CONFID_AZIMUTH_056";
BA_ "GenSigCmt" SG_ 1543 MRR_RR_CAN_DET_RANGE_RATE_056 "Detected object range rate";
BA_ "GenSigStartValue" SG_ 1543 MRR_RR_CAN_DET_RANGE_RATE_056 8192;
BA_ "GenSigCmt" SG_ 1543 MRR_RR_CAN_SCAN_INDEX_2LSB_056 "The two LSB of scan index";
BA_ "GenSigCmt" SG_ 1543 MRR_RR_CAN_DET_AMPLITUDE_056 "Detected object amplitude";
BA_ "GenSigStartValue" SG_ 1543 MRR_RR_CAN_DET_AMPLITUDE_056 64;
BA_ "GenSigCmt" SG_ 1543 MRR_RR_CAN_DET_VALID_LEVEL_056 "Detected object valid level";
BA_ "GenSigCmt" SG_ 1543 MRR_RR_CAN_DET_ELEVATION_055 "Detected object elevation position";
BA_ "GenSigStartValue" SG_ 1543 MRR_RR_CAN_DET_ELEVATION_055 63.8646288209607;
BA_ "GenSigCmt" SG_ 1543 MRR_RR_CAN_DET_SUPER_RES_TA_0050 "Super resolution target";
BA_ "SystemSignalLongSymbol" SG_ 1543 MRR_RR_CAN_DET_SUPER_RES_TA_0050 "MRR_RR_CAN_DET_SUPER_RES_TARGET_055";
BA_ "GenSigCmt" SG_ 1543 MRR_RR_CAN_DET_AZIMUTH_055 "Detected object azimuth position";
BA_ "GenSigStartValue" SG_ 1543 MRR_RR_CAN_DET_AZIMUTH_055 8194.05320813772;
BA_ "GenSigCmt" SG_ 1543 MRR_RR_CAN_DET_CONFID_ELEVA_0050 "Elevation Angle Confidence";
BA_ "SystemSignalLongSymbol" SG_ 1543 MRR_RR_CAN_DET_CONFID_ELEVA_0050 "MRR_RR_CAN_DET_CONFID_ELEVATION_055";
BA_ "GenSigCmt" SG_ 1543 MRR_RR_CAN_DET_HOST_VEH_CLU_0050 "Host vehicle clutter";
BA_ "SystemSignalLongSymbol" SG_ 1543 MRR_RR_CAN_DET_HOST_VEH_CLU_0050 "MRR_RR_CAN_DET_HOST_VEH_CLUTTER_055";
BA_ "GenSigCmt" SG_ 1543 MRR_RR_CAN_DET_RANGE_055 "Detected object range";
BA_ "GenSigCmt" SG_ 1543 MRR_RR_CAN_DET_CONFID_AZIMU_0045 "Signal to noise level";
BA_ "GenSigVtEn" SG_ 1543 MRR_RR_CAN_DET_CONFID_AZIMU_0045 "TRUE";
BA_ "SystemSignalLongSymbol" SG_ 1543 MRR_RR_CAN_DET_CONFID_AZIMU_0045 "MRR_RR_CAN_DET_CONFID_AZIMUTH_055";
BA_ "GenSigCmt" SG_ 1543 MRR_RR_CAN_DET_RANGE_RATE_055 "Detected object range rate";
BA_ "GenSigStartValue" SG_ 1543 MRR_RR_CAN_DET_RANGE_RATE_055 8192;
BA_ "GenSigCmt" SG_ 1543 MRR_RR_CAN_SCAN_INDEX_2LSB_055 "The two LSB of scan index";
BA_ "GenSigCmt" SG_ 1543 MRR_RR_CAN_DET_AMPLITUDE_055 "Detected object amplitude";
BA_ "GenSigStartValue" SG_ 1543 MRR_RR_CAN_DET_AMPLITUDE_055 64;
BA_ "GenSigCmt" SG_ 1543 MRR_RR_CAN_DET_VALID_LEVEL_055 "Detected object valid level";
BA_ "GenSigCmt" SG_ 1543 MRR_RR_CAN_DET_ELEVATION_054 "Detected object elevation position";
BA_ "GenSigStartValue" SG_ 1543 MRR_RR_CAN_DET_ELEVATION_054 63.8646288209607;
BA_ "GenSigCmt" SG_ 1543 MRR_RR_CAN_DET_SUPER_RES_TA_0051 "Super resolution target";
BA_ "SystemSignalLongSymbol" SG_ 1543 MRR_RR_CAN_DET_SUPER_RES_TA_0051 "MRR_RR_CAN_DET_SUPER_RES_TARGET_054";
BA_ "GenSigCmt" SG_ 1543 MRR_RR_CAN_DET_AZIMUTH_054 "Detected object azimuth position";
BA_ "GenSigStartValue" SG_ 1543 MRR_RR_CAN_DET_AZIMUTH_054 8194.05320813772;
BA_ "GenSigCmt" SG_ 1543 MRR_RR_CAN_DET_CONFID_ELEVA_0051 "Elevation Angle Confidence";
BA_ "SystemSignalLongSymbol" SG_ 1543 MRR_RR_CAN_DET_CONFID_ELEVA_0051 "MRR_RR_CAN_DET_CONFID_ELEVATION_054";
BA_ "GenSigCmt" SG_ 1543 MRR_RR_CAN_DET_HOST_VEH_CLU_0051 "Host vehicle clutter";
BA_ "SystemSignalLongSymbol" SG_ 1543 MRR_RR_CAN_DET_HOST_VEH_CLU_0051 "MRR_RR_CAN_DET_HOST_VEH_CLUTTER_054";
BA_ "GenSigCmt" SG_ 1543 MRR_RR_CAN_DET_RANGE_054 "Detected object range";
BA_ "GenSigCmt" SG_ 1543 MRR_RR_CAN_DET_CONFID_AZIMU_0046 "Signal to noise level";
BA_ "GenSigVtEn" SG_ 1543 MRR_RR_CAN_DET_CONFID_AZIMU_0046 "TRUE";
BA_ "SystemSignalLongSymbol" SG_ 1543 MRR_RR_CAN_DET_CONFID_AZIMU_0046 "MRR_RR_CAN_DET_CONFID_AZIMUTH_054";
BA_ "GenSigCmt" SG_ 1543 MRR_RR_CAN_DET_RANGE_RATE_054 "Detected object range rate";
BA_ "GenSigStartValue" SG_ 1543 MRR_RR_CAN_DET_RANGE_RATE_054 8192;
BA_ "GenSigCmt" SG_ 1543 MRR_RR_CAN_SCAN_INDEX_2LSB_054 "The two LSB of scan index";
BA_ "GenSigCmt" SG_ 1543 MRR_RR_CAN_DET_AMPLITUDE_054 "Detected object amplitude";
BA_ "GenSigStartValue" SG_ 1543 MRR_RR_CAN_DET_AMPLITUDE_054 64;
BA_ "GenSigCmt" SG_ 1543 MRR_RR_CAN_DET_VALID_LEVEL_054 "Detected object valid level";
BA_ "GenSigCmt" SG_ 1543 MRR_RR_CAN_DET_ELEVATION_053 "Detected object elevation position";
BA_ "GenSigStartValue" SG_ 1543 MRR_RR_CAN_DET_ELEVATION_053 63.8646288209607;
BA_ "GenSigCmt" SG_ 1543 MRR_RR_CAN_DET_SUPER_RES_TA_0052 "Super resolution target";
BA_ "SystemSignalLongSymbol" SG_ 1543 MRR_RR_CAN_DET_SUPER_RES_TA_0052 "MRR_RR_CAN_DET_SUPER_RES_TARGET_053";
BA_ "GenSigCmt" SG_ 1543 MRR_RR_CAN_DET_AZIMUTH_053 "Detected object azimuth position";
BA_ "GenSigStartValue" SG_ 1543 MRR_RR_CAN_DET_AZIMUTH_053 8194.05320813772;
BA_ "GenSigCmt" SG_ 1543 MRR_RR_CAN_DET_CONFID_ELEVA_0052 "Elevation Angle Confidence";
BA_ "SystemSignalLongSymbol" SG_ 1543 MRR_RR_CAN_DET_CONFID_ELEVA_0052 "MRR_RR_CAN_DET_CONFID_ELEVATION_053";
BA_ "GenSigCmt" SG_ 1543 MRR_RR_CAN_DET_HOST_VEH_CLU_0052 "Host vehicle clutter";
BA_ "SystemSignalLongSymbol" SG_ 1543 MRR_RR_CAN_DET_HOST_VEH_CLU_0052 "MRR_RR_CAN_DET_HOST_VEH_CLUTTER_053";
BA_ "GenSigCmt" SG_ 1543 MRR_RR_CAN_DET_RANGE_053 "Detected object range";
BA_ "GenSigCmt" SG_ 1543 MRR_RR_CAN_DET_CONFID_AZIMU_0047 "Signal to noise level";
BA_ "GenSigVtEn" SG_ 1543 MRR_RR_CAN_DET_CONFID_AZIMU_0047 "TRUE";
BA_ "SystemSignalLongSymbol" SG_ 1543 MRR_RR_CAN_DET_CONFID_AZIMU_0047 "MRR_RR_CAN_DET_CONFID_AZIMUTH_053";
BA_ "GenSigCmt" SG_ 1543 MRR_RR_CAN_DET_RANGE_RATE_053 "Detected object range rate";
BA_ "GenSigStartValue" SG_ 1543 MRR_RR_CAN_DET_RANGE_RATE_053 8192;
BA_ "GenSigCmt" SG_ 1543 MRR_RR_CAN_SCAN_INDEX_2LSB_053 "The two LSB of scan index";
BA_ "GenSigCmt" SG_ 1543 MRR_RR_CAN_DET_AMPLITUDE_053 "Detected object amplitude";
BA_ "GenSigStartValue" SG_ 1543 MRR_RR_CAN_DET_AMPLITUDE_053 64;
BA_ "GenSigCmt" SG_ 1543 MRR_RR_CAN_DET_VALID_LEVEL_053 "Detected object valid level";
BA_ "GenSigCmt" SG_ 1543 MRR_RR_CAN_DET_ELEVATION_052 "Detected object elevation position";
BA_ "GenSigStartValue" SG_ 1543 MRR_RR_CAN_DET_ELEVATION_052 63.8646288209607;
BA_ "GenSigCmt" SG_ 1543 MRR_RR_CAN_DET_SUPER_RES_TA_0053 "Super resolution target";
BA_ "SystemSignalLongSymbol" SG_ 1543 MRR_RR_CAN_DET_SUPER_RES_TA_0053 "MRR_RR_CAN_DET_SUPER_RES_TARGET_052";
BA_ "GenSigCmt" SG_ 1543 MRR_RR_CAN_DET_AZIMUTH_052 "Detected object azimuth position";
BA_ "GenSigStartValue" SG_ 1543 MRR_RR_CAN_DET_AZIMUTH_052 8194.05320813772;
BA_ "GenSigCmt" SG_ 1543 MRR_RR_CAN_DET_CONFID_ELEVA_0053 "Elevation Angle Confidence";
BA_ "SystemSignalLongSymbol" SG_ 1543 MRR_RR_CAN_DET_CONFID_ELEVA_0053 "MRR_RR_CAN_DET_CONFID_ELEVATION_052";
BA_ "GenSigCmt" SG_ 1543 MRR_RR_CAN_DET_HOST_VEH_CLU_0053 "Host vehicle clutter";
BA_ "SystemSignalLongSymbol" SG_ 1543 MRR_RR_CAN_DET_HOST_VEH_CLU_0053 "MRR_RR_CAN_DET_HOST_VEH_CLUTTER_052";
BA_ "GenSigCmt" SG_ 1543 MRR_RR_CAN_DET_RANGE_052 "Detected object range";
BA_ "GenSigCmt" SG_ 1543 MRR_RR_CAN_DET_CONFID_AZIMU_0048 "Signal to noise level";
BA_ "GenSigVtEn" SG_ 1543 MRR_RR_CAN_DET_CONFID_AZIMU_0048 "TRUE";
BA_ "SystemSignalLongSymbol" SG_ 1543 MRR_RR_CAN_DET_CONFID_AZIMU_0048 "MRR_RR_CAN_DET_CONFID_AZIMUTH_052";
BA_ "GenSigCmt" SG_ 1543 MRR_RR_CAN_DET_RANGE_RATE_052 "Detected object range rate";
BA_ "GenSigStartValue" SG_ 1543 MRR_RR_CAN_DET_RANGE_RATE_052 8192;
BA_ "GenSigCmt" SG_ 1543 MRR_RR_CAN_SCAN_INDEX_2LSB_052 "The two LSB of scan index";
BA_ "GenSigCmt" SG_ 1543 MRR_RR_CAN_DET_AMPLITUDE_052 "Detected object amplitude";
BA_ "GenSigStartValue" SG_ 1543 MRR_RR_CAN_DET_AMPLITUDE_052 64;
BA_ "GenSigCmt" SG_ 1543 MRR_RR_CAN_DET_VALID_LEVEL_052 "Detected object valid level";
BA_ "GenSigCmt" SG_ 1543 MRR_RR_CAN_DET_ELEVATION_051 "Detected object elevation position";
BA_ "GenSigStartValue" SG_ 1543 MRR_RR_CAN_DET_ELEVATION_051 63.8646288209607;
BA_ "GenSigCmt" SG_ 1543 MRR_RR_CAN_DET_SUPER_RES_TA_0054 "Super resolution target";
BA_ "SystemSignalLongSymbol" SG_ 1543 MRR_RR_CAN_DET_SUPER_RES_TA_0054 "MRR_RR_CAN_DET_SUPER_RES_TARGET_051";
BA_ "GenSigCmt" SG_ 1543 MRR_RR_CAN_DET_AZIMUTH_051 "Detected object azimuth position";
BA_ "GenSigStartValue" SG_ 1543 MRR_RR_CAN_DET_AZIMUTH_051 8194.05320813772;
BA_ "GenSigCmt" SG_ 1543 MRR_RR_CAN_DET_CONFID_ELEVA_0054 "Elevation Angle Confidence";
BA_ "SystemSignalLongSymbol" SG_ 1543 MRR_RR_CAN_DET_CONFID_ELEVA_0054 "MRR_RR_CAN_DET_CONFID_ELEVATION_051";
BA_ "GenSigCmt" SG_ 1543 MRR_RR_CAN_DET_HOST_VEH_CLU_0054 "Host vehicle clutter";
BA_ "SystemSignalLongSymbol" SG_ 1543 MRR_RR_CAN_DET_HOST_VEH_CLU_0054 "MRR_RR_CAN_DET_HOST_VEH_CLUTTER_051";
BA_ "GenSigCmt" SG_ 1543 MRR_RR_CAN_DET_RANGE_051 "Detected object range";
BA_ "GenSigCmt" SG_ 1543 MRR_RR_CAN_DET_CONFID_AZIMU_0049 "Signal to noise level";
BA_ "GenSigVtEn" SG_ 1543 MRR_RR_CAN_DET_CONFID_AZIMU_0049 "TRUE";
BA_ "SystemSignalLongSymbol" SG_ 1543 MRR_RR_CAN_DET_CONFID_AZIMU_0049 "MRR_RR_CAN_DET_CONFID_AZIMUTH_051";
BA_ "GenSigCmt" SG_ 1543 MRR_RR_CAN_DET_RANGE_RATE_051 "Detected object range rate";
BA_ "GenSigStartValue" SG_ 1543 MRR_RR_CAN_DET_RANGE_RATE_051 8192;
BA_ "GenSigCmt" SG_ 1543 MRR_RR_CAN_SCAN_INDEX_2LSB_051 "The two LSB of scan index";
BA_ "GenSigCmt" SG_ 1543 MRR_RR_CAN_DET_AMPLITUDE_051 "Detected object amplitude";
BA_ "GenSigStartValue" SG_ 1543 MRR_RR_CAN_DET_AMPLITUDE_051 64;
BA_ "GenSigCmt" SG_ 1543 MRR_RR_CAN_DET_VALID_LEVEL_051 "Detected object valid level";
BA_ "GenSigSendType" SG_ 1544 MRR_RR_CAN_DET_MID_TARGET_063 1;
BA_ "SignalDescription" SG_ 1544 MRR_RR_CAN_DET_MID_TARGET_063 "MID_Target_Discrimination";
BA_ "SignalDescription" SG_ 1544 MRR_RR_CAN_DET_MID_TARGET_062 "MID_Target_Discrimination";
BA_ "SignalDescription" SG_ 1544 MRR_RR_CAN_DET_MID_TARGET_061 "MID_Target_Discrimination";
BA_ "SignalDescription" SG_ 1544 MRR_RR_CAN_DET_MID_TARGET_060 "MID_Target_Discrimination";
BA_ "SignalDescription" SG_ 1544 MRR_RR_CAN_DET_MID_TARGET_059 "MID_Target_Discrimination";
BA_ "SignalDescription" SG_ 1544 MRR_RR_CAN_DET_MID_TARGET_058 "MID_Target_Discrimination";
BA_ "SignalDescription" SG_ 1544 MRR_RR_CAN_DET_MID_TARGET_057 "MID_Target_Discrimination";
BA_ "SignalDescription" SG_ 1544 MRR_RR_CAN_DET_Near_TARGET_057 "Near_Target_Discrimination";
BA_ "SignalDescription" SG_ 1544 MRR_RR_CAN_DET_Near_TARGET_058 "Near_Target_Discrimination";
BA_ "SignalDescription" SG_ 1544 MRR_RR_CAN_DET_Near_TARGET_059 "Near_Target_Discrimination";
BA_ "SignalDescription" SG_ 1544 MRR_RR_CAN_DET_Near_TARGET_060 "Near_Target_Discrimination";
BA_ "SignalDescription" SG_ 1544 MRR_RR_CAN_DET_Near_TARGET_061 "Near_Target_Discrimination";
BA_ "SignalDescription" SG_ 1544 MRR_RR_CAN_DET_Near_TARGET_062 "Near_Target_Discrimination";
BA_ "SignalDescription" SG_ 1544 MRR_RR_CAN_DET_Near_TARGET_063 "Near_Target_Discrimination";
BA_ "GenSigCmt" SG_ 1544 MRR_RR_CAN_DET_ELEVATION_057 "Detected object elevation position";
BA_ "GenSigStartValue" SG_ 1544 MRR_RR_CAN_DET_ELEVATION_057 63.8646288209607;
BA_ "GenSigCmt" SG_ 1544 MRR_RR_CAN_DET_CONFID_AZIMU_0050 "Signal to noise level";
BA_ "GenSigVtEn" SG_ 1544 MRR_RR_CAN_DET_CONFID_AZIMU_0050 "TRUE";
BA_ "SystemSignalLongSymbol" SG_ 1544 MRR_RR_CAN_DET_CONFID_AZIMU_0050 "MRR_RR_CAN_DET_CONFID_AZIMUTH_057";
BA_ "GenSigCmt" SG_ 1544 MRR_RR_CAN_DET_SUPER_RES_TA_0055 "Super resolution target";
BA_ "SystemSignalLongSymbol" SG_ 1544 MRR_RR_CAN_DET_SUPER_RES_TA_0055 "MRR_RR_CAN_DET_SUPER_RES_TARGET_057";
BA_ "GenSigCmt" SG_ 1544 MRR_RR_CAN_DET_CONFID_ELEVA_0055 "Elevation Angle Confidence";
BA_ "SystemSignalLongSymbol" SG_ 1544 MRR_RR_CAN_DET_CONFID_ELEVA_0055 "MRR_RR_CAN_DET_CONFID_ELEVATION_057";
BA_ "GenSigCmt" SG_ 1544 MRR_RR_CAN_DET_HOST_VEH_CLU_0055 "Host vehicle clutter";
BA_ "SystemSignalLongSymbol" SG_ 1544 MRR_RR_CAN_DET_HOST_VEH_CLU_0055 "MRR_RR_CAN_DET_HOST_VEH_CLUTTER_057";
BA_ "GenSigCmt" SG_ 1544 MRR_RR_CAN_DET_VALID_LEVEL_057 "Detected object valid level";
BA_ "GenSigCmt" SG_ 1544 MRR_RR_CAN_DET_AZIMUTH_057 "Detected object azimuth position";
BA_ "GenSigStartValue" SG_ 1544 MRR_RR_CAN_DET_AZIMUTH_057 8194.05320813772;
BA_ "GenSigCmt" SG_ 1544 MRR_RR_CAN_DET_RANGE_057 "Detected object range";
BA_ "GenSigCmt" SG_ 1544 MRR_RR_CAN_DET_RANGE_RATE_057 "Detected object range rate";
BA_ "GenSigStartValue" SG_ 1544 MRR_RR_CAN_DET_RANGE_RATE_057 8192;
BA_ "GenSigCmt" SG_ 1544 MRR_RR_CAN_DET_AMPLITUDE_057 "Detected object amplitude";
BA_ "GenSigStartValue" SG_ 1544 MRR_RR_CAN_DET_AMPLITUDE_057 64;
BA_ "GenSigCmt" SG_ 1544 MRR_RR_CAN_SCAN_INDEX_2LSB_057 "The two LSB of scan index";
BA_ "GenSigStartValue" SG_ 1544 MRR_RR_CAN_DET_ELEVATION_063 63.8646288209607;
BA_ "GenSigCmt" SG_ 1544 MRR_RR_CAN_DET_ELEVATION_063 "Detected object elevation position";
BA_ "GenSigCmt" SG_ 1544 MRR_RR_CAN_DET_SUPER_RES_TA_0056 "Super resolution target";
BA_ "SystemSignalLongSymbol" SG_ 1544 MRR_RR_CAN_DET_SUPER_RES_TA_0056 "MRR_RR_CAN_DET_SUPER_RES_TARGET_063";
BA_ "GenSigCmt" SG_ 1544 MRR_RR_CAN_DET_AZIMUTH_063 "Detected object azimuth position";
BA_ "GenSigStartValue" SG_ 1544 MRR_RR_CAN_DET_AZIMUTH_063 8194.05320813772;
BA_ "GenSigCmt" SG_ 1544 MRR_RR_CAN_DET_CONFID_ELEVA_0056 "Elevation Angle Confidence";
BA_ "SystemSignalLongSymbol" SG_ 1544 MRR_RR_CAN_DET_CONFID_ELEVA_0056 "MRR_RR_CAN_DET_CONFID_ELEVATION_063";
BA_ "GenSigCmt" SG_ 1544 MRR_RR_CAN_DET_HOST_VEH_CLU_0056 "Host vehicle clutter";
BA_ "SystemSignalLongSymbol" SG_ 1544 MRR_RR_CAN_DET_HOST_VEH_CLU_0056 "MRR_RR_CAN_DET_HOST_VEH_CLUTTER_063";
BA_ "GenSigCmt" SG_ 1544 MRR_RR_CAN_DET_RANGE_063 "Detected object range";
BA_ "GenSigCmt" SG_ 1544 MRR_RR_CAN_DET_CONFID_AZIMUTH_06 "Signal to noise level";
BA_ "GenSigVtEn" SG_ 1544 MRR_RR_CAN_DET_CONFID_AZIMUTH_06 "TRUE";
BA_ "SystemSignalLongSymbol" SG_ 1544 MRR_RR_CAN_DET_CONFID_AZIMUTH_06 "MRR_RR_CAN_DET_CONFID_AZIMUTH_063";
BA_ "GenSigCmt" SG_ 1544 MRR_RR_CAN_DET_RANGE_RATE_063 "Detected object range rate";
BA_ "GenSigStartValue" SG_ 1544 MRR_RR_CAN_DET_RANGE_RATE_063 8192;
BA_ "GenSigCmt" SG_ 1544 MRR_RR_CAN_SCAN_INDEX_2LSB_063 "The two LSB of scan index";
BA_ "GenSigCmt" SG_ 1544 MRR_RR_CAN_DET_AMPLITUDE_063 "Detected object amplitude";
BA_ "GenSigStartValue" SG_ 1544 MRR_RR_CAN_DET_AMPLITUDE_063 64;
BA_ "GenSigCmt" SG_ 1544 MRR_RR_CAN_DET_VALID_LEVEL_063 "Detected object valid level";
BA_ "GenSigCmt" SG_ 1544 MRR_RR_CAN_DET_ELEVATION_062 "Detected object elevation position";
BA_ "GenSigStartValue" SG_ 1544 MRR_RR_CAN_DET_ELEVATION_062 63.8646288209607;
BA_ "GenSigCmt" SG_ 1544 MRR_RR_CAN_DET_SUPER_RES_TA_0057 "Super resolution target";
BA_ "SystemSignalLongSymbol" SG_ 1544 MRR_RR_CAN_DET_SUPER_RES_TA_0057 "MRR_RR_CAN_DET_SUPER_RES_TARGET_062";
BA_ "GenSigCmt" SG_ 1544 MRR_RR_CAN_DET_AZIMUTH_062 "Detected object azimuth position";
BA_ "GenSigStartValue" SG_ 1544 MRR_RR_CAN_DET_AZIMUTH_062 8194.05320813772;
BA_ "GenSigCmt" SG_ 1544 MRR_RR_CAN_DET_CONFID_ELEVA_0057 "Elevation Angle Confidence";
BA_ "SystemSignalLongSymbol" SG_ 1544 MRR_RR_CAN_DET_CONFID_ELEVA_0057 "MRR_RR_CAN_DET_CONFID_ELEVATION_062";
BA_ "GenSigCmt" SG_ 1544 MRR_RR_CAN_DET_HOST_VEH_CLU_0057 "Host vehicle clutter";
BA_ "SystemSignalLongSymbol" SG_ 1544 MRR_RR_CAN_DET_HOST_VEH_CLU_0057 "MRR_RR_CAN_DET_HOST_VEH_CLUTTER_062";
BA_ "GenSigCmt" SG_ 1544 MRR_RR_CAN_DET_RANGE_062 "Detected object range";
BA_ "GenSigCmt" SG_ 1544 MRR_RR_CAN_DET_CONFID_AZIMU_0051 "Signal to noise level";
BA_ "GenSigVtEn" SG_ 1544 MRR_RR_CAN_DET_CONFID_AZIMU_0051 "TRUE";
BA_ "SystemSignalLongSymbol" SG_ 1544 MRR_RR_CAN_DET_CONFID_AZIMU_0051 "MRR_RR_CAN_DET_CONFID_AZIMUTH_062";
BA_ "GenSigCmt" SG_ 1544 MRR_RR_CAN_DET_RANGE_RATE_062 "Detected object range rate";
BA_ "GenSigStartValue" SG_ 1544 MRR_RR_CAN_DET_RANGE_RATE_062 8192;
BA_ "GenSigCmt" SG_ 1544 MRR_RR_CAN_SCAN_INDEX_2LSB_062 "The two LSB of scan index";
BA_ "GenSigCmt" SG_ 1544 MRR_RR_CAN_DET_AMPLITUDE_062 "Detected object amplitude";
BA_ "GenSigStartValue" SG_ 1544 MRR_RR_CAN_DET_AMPLITUDE_062 64;
BA_ "GenSigCmt" SG_ 1544 MRR_RR_CAN_DET_VALID_LEVEL_062 "Detected object valid level";
BA_ "GenSigCmt" SG_ 1544 MRR_RR_CAN_DET_ELEVATION_061 "Detected object elevation position";
BA_ "GenSigStartValue" SG_ 1544 MRR_RR_CAN_DET_ELEVATION_061 63.8646288209607;
BA_ "GenSigCmt" SG_ 1544 MRR_RR_CAN_DET_SUPER_RES_TA_0058 "Super resolution target";
BA_ "SystemSignalLongSymbol" SG_ 1544 MRR_RR_CAN_DET_SUPER_RES_TA_0058 "MRR_RR_CAN_DET_SUPER_RES_TARGET_061";
BA_ "GenSigCmt" SG_ 1544 MRR_RR_CAN_DET_AZIMUTH_061 "Detected object azimuth position";
BA_ "GenSigStartValue" SG_ 1544 MRR_RR_CAN_DET_AZIMUTH_061 8194.05320813772;
BA_ "GenSigCmt" SG_ 1544 MRR_RR_CAN_DET_CONFID_ELEVA_0058 "Elevation Angle Confidence";
BA_ "SystemSignalLongSymbol" SG_ 1544 MRR_RR_CAN_DET_CONFID_ELEVA_0058 "MRR_RR_CAN_DET_CONFID_ELEVATION_061";
BA_ "GenSigCmt" SG_ 1544 MRR_RR_CAN_DET_HOST_VEH_CLU_0058 "Host vehicle clutter";
BA_ "SystemSignalLongSymbol" SG_ 1544 MRR_RR_CAN_DET_HOST_VEH_CLU_0058 "MRR_RR_CAN_DET_HOST_VEH_CLUTTER_061";
BA_ "GenSigCmt" SG_ 1544 MRR_RR_CAN_DET_RANGE_061 "Detected object range";
BA_ "GenSigCmt" SG_ 1544 MRR_RR_CAN_DET_CONFID_AZIMU_0052 "Signal to noise level";
BA_ "GenSigVtEn" SG_ 1544 MRR_RR_CAN_DET_CONFID_AZIMU_0052 "TRUE";
BA_ "SystemSignalLongSymbol" SG_ 1544 MRR_RR_CAN_DET_CONFID_AZIMU_0052 "MRR_RR_CAN_DET_CONFID_AZIMUTH_061";
BA_ "GenSigCmt" SG_ 1544 MRR_RR_CAN_DET_RANGE_RATE_061 "Detected object range rate";
BA_ "GenSigStartValue" SG_ 1544 MRR_RR_CAN_DET_RANGE_RATE_061 8192;
BA_ "GenSigCmt" SG_ 1544 MRR_RR_CAN_SCAN_INDEX_2LSB_061 "The two LSB of scan index";
BA_ "GenSigCmt" SG_ 1544 MRR_RR_CAN_DET_AMPLITUDE_061 "Detected object amplitude";
BA_ "GenSigStartValue" SG_ 1544 MRR_RR_CAN_DET_AMPLITUDE_061 64;
BA_ "GenSigCmt" SG_ 1544 MRR_RR_CAN_DET_VALID_LEVEL_061 "Detected object valid level";
BA_ "GenSigCmt" SG_ 1544 MRR_RR_CAN_DET_ELEVATION_060 "Detected object elevation position";
BA_ "GenSigStartValue" SG_ 1544 MRR_RR_CAN_DET_ELEVATION_060 63.8646288209607;
BA_ "GenSigCmt" SG_ 1544 MRR_RR_CAN_DET_SUPER_RES_TA_0059 "Super resolution target";
BA_ "SystemSignalLongSymbol" SG_ 1544 MRR_RR_CAN_DET_SUPER_RES_TA_0059 "MRR_RR_CAN_DET_SUPER_RES_TARGET_060";
BA_ "GenSigCmt" SG_ 1544 MRR_RR_CAN_DET_AZIMUTH_060 "Detected object azimuth position";
BA_ "GenSigStartValue" SG_ 1544 MRR_RR_CAN_DET_AZIMUTH_060 8194.05320813772;
BA_ "GenSigCmt" SG_ 1544 MRR_RR_CAN_DET_CONFID_ELEVA_0059 "Elevation Angle Confidence";
BA_ "SystemSignalLongSymbol" SG_ 1544 MRR_RR_CAN_DET_CONFID_ELEVA_0059 "MRR_RR_CAN_DET_CONFID_ELEVATION_060";
BA_ "GenSigCmt" SG_ 1544 MRR_RR_CAN_DET_HOST_VEH_CLU_0059 "Host vehicle clutter";
BA_ "SystemSignalLongSymbol" SG_ 1544 MRR_RR_CAN_DET_HOST_VEH_CLU_0059 "MRR_RR_CAN_DET_HOST_VEH_CLUTTER_060";
BA_ "GenSigCmt" SG_ 1544 MRR_RR_CAN_DET_RANGE_060 "Detected object range";
BA_ "GenSigCmt" SG_ 1544 MRR_RR_CAN_DET_CONFID_AZIMU_0053 "Signal to noise level";
BA_ "GenSigVtEn" SG_ 1544 MRR_RR_CAN_DET_CONFID_AZIMU_0053 "TRUE";
BA_ "SystemSignalLongSymbol" SG_ 1544 MRR_RR_CAN_DET_CONFID_AZIMU_0053 "MRR_RR_CAN_DET_CONFID_AZIMUTH_060";
BA_ "GenSigCmt" SG_ 1544 MRR_RR_CAN_DET_RANGE_RATE_060 "Detected object range rate";
BA_ "GenSigStartValue" SG_ 1544 MRR_RR_CAN_DET_RANGE_RATE_060 8192;
BA_ "GenSigCmt" SG_ 1544 MRR_RR_CAN_SCAN_INDEX_2LSB_060 "The two LSB of scan index";
BA_ "GenSigCmt" SG_ 1544 MRR_RR_CAN_DET_AMPLITUDE_060 "Detected object amplitude";
BA_ "GenSigStartValue" SG_ 1544 MRR_RR_CAN_DET_AMPLITUDE_060 64;
BA_ "GenSigCmt" SG_ 1544 MRR_RR_CAN_DET_VALID_LEVEL_060 "Detected object valid level";
BA_ "GenSigCmt" SG_ 1544 MRR_RR_CAN_DET_ELEVATION_059 "Detected object elevation position";
BA_ "GenSigStartValue" SG_ 1544 MRR_RR_CAN_DET_ELEVATION_059 63.8646288209607;
BA_ "GenSigCmt" SG_ 1544 MRR_RR_CAN_DET_SUPER_RES_TA_0060 "Super resolution target";
BA_ "SystemSignalLongSymbol" SG_ 1544 MRR_RR_CAN_DET_SUPER_RES_TA_0060 "MRR_RR_CAN_DET_SUPER_RES_TARGET_059";
BA_ "GenSigCmt" SG_ 1544 MRR_RR_CAN_DET_AZIMUTH_059 "Detected object azimuth position";
BA_ "GenSigStartValue" SG_ 1544 MRR_RR_CAN_DET_AZIMUTH_059 8194.05320813772;
BA_ "GenSigCmt" SG_ 1544 MRR_RR_CAN_DET_CONFID_ELEVA_0060 "Elevation Angle Confidence";
BA_ "SystemSignalLongSymbol" SG_ 1544 MRR_RR_CAN_DET_CONFID_ELEVA_0060 "MRR_RR_CAN_DET_CONFID_ELEVATION_059";
BA_ "GenSigCmt" SG_ 1544 MRR_RR_CAN_DET_HOST_VEH_CLU_0060 "Host vehicle clutter";
BA_ "SystemSignalLongSymbol" SG_ 1544 MRR_RR_CAN_DET_HOST_VEH_CLU_0060 "MRR_RR_CAN_DET_HOST_VEH_CLUTTER_059";
BA_ "GenSigCmt" SG_ 1544 MRR_RR_CAN_DET_RANGE_059 "Detected object range";
BA_ "GenSigCmt" SG_ 1544 MRR_RR_CAN_DET_CONFID_AZIMU_0054 "Signal to noise level";
BA_ "GenSigVtEn" SG_ 1544 MRR_RR_CAN_DET_CONFID_AZIMU_0054 "TRUE";
BA_ "SystemSignalLongSymbol" SG_ 1544 MRR_RR_CAN_DET_CONFID_AZIMU_0054 "MRR_RR_CAN_DET_CONFID_AZIMUTH_059";
BA_ "GenSigCmt" SG_ 1544 MRR_RR_CAN_DET_RANGE_RATE_059 "Detected object range rate";
BA_ "GenSigStartValue" SG_ 1544 MRR_RR_CAN_DET_RANGE_RATE_059 8192;
BA_ "GenSigCmt" SG_ 1544 MRR_RR_CAN_SCAN_INDEX_2LSB_059 "The two LSB of scan index";
BA_ "GenSigCmt" SG_ 1544 MRR_RR_CAN_DET_AMPLITUDE_059 "Detected object amplitude";
BA_ "GenSigStartValue" SG_ 1544 MRR_RR_CAN_DET_AMPLITUDE_059 64;
BA_ "GenSigCmt" SG_ 1544 MRR_RR_CAN_DET_VALID_LEVEL_059 "Detected object valid level";
BA_ "GenSigCmt" SG_ 1544 MRR_RR_CAN_DET_ELEVATION_058 "Detected object elevation position";
BA_ "GenSigStartValue" SG_ 1544 MRR_RR_CAN_DET_ELEVATION_058 63.8646288209607;
BA_ "GenSigCmt" SG_ 1544 MRR_RR_CAN_DET_SUPER_RES_TA_0061 "Super resolution target";
BA_ "SystemSignalLongSymbol" SG_ 1544 MRR_RR_CAN_DET_SUPER_RES_TA_0061 "MRR_RR_CAN_DET_SUPER_RES_TARGET_058";
BA_ "GenSigCmt" SG_ 1544 MRR_RR_CAN_DET_AZIMUTH_058 "Detected object azimuth position";
BA_ "GenSigStartValue" SG_ 1544 MRR_RR_CAN_DET_AZIMUTH_058 8194.05320813772;
BA_ "GenSigCmt" SG_ 1544 MRR_RR_CAN_DET_CONFID_ELEVA_0061 "Elevation Angle Confidence";
BA_ "SystemSignalLongSymbol" SG_ 1544 MRR_RR_CAN_DET_CONFID_ELEVA_0061 "MRR_RR_CAN_DET_CONFID_ELEVATION_058";
BA_ "GenSigCmt" SG_ 1544 MRR_RR_CAN_DET_HOST_VEH_CLU_0061 "Host vehicle clutter";
BA_ "SystemSignalLongSymbol" SG_ 1544 MRR_RR_CAN_DET_HOST_VEH_CLU_0061 "MRR_RR_CAN_DET_HOST_VEH_CLUTTER_058";
BA_ "GenSigCmt" SG_ 1544 MRR_RR_CAN_DET_RANGE_058 "Detected object range";
BA_ "GenSigCmt" SG_ 1544 MRR_RR_CAN_DET_CONFID_AZIMU_0055 "Signal to noise level";
BA_ "GenSigVtEn" SG_ 1544 MRR_RR_CAN_DET_CONFID_AZIMU_0055 "TRUE";
BA_ "SystemSignalLongSymbol" SG_ 1544 MRR_RR_CAN_DET_CONFID_AZIMU_0055 "MRR_RR_CAN_DET_CONFID_AZIMUTH_058";
BA_ "GenSigCmt" SG_ 1544 MRR_RR_CAN_DET_RANGE_RATE_058 "Detected object range rate";
BA_ "GenSigStartValue" SG_ 1544 MRR_RR_CAN_DET_RANGE_RATE_058 8192;
BA_ "GenSigCmt" SG_ 1544 MRR_RR_CAN_SCAN_INDEX_2LSB_058 "The two LSB of scan index";
BA_ "GenSigCmt" SG_ 1544 MRR_RR_CAN_DET_AMPLITUDE_058 "Detected object amplitude";
BA_ "GenSigStartValue" SG_ 1544 MRR_RR_CAN_DET_AMPLITUDE_058 64;
BA_ "GenSigCmt" SG_ 1544 MRR_RR_CAN_DET_VALID_LEVEL_058 "Detected object valid level";
BA_ "GenSigSendType" SG_ 1545 MRR_RR_CAN_DET_MID_TARGET_064 1;
BA_ "SignalDescription" SG_ 1545 MRR_RR_CAN_DET_MID_TARGET_064 "MID_Target_Discrimination";
BA_ "SignalDescription" SG_ 1545 MRR_RR_CAN_DET_Near_TARGET_064 "Near_Target_Discrimination";
BA_ "GenSigStartValue" SG_ 1545 MRR_RR_CAN_DET_ELEVATION_064 63.8646288209607;
BA_ "GenSigCmt" SG_ 1545 MRR_RR_CAN_DET_ELEVATION_064 "Detected object elevation position";
BA_ "GenSigCmt" SG_ 1545 MRR_RR_CAN_DET_CONFID_AZIMU_0056 "Signal to noise level";
BA_ "GenSigVtEn" SG_ 1545 MRR_RR_CAN_DET_CONFID_AZIMU_0056 "TRUE";
BA_ "SystemSignalLongSymbol" SG_ 1545 MRR_RR_CAN_DET_CONFID_AZIMU_0056 "MRR_RR_CAN_DET_CONFID_AZIMUTH_064";
BA_ "GenSigCmt" SG_ 1545 MRR_RR_CAN_DET_SUPER_RES_TA_0062 "Super resolution target";
BA_ "SystemSignalLongSymbol" SG_ 1545 MRR_RR_CAN_DET_SUPER_RES_TA_0062 "MRR_RR_CAN_DET_SUPER_RES_TARGET_064";
BA_ "GenSigCmt" SG_ 1545 MRR_RR_CAN_DET_CONFID_ELEVA_0062 "Elevation Angle Confidence";
BA_ "SystemSignalLongSymbol" SG_ 1545 MRR_RR_CAN_DET_CONFID_ELEVA_0062 "MRR_RR_CAN_DET_CONFID_ELEVATION_064";
BA_ "GenSigCmt" SG_ 1545 MRR_RR_CAN_DET_HOST_VEH_CLU_0062 "Host vehicle clutter";
BA_ "SystemSignalLongSymbol" SG_ 1545 MRR_RR_CAN_DET_HOST_VEH_CLU_0062 "MRR_RR_CAN_DET_HOST_VEH_CLUTTER_064";
BA_ "GenSigCmt" SG_ 1545 MRR_RR_CAN_DET_VALID_LEVEL_064 "Detected object valid level";
BA_ "GenSigCmt" SG_ 1545 MRR_RR_CAN_DET_AZIMUTH_064 "Detected object azimuth position";
BA_ "GenSigStartValue" SG_ 1545 MRR_RR_CAN_DET_AZIMUTH_064 8194.05320813772;
BA_ "GenSigCmt" SG_ 1545 MRR_RR_CAN_DET_RANGE_064 "Detected object range";
BA_ "GenSigCmt" SG_ 1545 MRR_RR_CAN_DET_RANGE_RATE_064 "Detected object range rate";
BA_ "GenSigStartValue" SG_ 1545 MRR_RR_CAN_DET_RANGE_RATE_064 8192;
BA_ "GenSigCmt" SG_ 1545 MRR_RR_CAN_DET_AMPLITUDE_064 "Detected object amplitude";
BA_ "GenSigStartValue" SG_ 1545 MRR_RR_CAN_DET_AMPLITUDE_064 64;
BA_ "GenSigCmt" SG_ 1545 MRR_RR_CAN_SCAN_INDEX_2LSB_064 "The two LSB of scan index";
BA_ "GenSigSendType" SG_ 263 MRR_RR_Sensor_Position_Lock 1;
BA_ "SystemSignalLongSymbol" SG_ 263 MRR_RR_CAN_TX_SCAN_INDEX_TRACKER "MRR_RR_CAN_TX_SCAN_INDEX_TRACKER_OWN";
BA_ "SystemSignalLongSymbol" SG_ 263 MRR_RR_CAN_TX_SCN_INDEX_TRKER_FU "MRR_RR_CAN_TX_SCN_INDEX_TRKER_FUSED";
BA_ "SystemSignalLongSymbol" SG_ 320 MRR_RL_CAN_TX_VEH_SPEED_DIRECTIO "MRR_RL_CAN_TX_VEH_SPEED_DIRECTION";
BA_ "SystemSignalLongSymbol" SG_ 320 MRR_RL_CAN_TX_STEERING_ANGLE_SIG "MRR_RL_CAN_TX_STEERING_ANGLE_SIGN";
BA_ "GenSigSendType" SG_ 320 MRR_RL_CAN_TX_STEERING_ANGLE 1;
BA_ "GenSigSendType" SG_ 327 MRR_RL_Sensor_Position_Lock 1;
BA_ "SystemSignalLongSymbol" SG_ 327 MRR_RL_CAN_TX_SCAN_INDEX_TRACKER "MRR_RL_CAN_TX_SCAN_INDEX_TRACKER_OWN";
BA_ "SystemSignalLongSymbol" SG_ 327 MRR_RL_CAN_TX_SCN_INDEX_TRKER_FU "MRR_RL_CAN_TX_SCN_INDEX_TRKER_FUSED";
BA_ "GenSigCycleTime" SG_ 322 MRR_RL_CAN_PCAN_PROTOCOL_PROMOTE 1000;
BA_ "GenSigSendType" SG_ 322 MRR_RL_CAN_PCAN_PROTOCOL_PROMOTE 0;
BA_ "GenSigSendType" SG_ 322 MRR_RL_CAN_TX_SW_VERSION_DSP 0;
BA_ "GenSigCycleTime" SG_ 322 MRR_RL_CAN_TX_SW_VERSION_DSP 1000;
BA_ "GenSigCycleTime" SG_ 322 MRR_RL_CAN_TX_SW_VERSION_ARM 1000;
BA_ "GenSigSendType" SG_ 322 MRR_RL_CAN_TX_SW_VERSION_ARM 0;
BA_ "GenSigCycleTime" SG_ 322 MRR_RL_CAN_TX_PCAN_PROTOCOL_MINO 1000;
BA_ "GenSigSendType" SG_ 322 MRR_RL_CAN_TX_PCAN_PROTOCOL_MINO 0;
BA_ "SystemSignalLongSymbol" SG_ 322 MRR_RL_CAN_TX_PCAN_PROTOCOL_MINO "MRR_RL_CAN_TX_PCAN_PROTOCOL_MINOR";
BA_ "GenSigCycleTime" SG_ 322 MRR_RL_CAN_TX_PCAN_PROTOCOL_MAJO 1000;
BA_ "GenSigSendType" SG_ 322 MRR_RL_CAN_TX_PCAN_PROTOCOL_MAJO 0;
BA_ "SystemSignalLongSymbol" SG_ 322 MRR_RL_CAN_TX_PCAN_PROTOCOL_MAJO "MRR_RL_CAN_TX_PCAN_PROTOCOL_MAJOR";
BA_ "GenSigCycleTime" SG_ 322 MRR_RL_CAN_Dyn_Align_Algorithm_V 1000;
BA_ "GenSigSendType" SG_ 322 MRR_RL_CAN_Dyn_Align_Algorithm_V 0;
BA_ "SystemSignalLongSymbol" SG_ 322 MRR_RL_CAN_Dyn_Align_Algorithm_V "MRR_RL_CAN_Dyn_Align_Algorithm_Version_Major";
BA_ "GenSigCycleTime" SG_ 322 MRR_RL_CAN_Dyn_Align_Algori_0000 1000;
BA_ "GenSigSendType" SG_ 322 MRR_RL_CAN_Dyn_Align_Algori_0000 0;
BA_ "SystemSignalLongSymbol" SG_ 322 MRR_RL_CAN_Dyn_Align_Algori_0000 "MRR_RL_CAN_Dyn_Align_Algorithm_Version_Minor";
BA_ "GenSigCycleTime" SG_ 322 MRR_RL_CAN_Dyn_Align_Algori_0001 1000;
BA_ "GenSigSendType" SG_ 322 MRR_RL_CAN_Dyn_Align_Algori_0001 0;
BA_ "SystemSignalLongSymbol" SG_ 322 MRR_RL_CAN_Dyn_Align_Algori_0001 "MRR_RL_CAN_Dyn_Align_Algorithm_Version_Promote";
BA_ "GenSigCycleTime" SG_ 322 MRR_RL_Core_Radar_BB_Version_Fie 1000;
BA_ "GenSigSendType" SG_ 322 MRR_RL_Core_Radar_BB_Version_Fie 0;
BA_ "SystemSignalLongSymbol" SG_ 322 MRR_RL_Core_Radar_BB_Version_Fie "MRR_RL_Core_Radar_BB_Version_Field";
BA_ "GenSigCycleTime" SG_ 322 MRR_RL_Core_Radar_BB_Version_Pro 1000;
BA_ "GenSigSendType" SG_ 322 MRR_RL_Core_Radar_BB_Version_Pro 0;
BA_ "SystemSignalLongSymbol" SG_ 322 MRR_RL_Core_Radar_BB_Version_Pro "MRR_RL_Core_Radar_BB_Version_Promote";
BA_ "GenSigCycleTime" SG_ 322 MRR_RL_Core_Radar_BB_Version_Min 1000;
BA_ "GenSigSendType" SG_ 322 MRR_RL_Core_Radar_BB_Version_Min 0;
BA_ "SystemSignalLongSymbol" SG_ 322 MRR_RL_Core_Radar_BB_Version_Min "MRR_RL_Core_Radar_BB_Version_Minor";
BA_ "GenSigCycleTime" SG_ 322 MRR_RL_Core_Radar_BB_Version_Maj 1000;
BA_ "GenSigSendType" SG_ 322 MRR_RL_Core_Radar_BB_Version_Maj 0;
BA_ "SystemSignalLongSymbol" SG_ 322 MRR_RL_Core_Radar_BB_Version_Maj "MRR_RL_Core_Radar_BB_Version_Major";
BA_ "GenSigCycleTime" SG_ 322 MRR_RL_CAN_USC_Field 1000;
BA_ "GenSigSendType" SG_ 322 MRR_RL_CAN_USC_Field 0;
BA_ "GenSigCycleTime" SG_ 322 MRR_RL_CAN_USC_Promote 1000;
BA_ "GenSigSendType" SG_ 322 MRR_RL_CAN_USC_Promote 0;
BA_ "GenSigCycleTime" SG_ 322 MRR_RL_CAN_USC_Minor 1000;
BA_ "GenSigSendType" SG_ 322 MRR_RL_CAN_USC_Minor 0;
BA_ "GenSigCycleTime" SG_ 322 MRR_RL_CAN_USC_Major 1000;
BA_ "GenSigSendType" SG_ 322 MRR_RL_CAN_USC_Major 0;
BA_ "GenSigCycleTime" SG_ 322 MRR_RL_CAN_SMC_Field 1000;
BA_ "GenSigSendType" SG_ 322 MRR_RL_CAN_SMC_Field 0;
BA_ "GenSigCycleTime" SG_ 322 MRR_RL_CAN_SMC_Promote 1000;
BA_ "GenSigSendType" SG_ 322 MRR_RL_CAN_SMC_Promote 0;
BA_ "GenSigCycleTime" SG_ 322 MRR_RL_CAN_SMC_Minor 1000;
BA_ "GenSigSendType" SG_ 322 MRR_RL_CAN_SMC_Minor 0;
BA_ "GenSigCycleTime" SG_ 322 MRR_RL_CAN_SMC_Major 1000;
BA_ "GenSigSendType" SG_ 322 MRR_RL_CAN_SMC_Major 0;
BA_ "GenSigSendType" SG_ 322 MRR_RL_CAN_TX_Field 0;
BA_ "GenSigCycleTime" SG_ 322 MRR_RL_CAN_TX_Field 1000;
BA_ "GenSigSendType" SG_ 322 MRR_RL_CAN_TX_Promote 0;
BA_ "GenSigCycleTime" SG_ 322 MRR_RL_CAN_TX_Promote 1000;
BA_ "GenSigSendType" SG_ 322 MRR_RL_CAN_TX_Major 0;
BA_ "GenSigCycleTime" SG_ 322 MRR_RL_CAN_TX_Major 1000;
BA_ "GenSigSendType" SG_ 322 MRR_RL_CAN_TX_Hardware 0;
BA_ "GenSigCycleTime" SG_ 322 MRR_RL_CAN_TX_Hardware 1000;
BA_ "GenSigSendType" SG_ 322 MRR_RL_CAN_TX_SERIAL_NUMBER_SEQU 0;
BA_ "GenSigCycleTime" SG_ 322 MRR_RL_CAN_TX_SERIAL_NUMBER_SEQU 1000;
BA_ "SystemSignalLongSymbol" SG_ 322 MRR_RL_CAN_TX_SERIAL_NUMBER_SEQU "MRR_RL_CAN_TX_SERIAL_NUMBER_SEQUENCE";
BA_ "GenSigSendType" SG_ 322 MRR_RL_CAN_TX_SERIAL_NUM_JULIAN_ 0;
BA_ "GenSigCycleTime" SG_ 322 MRR_RL_CAN_TX_SERIAL_NUM_JULIAN_ 1000;
BA_ "SystemSignalLongSymbol" SG_ 322 MRR_RL_CAN_TX_SERIAL_NUM_JULIAN_ "MRR_RL_CAN_TX_SERIAL_NUM_JULIAN_YEAR";
BA_ "GenSigSendType" SG_ 322 MRR_RL_CAN_TX_SERIAL_NUM_JU_0000 0;
BA_ "GenSigCycleTime" SG_ 322 MRR_RL_CAN_TX_SERIAL_NUM_JU_0000 1000;
BA_ "SystemSignalLongSymbol" SG_ 322 MRR_RL_CAN_TX_SERIAL_NUM_JU_0000 "MRR_RL_CAN_TX_SERIAL_NUM_JULIAN_DAY";
BA_ "GenSigSendType" SG_ 322 MRR_RL_CAN_TX_ARM_THROUGHPUT 0;
BA_ "GenSigCycleTime" SG_ 322 MRR_RL_CAN_TX_ARM_THROUGHPUT 1000;
BA_ "GenSigSendType" SG_ 322 MRR_RL_CAN_TX_SYSTEM_STATUS 0;
BA_ "GenSigCycleTime" SG_ 322 MRR_RL_CAN_TX_SYSTEM_STATUS 1000;
BA_ "GenSigSendType" SG_ 322 MRR_RL_CAN_TX_LOOK_TYPE_1 0;
BA_ "GenSigCycleTime" SG_ 322 MRR_RL_CAN_TX_LOOK_TYPE_1 1000;
BA_ "GenSigSendType" SG_ 322 MRR_RL_CAN_TX_OVERHEAT_ERROR 0;
BA_ "GenSigCycleTime" SG_ 322 MRR_RL_CAN_TX_OVERHEAT_ERROR 1000;
BA_ "GenSigSendType" SG_ 322 MRR_RL_CAN_TX_RANGE_PERF_ERROR 0;
BA_ "GenSigCycleTime" SG_ 322 MRR_RL_CAN_TX_RANGE_PERF_ERROR 1000;
BA_ "GenSigSendType" SG_ 322 MRR_RL_CAN_TX_COMM_ERROR 0;
BA_ "GenSigCycleTime" SG_ 322 MRR_RL_CAN_TX_COMM_ERROR 1000;
BA_ "GenSigSendType" SG_ 322 MRR_RL_CAN_TX_INTERNAL_ERROR 0;
BA_ "GenSigCycleTime" SG_ 322 MRR_RL_CAN_TX_INTERNAL_ERROR 1000;
BA_ "GenSigSendType" SG_ 322 MRR_RL_CAN_TX_XCVR_OPERATIONAL 0;
BA_ "GenSigCycleTime" SG_ 322 MRR_RL_CAN_TX_XCVR_OPERATIONAL 1000;
BA_ "GenSigCycleTime" SG_ 322 MRR_RL_CAN_PBL_Field_Revision 1000;
BA_ "GenSigSendType" SG_ 322 MRR_RL_CAN_PBL_Field_Revision 0;
BA_ "GenSigSendType" SG_ 322 MRR_RL_CAN_PBL_Promote_Revision 0;
BA_ "GenSigCycleTime" SG_ 322 MRR_RL_CAN_PBL_Promote_Revision 1000;
BA_ "GenSigSendType" SG_ 322 MRR_RL_CAN_SW_Field_Revision 0;
BA_ "GenSigCycleTime" SG_ 322 MRR_RL_CAN_SW_Field_Revision 1000;
BA_ "GenSigSendType" SG_ 322 MRR_RL_CAN_SW_Promote_Revision 0;
BA_ "GenSigCycleTime" SG_ 322 MRR_RL_CAN_SW_Promote_Revision 1000;
BA_ "GenSigSendType" SG_ 322 MRR_RL_CAN_SW_Field 0;
BA_ "GenSigCycleTime" SG_ 322 MRR_RL_CAN_SW_Field 1000;
BA_ "GenSigSendType" SG_ 322 MRR_RL_CAN_SW_Release_Revision 0;
BA_ "GenSigCycleTime" SG_ 322 MRR_RL_CAN_SW_Release_Revision 1000;
BA_ "GenSigSendType" SG_ 322 MRR_RL_CAN_PBL_Release_Revision 0;
BA_ "GenSigCycleTime" SG_ 322 MRR_RL_CAN_PBL_Release_Revision 1000;
BA_ "GenSigCycleTime" SG_ 333 MRR_RL_CAN_Dolphin_AFC 100;
BA_ "GenSigSendType" SG_ 333 MRR_RL_CAN_Dolphin_AFC 0;
BA_ "GenSigSendType" SG_ 333 MRR_RL_CAN_Dolphin_Tx3 0;
BA_ "GenSigCycleTime" SG_ 333 MRR_RL_CAN_Dolphin_Tx3 100;
BA_ "GenSigSendType" SG_ 333 MRR_RL_CAN_Dolphin_Tx2 0;
BA_ "GenSigCycleTime" SG_ 333 MRR_RL_CAN_Dolphin_Tx2 100;
BA_ "GenSigSendType" SG_ 333 MRR_RL_CAN_1_8_V 0;
BA_ "GenSigCycleTime" SG_ 333 MRR_RL_CAN_1_8_V 100;
BA_ "GenSigSendType" SG_ 333 MRR_RL_CAN_BATT_VOLTS 0;
BA_ "GenSigCycleTime" SG_ 333 MRR_RL_CAN_BATT_VOLTS 100;
BA_ "GenSigSendType" SG_ 333 MRR_RL_CAN_1_25_V 0;
BA_ "GenSigCycleTime" SG_ 333 MRR_RL_CAN_1_25_V 100;
BA_ "GenSigSendType" SG_ 333 MRR_RL_CAN_5_V 0;
BA_ "GenSigCycleTime" SG_ 333 MRR_RL_CAN_5_V 100;
BA_ "GenSigSendType" SG_ 333 MRR_RL_CAN_1_1_V 0;
BA_ "GenSigCycleTime" SG_ 333 MRR_RL_CAN_1_1_V 100;
BA_ "GenSigSendType" SG_ 333 MRR_RL_CAN_2_3_V 0;
BA_ "GenSigCycleTime" SG_ 333 MRR_RL_CAN_2_3_V 100;
BA_ "GenSigSendType" SG_ 333 MRR_RL_CAN_Dolphin_Tx1 0;
BA_ "GenSigCycleTime" SG_ 333 MRR_RL_CAN_Dolphin_Tx1 100;
BA_ "GenSigSendType" SG_ 333 MRR_RL_CAN_RRU_Temp1 0;
BA_ "GenSigCycleTime" SG_ 333 MRR_RL_CAN_RRU_Temp1 100;
BA_ "GenSigSendType" SG_ 328 MRR_CAN_RadarWaveform_RL 1;
BA_ "GenSigCmt" SG_ 328 MRR_RL_CAN_RANGE_COVERAGE "CAN range coverage";
BA_ "GenSigCmt" SG_ 328 MRR_RL_CAN_DOPPLER_COVERAGE "CAN range coverage";
BA_ "GenSigCmt" SG_ 328 MRR_RL_CAN_FOV_HOR "CAN range coverage";
BA_ "GenSigCmt" SG_ 328 MRR_RL_CAN_FOV_VER "CAN range coverage";
BA_ "GenSigSendType" SG_ 321 MRR_RL_Dolphin_Chip_ID_Part2 0;
BA_ "GenSigCycleTime" SG_ 321 MRR_RL_Dolphin_Chip_ID_Part2 1000;
BA_ "GenSigCycleTime" SG_ 321 MRR_RL_Dolphin_Chip_ID_Part1 1000;
BA_ "GenSigSendType" SG_ 321 MRR_RL_Dolphin_Chip_ID_Part1 0;
BA_ "GenSigCycleTime" SG_ 321 MRR_RL_RRU_Chip_ID_Part4 1000;
BA_ "GenSigSendType" SG_ 321 MRR_RL_RRU_Chip_ID_Part4 0;
BA_ "GenSigCycleTime" SG_ 321 MRR_RL_RRU_Chip_ID_Part3 1000;
BA_ "GenSigSendType" SG_ 321 MRR_RL_RRU_Chip_ID_Part3 0;
BA_ "GenSigCycleTime" SG_ 321 MRR_RL_RRU_Chip_ID_Part2 1000;
BA_ "GenSigSendType" SG_ 321 MRR_RL_RRU_Chip_ID_Part2 0;
BA_ "GenSigCycleTime" SG_ 321 MRR_RL_RRU_Chip_ID_Part1 1000;
BA_ "GenSigSendType" SG_ 321 MRR_RL_RRU_Chip_ID_Part1 0;
BA_ "GenSigCycleTime" SG_ 321 MRR_RL_CAN_TX_HW_VERSION 1000;
BA_ "GenSigSendType" SG_ 321 MRR_RL_CAN_TX_HW_VERSION 0;
BA_ "GenSigCmt" SG_ 331 MRR_RL_CAN_VRTCL_ALIGN_UPDATES_N "Number of alignment updates done.";
BA_ "GenSigSendType" SG_ 331 MRR_RL_CAN_VRTCL_ALIGN_UPDATES_N 1;
BA_ "SystemSignalLongSymbol" SG_ 331 MRR_RL_CAN_VRTCL_ALIGN_UPDATES_N "MRR_RL_CAN_VRTCL_ALIGN_UPDATES_Nbr";
BA_ "GenSigCmt" SG_ 331 MRR_RL_CAN_HRZNTL_ALIGN_UPDATES_ "Number of alignment updates done.";
BA_ "SystemSignalLongSymbol" SG_ 331 MRR_RL_CAN_HRZNTL_ALIGN_UPDATES_ "MRR_RL_CAN_HRZNTL_ALIGN_UPDATES_Nbr";
BA_ "SystemSignalLongSymbol" SG_ 331 MRR_RL_Horizontal_Alignment_Stat "MRR_RL_Horizontal_Alignment_Status";
BA_ "SystemSignalLongSymbol" SG_ 331 MRR_RL_Horizontal_Alignment_0000 "MRR_RL_Horizontal_Alignment_State";
BA_ "GenSigStartValue" SG_ 331 MRR_RL_Align_Vertical_Ref 511.500000000001;
BA_ "GenSigStartValue" SG_ 331 MRR_RL_Align_Vertical_Angle 511.500000000001;
BA_ "GenSigStartValue" SG_ 331 MRR_RL_Align_Horizontal_Angle 511.5;
BA_ "GenSigStartValue" SG_ 331 MRR_RL_Align_Horizontal_Ref 511.5;
VAL_ 1539 MRR_RR_CAN_DET_CONFID_AZIMU_0018 3 "Low" 2 "MidLow" 1 "MidHigh" 0 "High" ;
VAL_ 1539 MRR_RR_CAN_DET_CONFID_AZIMU_0019 3 "Low" 2 "MidLow" 1 "MidHigh" 0 "High" ;
VAL_ 1539 MRR_RR_CAN_DET_CONFID_AZIMU_0020 3 "Low" 2 "MidLow" 1 "MidHigh" 0 "High" ;
VAL_ 1539 MRR_RR_CAN_DET_CONFID_AZIMU_0021 3 "Low" 2 "MidLow" 1 "MidHigh" 0 "High" ;
VAL_ 1539 MRR_RR_CAN_DET_CONFID_AZIMU_0022 3 "Low" 2 "MidLow" 1 "MidHigh" 0 "High" ;
VAL_ 1539 MRR_RR_CAN_DET_CONFID_AZIMU_0023 3 "Low" 2 "MidLow" 1 "MidHigh" 0 "High" ;
VAL_ 1539 MRR_RR_CAN_DET_CONFID_AZIMU_0024 3 "Low" 2 "MidLow" 1 "MidHigh" 0 "High" ;
VAL_ 1540 MRR_RR_CAN_DET_CONFID_AZIMU_0025 3 "Low" 2 "MidLow" 1 "MidHigh" 0 "High" ;
VAL_ 1540 MRR_RR_CAN_DET_CONFID_AZIMUTH_03 3 "Low" 2 "MidLow" 1 "MidHigh" 0 "High" ;
VAL_ 1540 MRR_RR_CAN_DET_CONFID_AZIMU_0026 3 "Low" 2 "MidLow" 1 "MidHigh" 0 "High" ;
VAL_ 1540 MRR_RR_CAN_DET_CONFID_AZIMU_0027 3 "Low" 2 "MidLow" 1 "MidHigh" 0 "High" ;
VAL_ 1540 MRR_RR_CAN_DET_CONFID_AZIMU_0028 3 "Low" 2 "MidLow" 1 "MidHigh" 0 "High" ;
VAL_ 1540 MRR_RR_CAN_DET_CONFID_AZIMU_0029 3 "Low" 2 "MidLow" 1 "MidHigh" 0 "High" ;
VAL_ 1540 MRR_RR_CAN_DET_CONFID_AZIMU_0030 3 "Low" 2 "MidLow" 1 "MidHigh" 0 "High" ;
VAL_ 1541 MRR_RR_CAN_DET_CONFID_AZIMU_0031 3 "Low" 2 "MidLow" 1 "MidHigh" 0 "High" ;
VAL_ 1541 MRR_RR_CAN_DET_CONFID_AZIMUTH_04 3 "Low" 2 "MidLow" 1 "MidHigh" 0 "High" ;
VAL_ 1541 MRR_RR_CAN_DET_CONFID_AZIMU_0032 3 "Low" 2 "MidLow" 1 "MidHigh" 0 "High" ;
VAL_ 1541 MRR_RR_CAN_DET_CONFID_AZIMU_0033 3 "Low" 2 "MidLow" 1 "MidHigh" 0 "High" ;
VAL_ 1541 MRR_RR_CAN_DET_CONFID_AZIMU_0034 3 "Low" 2 "MidLow" 1 "MidHigh" 0 "High" ;
VAL_ 1541 MRR_RR_CAN_DET_CONFID_AZIMU_0035 3 "Low" 2 "MidLow" 1 "MidHigh" 0 "High" ;
VAL_ 1541 MRR_RR_CAN_DET_CONFID_AZIMU_0036 3 "Low" 2 "MidLow" 1 "MidHigh" 0 "High" ;
VAL_ 1542 MRR_RR_CAN_DET_CONFID_AZIMU_0037 3 "Low" 2 "MidLow" 1 "MidHigh" 0 "High" ;
VAL_ 1542 MRR_RR_CAN_DET_CONFID_AZIMU_0038 3 "Low" 2 "MidLow" 1 "MidHigh" 0 "High" ;
VAL_ 1542 MRR_RR_CAN_DET_CONFID_AZIMU_0039 3 "Low" 2 "MidLow" 1 "MidHigh" 0 "High" ;
VAL_ 1542 MRR_RR_CAN_DET_CONFID_AZIMU_0040 3 "Low" 2 "MidLow" 1 "MidHigh" 0 "High" ;
VAL_ 1542 MRR_RR_CAN_DET_CONFID_AZIMU_0041 3 "Low" 2 "MidLow" 1 "MidHigh" 0 "High" ;
VAL_ 1542 MRR_RR_CAN_DET_CONFID_AZIMU_0042 3 "Low" 2 "MidLow" 1 "MidHigh" 0 "High" ;
VAL_ 1542 MRR_RR_CAN_DET_CONFID_AZIMU_0043 3 "Low" 2 "MidLow" 1 "MidHigh" 0 "High" ;
VAL_ 1543 MRR_RR_CAN_DET_CONFID_AZIMUTH_05 3 "Low" 2 "MidLow" 1 "MidHigh" 0 "High" ;
VAL_ 1543 MRR_RR_CAN_DET_CONFID_AZIMU_0044 3 "Low" 2 "MidLow" 1 "MidHigh" 0 "High" ;
VAL_ 1543 MRR_RR_CAN_DET_CONFID_AZIMU_0045 3 "Low" 2 "MidLow" 1 "MidHigh" 0 "High" ;
VAL_ 1543 MRR_RR_CAN_DET_CONFID_AZIMU_0046 3 "Low" 2 "MidLow" 1 "MidHigh" 0 "High" ;
VAL_ 1543 MRR_RR_CAN_DET_CONFID_AZIMU_0047 3 "Low" 2 "MidLow" 1 "MidHigh" 0 "High" ;
VAL_ 1543 MRR_RR_CAN_DET_CONFID_AZIMU_0048 3 "Low" 2 "MidLow" 1 "MidHigh" 0 "High" ;
VAL_ 1543 MRR_RR_CAN_DET_CONFID_AZIMU_0049 3 "Low" 2 "MidLow" 1 "MidHigh" 0 "High" ;
VAL_ 1544 MRR_RR_CAN_DET_CONFID_AZIMU_0050 3 "Low" 2 "MidLow" 1 "MidHigh" 0 "High" ;
VAL_ 1544 MRR_RR_CAN_DET_CONFID_AZIMUTH_06 3 "Low" 2 "MidLow" 1 "MidHigh" 0 "High" ;
VAL_ 1544 MRR_RR_CAN_DET_CONFID_AZIMU_0051 3 "Low" 2 "MidLow" 1 "MidHigh" 0 "High" ;
VAL_ 1544 MRR_RR_CAN_DET_CONFID_AZIMU_0052 3 "Low" 2 "MidLow" 1 "MidHigh" 0 "High" ;
VAL_ 1544 MRR_RR_CAN_DET_CONFID_AZIMU_0053 3 "Low" 2 "MidLow" 1 "MidHigh" 0 "High" ;
VAL_ 1544 MRR_RR_CAN_DET_CONFID_AZIMU_0054 3 "Low" 2 "MidLow" 1 "MidHigh" 0 "High" ;
VAL_ 1544 MRR_RR_CAN_DET_CONFID_AZIMU_0055 3 "Low" 2 "MidLow" 1 "MidHigh" 0 "High" ;
VAL_ 1545 MRR_RR_CAN_DET_CONFID_AZIMU_0056 3 "Low" 2 "MidLow" 1 "MidHigh" 0 "High" ;
VAL_ 263 MRR_RR_Sensor_Position 4 "Rear Left" 3 "Rear Right" 2 "Front Left" 1 "Front Right" 0 "Unknown" ;
VAL_ 263 MRR_RR_Sensor_Position_Lock 1 "Unlocked" 0 "Locked" ;
VAL_ 263 MRR_RR_CAN_LOOK_ID 3 "MRML" 2 "MRLL" 1 "LRML" 0 "LRLL" ;
VAL_ 327 MRR_RL_Sensor_Position 4 "Rear Left" 3 "Rear Right" 2 "Front Left" 1 "Front Right" 0 "Unknow" ;
VAL_ 327 MRR_RL_Sensor_Position_Lock 1 "Unlocked" 0 "Locked" ;
VAL_ 327 MRR_RL_CAN_LOOK_ID 3 "MRML" 2 "MRLL" 1 "LRML" 0 "LRLL" ;
VAL_ 322 MRR_RL_CAN_TX_SW_VERSION_DSP 71426 "2.23.1" 71170 "2.22.1" 5890 "2.23" ;
VAL_ 322 MRR_RL_CAN_TX_SW_VERSION_ARM 66827 "1.5.11" 66826 "1.5.10" ;
VAL_ 328 MRR_CAN_RadarWaveform_RL 4 "Unused" 3 "AutoHitch" 2 "Standard_Rear" 1 "Standard_Front" 0 "Unknown" ;
VAL_ 331 MRR_RL_Horizontal_Alignment_Stat 15 "Undefined" 14 "Undefined" 13 "Low Amplitude (Flat-plate only)" 12 "No Peak (Flat-plate only)" 11 "Fail Ver and Hor OutOfRange" 10 "Fail Vertical Align OutOfRange" 9 "Fail Horizontal Align OutOfRange" 8 "Fail Time Out" 7 "Fail Only SODR Target Found" 6 "Fail Only SODL Target Found" 5 "Fail Variance Too Large" 4 "Fail Deviation Too Large" 3 "Fail No Target" 2 "Success" 1 "Busy" 0 "Off" ;
VAL_ 331 MRR_RL_Vertical_Alignment_Status 15 "Undefined" 14 "Undefined" 13 "Low Amplitude (Flat-plate only)" 12 "No Peak (Flat-plate only)" 11 "Fail Ver and Hor OutOfRange" 10 "Fail Vertical Align OutOfRange" 9 "Fail Horizontal Align OutOfRange" 8 "Fail Time Out" 7 "Fail Only SODR Target Found" 6 "Fail Only SODL Target Found" 5 "Fail Variance Too Large" 4 "Fail Deviation Too Large" 3 "Fail No Target" 2 "Success" 1 "Busy" 0 "Off" ;
VAL_ 331 MRR_RL_Vertical_Alignment_State 6 "Static alignment flat-plate" 5 "Static alignment 2-target" 4 "Static alignment 1-target" 3 "Service alignment" 2 "Short track alignment" 1 "Auto alignment" 0 "Off" ;
VAL_ 331 MRR_RL_Horizontal_Alignment_0000 6 "Static alignment flat-plate" 5 "Static alignment 2-target" 4 "Static alignment 1-target" 3 "Service alignment" 2 "Short track alignment" 1 "Auto alignment" 0 "Off" ;
VAL_ 331 MRR_RL_Align_Vertical_QF 3 "Accurate" 2 "Innacurate" 1 "Temporarily undefined (Faulty)" 0 "Undefined" ;
VAL_ 331 MRR_RL_Align_Horizontal_QF 3 "Accurate" 2 "Innacurate" 1 "Temporarily undefined (Faulty)" 0 "Undefined" ;
SIG_GROUP_ 1539 MRR_RR_Detection_022_028 1 : MRR_RR_CAN_DET_Near_TARGET_028 MRR_RR_CAN_DET_Near_TARGET_027 MRR_RR_CAN_DET_Near_TARGET_026 MRR_RR_CAN_DET_Near_TARGET_025 MRR_RR_CAN_DET_Near_TARGET_024 MRR_RR_CAN_DET_Near_TARGET_023 MRR_RR_CAN_DET_Near_TARGET_022 MRR_RR_CAN_DET_MID_TARGET_022 MRR_RR_CAN_DET_MID_TARGET_023 MRR_RR_CAN_DET_MID_TARGET_024 MRR_RR_CAN_DET_MID_TARGET_025 MRR_RR_CAN_DET_MID_TARGET_026 MRR_RR_CAN_DET_MID_TARGET_027 MRR_RR_CAN_DET_MID_TARGET_028 MRR_RR_CAN_DET_ELEVATION_022 MRR_RR_CAN_DET_AMPLITUDE_025 MRR_RR_CAN_DET_CONFID_AZIMU_0018 MRR_RR_CAN_SCAN_INDEX_2LSB_023 MRR_RR_CAN_DET_RANGE_RATE_023 MRR_RR_CAN_DET_AMPLITUDE_023 MRR_RR_CAN_DET_SUPER_RES_TA_0020 MRR_RR_CAN_DET_AZIMUTH_022 MRR_RR_CAN_DET_CONFID_ELEVA_0020 MRR_RR_CAN_DET_CONFID_AZIMU_0024 MRR_RR_CAN_DET_HOST_VEH_CLU_0020 MRR_RR_CAN_DET_RANGE_022 MRR_RR_CAN_DET_CONFID_ELEVA_0026 MRR_RR_CAN_DET_SUPER_RES_TA_0026 MRR_RR_CAN_SCAN_INDEX_2LSB_026 MRR_RR_CAN_DET_RANGE_025 MRR_RR_CAN_SCAN_INDEX_2LSB_025 MRR_RR_CAN_DET_VALID_LEVEL_025 MRR_RR_CAN_DET_AMPLITUDE_026 MRR_RR_CAN_DET_VALID_LEVEL_022 MRR_RR_CAN_DET_CONFID_AZIMU_0022 MRR_RR_CAN_DET_AZIMUTH_025 MRR_RR_CAN_DET_RANGE_RATE_025 MRR_RR_CAN_DET_CONFID_ELEVA_0025 MRR_RR_CAN_DET_ELEVATION_024 MRR_RR_CAN_DET_AZIMUTH_024 MRR_RR_CAN_DET_RANGE_RATE_024 MRR_RR_CAN_DET_SUPER_RES_TA_0025 MRR_RR_CAN_DET_VALID_LEVEL_023 MRR_RR_CAN_DET_CONFID_AZIMU_0023 MRR_RR_CAN_SCAN_INDEX_2LSB_024 MRR_RR_CAN_DET_HOST_VEH_CLU_0026 MRR_RR_CAN_DET_VALID_LEVEL_024 MRR_RR_CAN_DET_RANGE_024 MRR_RR_CAN_DET_HOST_VEH_CLU_0025 MRR_RR_CAN_DET_AZIMUTH_023 MRR_RR_CAN_DET_CONFID_ELEVA_0024 MRR_RR_CAN_DET_RANGE_026 MRR_RR_CAN_DET_CONFID_AZIMU_0021 MRR_RR_CAN_DET_ELEVATION_026 MRR_RR_CAN_DET_SUPER_RES_TA_0023 MRR_RR_CAN_DET_AZIMUTH_026 MRR_RR_CAN_DET_CONFID_ELEVA_0023 MRR_RR_CAN_DET_SUPER_RES_TA_0024 MRR_RR_CAN_DET_RANGE_RATE_026 MRR_RR_CAN_DET_VALID_LEVEL_026 MRR_RR_CAN_DET_AMPLITUDE_024 MRR_RR_CAN_DET_VALID_LEVEL_027 MRR_RR_CAN_DET_RANGE_028 MRR_RR_CAN_SCAN_INDEX_2LSB_027 MRR_RR_CAN_DET_AMPLITUDE_027 MRR_RR_CAN_DET_RANGE_027 MRR_RR_CAN_DET_RANGE_023 MRR_RR_CAN_DET_HOST_VEH_CLU_0024 MRR_RR_CAN_DET_ELEVATION_025 MRR_RR_CAN_DET_AMPLITUDE_028 MRR_RR_CAN_DET_ELEVATION_027 MRR_RR_CAN_DET_RANGE_RATE_027 MRR_RR_CAN_DET_ELEVATION_023 MRR_RR_CAN_DET_RANGE_RATE_022 MRR_RR_CAN_DET_AMPLITUDE_022 MRR_RR_CAN_SCAN_INDEX_2LSB_022 MRR_RR_DET_MC_004 MRR_RR_CAN_DET_ELEVATION_028 MRR_RR_CAN_DET_AZIMUTH_028 MRR_RR_CAN_DET_HOST_VEH_CLU_0021 MRR_RR_CAN_DET_RANGE_RATE_028 MRR_RR_CAN_DET_VALID_LEVEL_028 MRR_RR_CAN_DET_AZIMUTH_027 MRR_RR_CAN_DET_SUPER_RES_TA_0022 MRR_RR_CAN_DET_CONFID_ELEVA_0022 MRR_RR_CAN_DET_CONFID_AZIMU_0020 MRR_RR_CAN_DET_HOST_VEH_CLU_0022 MRR_RR_CAN_DET_HOST_VEH_CLU_0023 MRR_RR_CAN_SCAN_INDEX_2LSB_028 MRR_RR_CAN_DET_CONFID_AZIMU_0019 MRR_RR_CAN_DET_CONFID_ELEVA_0021 MRR_RR_CAN_DET_SUPER_RES_TA_0021 MRR_RR_DET_CRC_004;
SIG_GROUP_ 1540 MRR_RR_Detection_029_035 1 : MRR_RR_CAN_DET_Near_TARGET_035 MRR_RR_CAN_DET_Near_TARGET_034 MRR_RR_CAN_DET_Near_TARGET_033 MRR_RR_CAN_DET_Near_TARGET_032 MRR_RR_CAN_DET_Near_TARGET_031 MRR_RR_CAN_DET_Near_TARGET_030 MRR_RR_CAN_DET_Near_TARGET_029 MRR_RR_CAN_DET_MID_TARGET_029 MRR_RR_CAN_DET_MID_TARGET_030 MRR_RR_CAN_DET_MID_TARGET_031 MRR_RR_CAN_DET_MID_TARGET_032 MRR_RR_CAN_DET_MID_TARGET_033 MRR_RR_CAN_DET_MID_TARGET_034 MRR_RR_CAN_DET_MID_TARGET_035 MRR_RR_CAN_DET_CONFID_AZIMU_0025 MRR_RR_CAN_DET_ELEVATION_029 MRR_RR_CAN_DET_VALID_LEVEL_029 MRR_RR_CAN_SCAN_INDEX_2LSB_030 MRR_RR_CAN_DET_VALID_LEVEL_030 MRR_RR_CAN_DET_AMPLITUDE_030 MRR_RR_CAN_DET_AZIMUTH_029 MRR_RR_CAN_DET_RANGE_029 MRR_RR_CAN_DET_RANGE_RATE_030 MRR_RR_CAN_DET_ELEVATION_032 MRR_RR_CAN_DET_AMPLITUDE_031 MRR_RR_CAN_DET_ELEVATION_030 MRR_RR_CAN_DET_RANGE_RATE_033 MRR_RR_CAN_DET_AMPLITUDE_033 MRR_RR_CAN_DET_AZIMUTH_035 MRR_RR_CAN_DET_RANGE_031 MRR_RR_CAN_DET_VALID_LEVEL_032 MRR_RR_CAN_DET_HOST_VEH_CLU_0032 MRR_RR_CAN_DET_SUPER_RES_TA_0031 MRR_RR_CAN_DET_CONFID_ELEVA_0031 MRR_RR_CAN_DET_CONFID_AZIMU_0028 MRR_RR_CAN_DET_AZIMUTH_031 MRR_RR_CAN_DET_CONFID_ELEVA_0032 MRR_RR_CAN_DET_SUPER_RES_TA_0032 MRR_RR_CAN_SCAN_INDEX_2LSB_031 MRR_RR_CAN_DET_SUPER_RES_TA_0033 MRR_RR_CAN_DET_RANGE_030 MRR_RR_CAN_DET_CONFID_AZIMU_0030 MRR_RR_CAN_DET_CONFID_ELEVA_0033 MRR_RR_CAN_DET_HOST_VEH_CLU_0033 MRR_RR_CAN_DET_AZIMUTH_030 MRR_RR_CAN_DET_ELEVATION_031 MRR_RR_CAN_DET_AMPLITUDE_032 MRR_RR_CAN_SCAN_INDEX_2LSB_032 MRR_RR_CAN_DET_RANGE_032 MRR_RR_CAN_DET_AZIMUTH_032 MRR_RR_CAN_DET_VALID_LEVEL_033 MRR_RR_DET_CRC_005 MRR_RR_CAN_DET_AZIMUTH_033 MRR_RR_CAN_DET_RANGE_RATE_035 MRR_RR_CAN_DET_HOST_VEH_CLU_0030 MRR_RR_DET_MC_005 MRR_RR_CAN_DET_RANGE_033 MRR_RR_CAN_DET_CONFID_AZIMU_0027 MRR_RR_CAN_SCAN_INDEX_2LSB_034 MRR_RR_CAN_DET_CONFID_ELEVA_0030 MRR_RR_CAN_DET_VALID_LEVEL_031 MRR_RR_CAN_DET_HOST_VEH_CLU_0028 MRR_RR_CAN_DET_CONFID_ELEVA_0028 MRR_RR_CAN_DET_CONFID_AZIMU_0029 MRR_RR_CAN_DET_RANGE_RATE_032 MRR_RR_CAN_DET_HOST_VEH_CLU_0031 MRR_RR_CAN_DET_SUPER_RES_TA_0030 MRR_RR_CAN_DET_ELEVATION_033 MRR_RR_CAN_DET_RANGE_RATE_031 MRR_RR_CAN_DET_AZIMUTH_034 MRR_RR_CAN_DET_RANGE_035 MRR_RR_CAN_SCAN_INDEX_2LSB_035 MRR_RR_CAN_DET_CONFID_AZIMU_0026 MRR_RR_CAN_DET_AMPLITUDE_034 MRR_RR_CAN_DET_RANGE_RATE_034 MRR_RR_CAN_SCAN_INDEX_2LSB_033 MRR_RR_CAN_DET_CONFID_AZIMUTH_03 MRR_RR_CAN_DET_AMPLITUDE_035 MRR_RR_CAN_DET_VALID_LEVEL_035 MRR_RR_CAN_DET_CONFID_ELEVA_0029 MRR_RR_CAN_DET_SUPER_RES_TA_0029 MRR_RR_CAN_DET_ELEVATION_034 MRR_RR_CAN_DET_RANGE_034 MRR_RR_CAN_DET_HOST_VEH_CLU_0029 MRR_RR_CAN_DET_VALID_LEVEL_034 MRR_RR_CAN_SCAN_INDEX_2LSB_029 MRR_RR_CAN_DET_AMPLITUDE_029 MRR_RR_CAN_DET_RANGE_RATE_029 MRR_RR_CAN_DET_SUPER_RES_TA_0028 MRR_RR_CAN_DET_ELEVATION_035 MRR_RR_CAN_DET_HOST_VEH_CLU_0027 MRR_RR_CAN_DET_SUPER_RES_TA_0027 MRR_RR_CAN_DET_CONFID_ELEVA_0027;
SIG_GROUP_ 1541 MRR_RR_Detection_036_042 1 : MRR_RR_CAN_DET_Near_TARGET_042 MRR_RR_CAN_DET_Near_TARGET_041 MRR_RR_CAN_DET_Near_TARGET_040 MRR_RR_CAN_DET_Near_TARGET_039 MRR_RR_CAN_DET_Near_TARGET_038 MRR_RR_CAN_DET_Near_TARGET_037 MRR_RR_CAN_DET_Near_TARGET_036 MRR_RR_CAN_DET_MID_TARGET_036 MRR_RR_CAN_DET_MID_TARGET_037 MRR_RR_CAN_DET_MID_TARGET_038 MRR_RR_CAN_DET_MID_TARGET_039 MRR_RR_CAN_DET_MID_TARGET_040 MRR_RR_CAN_DET_MID_TARGET_041 MRR_RR_CAN_DET_MID_TARGET_042 MRR_RR_CAN_DET_ELEVATION_036 MRR_RR_CAN_DET_CONFID_AZIMU_0031 MRR_RR_CAN_DET_AMPLITUDE_037 MRR_RR_CAN_DET_SUPER_RES_TA_0034 MRR_RR_CAN_SCAN_INDEX_2LSB_037 MRR_RR_CAN_DET_HOST_VEH_CLU_0034 MRR_RR_CAN_DET_CONFID_AZIMU_0036 MRR_RR_CAN_DET_RANGE_RATE_037 MRR_RR_CAN_DET_RANGE_037 MRR_RR_CAN_DET_AZIMUTH_036 MRR_RR_CAN_DET_RANGE_036 MRR_RR_CAN_DET_AMPLITUDE_036 MRR_RR_CAN_DET_ELEVATION_042 MRR_RR_CAN_DET_VALID_LEVEL_040 MRR_RR_CAN_DET_AZIMUTH_040 MRR_RR_CAN_DET_RANGE_038 MRR_RR_CAN_DET_CONFID_ELEVA_0040 MRR_RR_CAN_DET_HOST_VEH_CLU_0040 MRR_RR_CAN_DET_AZIMUTH_037 MRR_RR_CAN_DET_ELEVATION_040 MRR_RR_CAN_DET_VALID_LEVEL_036 MRR_RR_CAN_DET_RANGE_RATE_036 MRR_RR_CAN_DET_CONFID_ELEVA_0034 MRR_RR_CAN_SCAN_INDEX_2LSB_038 MRR_RR_CAN_DET_AMPLITUDE_038 MRR_RR_CAN_DET_AMPLITUDE_040 MRR_RR_CAN_DET_AZIMUTH_038 MRR_RR_CAN_DET_RANGE_040 MRR_RR_CAN_DET_RANGE_039 MRR_RR_CAN_DET_VALID_LEVEL_038 MRR_RR_CAN_DET_HOST_VEH_CLU_0039 MRR_RR_CAN_DET_HOST_VEH_CLU_0037 MRR_RR_CAN_DET_RANGE_RATE_040 MRR_RR_CAN_SCAN_INDEX_2LSB_040 MRR_RR_CAN_DET_ELEVATION_038 MRR_RR_CAN_DET_RANGE_RATE_039 MRR_RR_CAN_DET_AMPLITUDE_039 MRR_RR_CAN_DET_CONFID_ELEVA_0038 MRR_RR_CAN_DET_AZIMUTH_039 MRR_RR_CAN_DET_VALID_LEVEL_039 MRR_RR_CAN_DET_HOST_VEH_CLU_0038 MRR_RR_CAN_DET_ELEVATION_039 MRR_RR_CAN_DET_VALID_LEVEL_037 MRR_RR_CAN_DET_CONFID_ELEVA_0039 MRR_RR_CAN_DET_SUPER_RES_TA_0039 MRR_RR_CAN_DET_CONFID_AZIMU_0033 MRR_RR_CAN_DET_SUPER_RES_TA_0040 MRR_RR_DET_MC_006 MRR_RR_DET_CRC_006 MRR_RR_CAN_SCAN_INDEX_2LSB_036 MRR_RR_CAN_DET_ELEVATION_037 MRR_RR_CAN_DET_AMPLITUDE_042 MRR_RR_CAN_DET_RANGE_042 MRR_RR_CAN_DET_VALID_LEVEL_041 MRR_RR_CAN_SCAN_INDEX_2LSB_039 MRR_RR_CAN_DET_SUPER_RES_TA_0035 MRR_RR_CAN_DET_AZIMUTH_042 MRR_RR_CAN_DET_RANGE_RATE_042 MRR_RR_CAN_DET_HOST_VEH_CLU_0035 MRR_RR_CAN_DET_CONFID_AZIMU_0035 MRR_RR_CAN_DET_AZIMUTH_041 MRR_RR_CAN_DET_RANGE_041 MRR_RR_CAN_DET_VALID_LEVEL_042 MRR_RR_CAN_DET_CONFID_AZIMU_0034 MRR_RR_CAN_DET_RANGE_RATE_038 MRR_RR_CAN_DET_SUPER_RES_TA_0037 MRR_RR_CAN_DET_SUPER_RES_TA_0038 MRR_RR_CAN_DET_CONFID_AZIMU_0032 MRR_RR_CAN_SCAN_INDEX_2LSB_041 MRR_RR_CAN_DET_RANGE_RATE_041 MRR_RR_CAN_DET_AMPLITUDE_041 MRR_RR_CAN_DET_CONFID_ELEVA_0037 MRR_RR_CAN_DET_HOST_VEH_CLU_0036 MRR_RR_CAN_DET_CONFID_ELEVA_0036 MRR_RR_CAN_DET_SUPER_RES_TA_0036 MRR_RR_CAN_DET_ELEVATION_041 MRR_RR_CAN_SCAN_INDEX_2LSB_042 MRR_RR_CAN_DET_CONFID_AZIMUTH_04 MRR_RR_CAN_DET_CONFID_ELEVA_0035;
SIG_GROUP_ 1542 MRR_RR_Detection_043_049 1 : MRR_RR_CAN_DET_Near_TARGET_049 MRR_RR_CAN_DET_Near_TARGET_048 MRR_RR_CAN_DET_Near_TARGET_047 MRR_RR_CAN_DET_Near_TARGET_046 MRR_RR_CAN_DET_Near_TARGET_045 MRR_RR_CAN_DET_Near_TARGET_044 MRR_RR_CAN_DET_Near_TARGET_043 MRR_RR_CAN_DET_MID_TARGET_043 MRR_RR_CAN_DET_MID_TARGET_044 MRR_RR_CAN_DET_MID_TARGET_045 MRR_RR_CAN_DET_MID_TARGET_046 MRR_RR_CAN_DET_MID_TARGET_047 MRR_RR_CAN_DET_MID_TARGET_048 MRR_RR_CAN_DET_MID_TARGET_049 MRR_RR_CAN_DET_ELEVATION_043 MRR_RR_CAN_DET_CONFID_AZIMU_0037 MRR_RR_CAN_DET_SUPER_RES_TA_0041 MRR_RR_CAN_DET_AZIMUTH_043 MRR_RR_CAN_DET_VALID_LEVEL_044 MRR_RR_CAN_DET_HOST_VEH_CLU_0041 MRR_RR_CAN_DET_VALID_LEVEL_043 MRR_RR_CAN_DET_CONFID_ELEVA_0041 MRR_RR_CAN_DET_AMPLITUDE_044 MRR_RR_CAN_DET_RANGE_RATE_044 MRR_RR_CAN_SCAN_INDEX_2LSB_044 MRR_RR_DET_MC_007 MRR_RR_CAN_DET_AZIMUTH_044 MRR_RR_CAN_DET_RANGE_043 MRR_RR_CAN_DET_RANGE_RATE_043 MRR_RR_CAN_DET_CONFID_AZIMU_0042 MRR_RR_CAN_DET_AMPLITUDE_043 MRR_RR_CAN_DET_AZIMUTH_046 MRR_RR_CAN_DET_RANGE_RATE_046 MRR_RR_CAN_DET_RANGE_046 MRR_RR_CAN_DET_AMPLITUDE_045 MRR_RR_CAN_DET_CONFID_AZIMU_0043 MRR_RR_CAN_DET_HOST_VEH_CLU_0046 MRR_RR_CAN_DET_ELEVATION_045 MRR_RR_CAN_DET_HOST_VEH_CLU_0047 MRR_RR_CAN_DET_AZIMUTH_045 MRR_RR_CAN_DET_ELEVATION_049 MRR_RR_DET_CRC_007 MRR_RR_CAN_DET_SUPER_RES_TA_0046 MRR_RR_CAN_DET_CONFID_ELEVA_0046 MRR_RR_CAN_DET_CONFID_ELEVA_0047 MRR_RR_CAN_DET_ELEVATION_044 MRR_RR_CAN_DET_RANGE_044 MRR_RR_CAN_DET_VALID_LEVEL_046 MRR_RR_CAN_SCAN_INDEX_2LSB_043 MRR_RR_CAN_DET_VALID_LEVEL_048 MRR_RR_CAN_DET_AZIMUTH_047 MRR_RR_CAN_DET_CONFID_AZIMU_0041 MRR_RR_CAN_DET_RANGE_RATE_048 MRR_RR_CAN_DET_ELEVATION_047 MRR_RR_CAN_DET_RANGE_RATE_047 MRR_RR_CAN_DET_RANGE_047 MRR_RR_CAN_DET_CONFID_AZIMU_0040 MRR_RR_CAN_DET_SUPER_RES_TA_0047 MRR_RR_CAN_DET_ELEVATION_046 MRR_RR_CAN_SCAN_INDEX_2LSB_045 MRR_RR_CAN_DET_CONFID_ELEVA_0044 MRR_RR_CAN_DET_CONFID_AZIMU_0039 MRR_RR_CAN_DET_AZIMUTH_049 MRR_RR_CAN_SCAN_INDEX_2LSB_048 MRR_RR_CAN_DET_AMPLITUDE_046 MRR_RR_CAN_DET_RANGE_045 MRR_RR_CAN_DET_SUPER_RES_TA_0044 MRR_RR_CAN_DET_SUPER_RES_TA_0045 MRR_RR_CAN_DET_RANGE_048 MRR_RR_CAN_DET_CONFID_ELEVA_0043 MRR_RR_CAN_DET_RANGE_049 MRR_RR_CAN_DET_VALID_LEVEL_045 MRR_RR_CAN_DET_CONFID_AZIMU_0038 MRR_RR_CAN_DET_ELEVATION_048 MRR_RR_CAN_DET_CONFID_ELEVA_0045 MRR_RR_CAN_DET_AMPLITUDE_047 MRR_RR_CAN_DET_HOST_VEH_CLU_0045 MRR_RR_CAN_SCAN_INDEX_2LSB_046 MRR_RR_CAN_DET_RANGE_RATE_045 MRR_RR_CAN_SCAN_INDEX_2LSB_047 MRR_RR_CAN_DET_HOST_VEH_CLU_0043 MRR_RR_CAN_DET_AZIMUTH_048 MRR_RR_CAN_DET_HOST_VEH_CLU_0044 MRR_RR_CAN_DET_AMPLITUDE_048 MRR_RR_CAN_DET_VALID_LEVEL_047 MRR_RR_CAN_DET_SUPER_RES_TA_0043 MRR_RR_CAN_DET_VALID_LEVEL_049 MRR_RR_CAN_SCAN_INDEX_2LSB_049 MRR_RR_CAN_DET_AMPLITUDE_049 MRR_RR_CAN_DET_RANGE_RATE_049 MRR_RR_CAN_DET_HOST_VEH_CLU_0042 MRR_RR_CAN_DET_CONFID_ELEVA_0042 MRR_RR_CAN_DET_SUPER_RES_TA_0042;
SIG_GROUP_ 1543 MRR_RR_Detection_050_056 1 : MRR_RR_CAN_DET_Near_TARGET_056 MRR_RR_CAN_DET_Near_TARGET_055 MRR_RR_CAN_DET_Near_TARGET_054 MRR_RR_CAN_DET_Near_TARGET_053 MRR_RR_CAN_DET_Near_TARGET_052 MRR_RR_CAN_DET_Near_TARGET_051 MRR_RR_CAN_DET_Near_TARGET_050 MRR_RR_CAN_DET_MID_TARGET_050 MRR_RR_CAN_DET_MID_TARGET_051 MRR_RR_CAN_DET_MID_TARGET_052 MRR_RR_CAN_DET_MID_TARGET_053 MRR_RR_CAN_DET_MID_TARGET_054 MRR_RR_CAN_DET_MID_TARGET_055 MRR_RR_CAN_DET_MID_TARGET_056 MRR_RR_CAN_DET_AMPLITUDE_051 MRR_RR_CAN_DET_ELEVATION_050 MRR_RR_CAN_DET_RANGE_RATE_052 MRR_RR_CAN_DET_CONFID_ELEVA_0048 MRR_RR_CAN_DET_CONFID_AZIMUTH_05 MRR_RR_CAN_SCAN_INDEX_2LSB_051 MRR_RR_CAN_DET_AMPLITUDE_052 MRR_RR_CAN_DET_CONFID_AZIMU_0048 MRR_RR_CAN_DET_RANGE_051 MRR_RR_CAN_DET_AZIMUTH_051 MRR_RR_CAN_DET_RANGE_RATE_051 MRR_RR_CAN_DET_SUPER_RES_TA_0048 MRR_RR_CAN_SCAN_INDEX_2LSB_052 MRR_RR_CAN_DET_HOST_VEH_CLU_0048 MRR_RR_CAN_DET_RANGE_RATE_053 MRR_RR_CAN_DET_RANGE_052 MRR_RR_CAN_DET_CONFID_ELEVA_0053 MRR_RR_CAN_DET_RANGE_050 MRR_RR_CAN_DET_VALID_LEVEL_050 MRR_RR_CAN_DET_AZIMUTH_050 MRR_RR_CAN_DET_RANGE_RATE_050 MRR_RR_CAN_DET_AZIMUTH_053 MRR_RR_CAN_DET_ELEVATION_052 MRR_RR_CAN_DET_AMPLITUDE_050 MRR_RR_CAN_DET_SUPER_RES_TA_0052 MRR_RR_CAN_DET_HOST_VEH_CLU_0050 MRR_RR_CAN_DET_RANGE_RATE_055 MRR_RR_CAN_DET_HOST_VEH_CLU_0052 MRR_RR_CAN_DET_RANGE_053 MRR_RR_CAN_DET_HOST_VEH_CLU_0054 MRR_RR_CAN_DET_CONFID_ELEVA_0052 MRR_RR_DET_MC_008 MRR_RR_CAN_DET_ELEVATION_053 MRR_RR_CAN_DET_RANGE_RATE_054 MRR_RR_DET_CRC_008 MRR_RR_CAN_DET_ELEVATION_054 MRR_RR_CAN_DET_HOST_VEH_CLU_0051 MRR_RR_CAN_DET_CONFID_AZIMU_0046 MRR_RR_CAN_DET_VALID_LEVEL_051 MRR_RR_CAN_DET_VALID_LEVEL_054 MRR_RR_CAN_DET_AMPLITUDE_054 MRR_RR_CAN_DET_SUPER_RES_TA_0051 MRR_RR_CAN_DET_ELEVATION_051 MRR_RR_CAN_DET_AZIMUTH_054 MRR_RR_CAN_SCAN_INDEX_2LSB_055 MRR_RR_CAN_DET_VALID_LEVEL_056 MRR_RR_CAN_SCAN_INDEX_2LSB_053 MRR_RR_CAN_DET_AMPLITUDE_055 MRR_RR_CAN_SCAN_INDEX_2LSB_050 MRR_RR_CAN_DET_CONFID_AZIMU_0049 MRR_RR_CAN_DET_SUPER_RES_TA_0054 MRR_RR_CAN_SCAN_INDEX_2LSB_054 MRR_RR_CAN_DET_AMPLITUDE_053 MRR_RR_CAN_SCAN_INDEX_2LSB_056 MRR_RR_CAN_DET_HOST_VEH_CLU_0049 MRR_RR_CAN_DET_CONFID_ELEVA_0054 MRR_RR_CAN_DET_ELEVATION_056 MRR_RR_CAN_DET_VALID_LEVEL_052 MRR_RR_CAN_DET_AZIMUTH_056 MRR_RR_CAN_DET_CONFID_AZIMU_0047 MRR_RR_CAN_DET_HOST_VEH_CLU_0053 MRR_RR_CAN_DET_VALID_LEVEL_053 MRR_RR_CAN_DET_SUPER_RES_TA_0049 MRR_RR_CAN_DET_SUPER_RES_TA_0053 MRR_RR_CAN_DET_RANGE_055 MRR_RR_CAN_DET_CONFID_AZIMU_0045 MRR_RR_CAN_DET_CONFID_ELEVA_0051 MRR_RR_CAN_DET_SUPER_RES_TA_0050 MRR_RR_CAN_DET_CONFID_ELEVA_0050 MRR_RR_CAN_DET_AZIMUTH_055 MRR_RR_CAN_DET_CONFID_AZIMU_0044 MRR_RR_CAN_DET_RANGE_056 MRR_RR_CAN_DET_CONFID_ELEVA_0049 MRR_RR_CAN_DET_AZIMUTH_052 MRR_RR_CAN_DET_RANGE_RATE_056 MRR_RR_CAN_DET_AMPLITUDE_056 MRR_RR_CAN_DET_ELEVATION_055 MRR_RR_CAN_DET_RANGE_054 MRR_RR_CAN_DET_VALID_LEVEL_055;
SIG_GROUP_ 1544 MRR_RR_Detection_057_063 1 : MRR_RR_CAN_DET_Near_TARGET_063 MRR_RR_CAN_DET_Near_TARGET_062 MRR_RR_CAN_DET_Near_TARGET_061 MRR_RR_CAN_DET_Near_TARGET_060 MRR_RR_CAN_DET_Near_TARGET_059 MRR_RR_CAN_DET_Near_TARGET_058 MRR_RR_CAN_DET_Near_TARGET_057 MRR_RR_CAN_DET_MID_TARGET_057 MRR_RR_CAN_DET_MID_TARGET_058 MRR_RR_CAN_DET_MID_TARGET_059 MRR_RR_CAN_DET_MID_TARGET_060 MRR_RR_CAN_DET_MID_TARGET_061 MRR_RR_CAN_DET_MID_TARGET_062 MRR_RR_CAN_DET_MID_TARGET_063 MRR_RR_CAN_DET_ELEVATION_057 MRR_RR_DET_MC_009 MRR_RR_CAN_DET_RANGE_060 MRR_RR_CAN_DET_AMPLITUDE_060 MRR_RR_CAN_DET_RANGE_RATE_059 MRR_RR_CAN_DET_VALID_LEVEL_061 MRR_RR_DET_CRC_009 MRR_RR_CAN_DET_CONFID_ELEVA_0055 MRR_RR_CAN_DET_AZIMUTH_061 MRR_RR_CAN_DET_HOST_VEH_CLU_0055 MRR_RR_CAN_DET_RANGE_057 MRR_RR_CAN_DET_AMPLITUDE_057 MRR_RR_CAN_DET_RANGE_RATE_057 MRR_RR_CAN_DET_AZIMUTH_057 MRR_RR_CAN_SCAN_INDEX_2LSB_057 MRR_RR_CAN_SCAN_INDEX_2LSB_060 MRR_RR_CAN_DET_RANGE_063 MRR_RR_CAN_DET_ELEVATION_063 MRR_RR_CAN_DET_HOST_VEH_CLU_0059 MRR_RR_CAN_DET_CONFID_AZIMU_0053 MRR_RR_CAN_DET_RANGE_RATE_060 MRR_RR_CAN_DET_VALID_LEVEL_058 MRR_RR_CAN_DET_ELEVATION_059 MRR_RR_CAN_DET_SUPER_RES_TA_0061 MRR_RR_CAN_DET_CONFID_ELEVA_0061 MRR_RR_CAN_DET_CONFID_AZIMU_0055 MRR_RR_CAN_SCAN_INDEX_2LSB_058 MRR_RR_CAN_DET_AMPLITUDE_058 MRR_RR_CAN_DET_RANGE_059 MRR_RR_CAN_DET_VALID_LEVEL_060 MRR_RR_CAN_DET_ELEVATION_058 MRR_RR_CAN_DET_SUPER_RES_TA_0060 MRR_RR_CAN_DET_RANGE_RATE_058 MRR_RR_CAN_DET_CONFID_ELEVA_0060 MRR_RR_CAN_DET_RANGE_058 MRR_RR_CAN_DET_HOST_VEH_CLU_0061 MRR_RR_CAN_DET_VALID_LEVEL_059 MRR_RR_CAN_DET_AZIMUTH_058 MRR_RR_CAN_DET_SUPER_RES_TA_0059 MRR_RR_CAN_DET_CONFID_ELEVA_0059 MRR_RR_CAN_DET_AMPLITUDE_061 MRR_RR_CAN_SCAN_INDEX_2LSB_061 MRR_RR_CAN_DET_HOST_VEH_CLU_0058 MRR_RR_CAN_DET_RANGE_RATE_061 MRR_RR_CAN_DET_AMPLITUDE_063 MRR_RR_CAN_DET_ELEVATION_062 MRR_RR_CAN_SCAN_INDEX_2LSB_062 MRR_RR_CAN_DET_HOST_VEH_CLU_0060 MRR_RR_CAN_DET_CONFID_AZIMU_0052 MRR_RR_CAN_DET_CONFID_ELEVA_0058 MRR_RR_CAN_DET_AZIMUTH_059 MRR_RR_CAN_DET_AZIMUTH_062 MRR_RR_CAN_DET_SUPER_RES_TA_0056 MRR_RR_CAN_DET_AMPLITUDE_059 MRR_RR_CAN_DET_RANGE_RATE_062 MRR_RR_CAN_DET_AZIMUTH_060 MRR_RR_CAN_DET_SUPER_RES_TA_0058 MRR_RR_CAN_DET_AMPLITUDE_062 MRR_RR_CAN_DET_VALID_LEVEL_057 MRR_RR_CAN_DET_SUPER_RES_TA_0055 MRR_RR_CAN_DET_CONFID_AZIMU_0050 MRR_RR_CAN_DET_ELEVATION_060 MRR_RR_CAN_DET_CONFID_AZIMU_0051 MRR_RR_CAN_DET_RANGE_062 MRR_RR_CAN_DET_CONFID_AZIMU_0054 MRR_RR_CAN_DET_VALID_LEVEL_062 MRR_RR_CAN_DET_ELEVATION_061 MRR_RR_CAN_DET_RANGE_061 MRR_RR_CAN_DET_HOST_VEH_CLU_0057 MRR_RR_CAN_DET_CONFID_ELEVA_0057 MRR_RR_CAN_DET_SUPER_RES_TA_0057 MRR_RR_CAN_DET_VALID_LEVEL_063 MRR_RR_CAN_SCAN_INDEX_2LSB_063 MRR_RR_CAN_DET_RANGE_RATE_063 MRR_RR_CAN_DET_CONFID_AZIMUTH_06 MRR_RR_CAN_DET_AZIMUTH_063 MRR_RR_CAN_DET_HOST_VEH_CLU_0056 MRR_RR_CAN_DET_CONFID_ELEVA_0056 MRR_RR_CAN_SCAN_INDEX_2LSB_059;
SIG_GROUP_ 1545 MRR_RR_Detection_064 1 : MRR_RR_CAN_DET_Near_TARGET_064 MRR_RR_CAN_DET_MID_TARGET_064 MRR_RR_DET_MC_010 MRR_RR_DET_CRC_010 MRR_RR_CAN_DET_ELEVATION_064 MRR_RR_CAN_DET_CONFID_AZIMU_0056 MRR_RR_CAN_DET_SUPER_RES_TA_0062 MRR_RR_CAN_DET_CONFID_ELEVA_0062 MRR_RR_CAN_DET_HOST_VEH_CLU_0062 MRR_RR_CAN_DET_VALID_LEVEL_064 MRR_RR_CAN_DET_AZIMUTH_064 MRR_RR_CAN_DET_RANGE_064 MRR_RR_CAN_DET_AMPLITUDE_064 MRR_RR_CAN_DET_RANGE_RATE_064 MRR_RR_CAN_SCAN_INDEX_2LSB_064;
SIG_GROUP_ 263 MRR_RR_Header_Timestamps 1 : MRR_RR_Sensor_Position MRR_RR_Sensor_Position_Lock MRR_RR_CAN_NUMBER_OF_DET MRR_RR_CAN_SCAN_INDEX_FUSED MRR_RR_CAN_LOOK_ID MRR_RR_CAN_LOOK_INDEX MRR_RR_CAN_DET_TIME_SINCE_MEAS MRR_RR_TrackStatus_CRC MRR_RR_TrackStatus_MC MRR_RR_CAN_ReSync_counter MRR_RR_CAN_TX_LOOK_INDEX_8 MRR_RR_CAN_TX_SCAN_INDEX_TRACKER MRR_RR_CAN_TX_SCN_INDEX_TRKER_FU MRR_RR_CAN_TX_LOOK_TYPE MRR_RR_CAN_TX_LOOK_ID MRR_RR_CAN_TX_SYSTEM_TIME_STAMP;
SIG_GROUP_ 327 MRR_RL_Header_Timestamps 1 : MRR_RL_Sensor_Position MRR_RL_Sensor_Position_Lock MRR_RL_CAN_NUMBER_OF_DET MRR_RL_CAN_SCAN_INDEX_FUSED MRR_RL_CAN_LOOK_ID MRR_RL_CAN_LOOK_INDEX MRR_RL_CAN_DET_TIME_SINCE_MEAS MRR_RL_TrackStatus_CRC MRR_RL_TrackStatus_MC MRR_RL_CAN_ReSync_counter MRR_RL_CAN_TX_LOOK_INDEX_8 MRR_RL_CAN_TX_SCAN_INDEX_TRACKER MRR_RL_CAN_TX_SCN_INDEX_TRKER_FU MRR_RL_CAN_TX_LOOK_TYPE MRR_RL_CAN_TX_LOOK_ID MRR_RL_CAN_TX_SYSTEM_TIME_STAMP;
SIG_GROUP_ 328 MRR_RL_Header_SensorCoverage 1 : MRR_RL_Radar_Spec_Status_CRC MRR_RL_Radar_Spec_Status_MC MRR_CAN_RadarWaveform_RL MRR_RL_CAN_RANGE_COVERAGE MRR_RL_CAN_DOPPLER_COVERAGE MRR_RL_CAN_FOV_HOR MRR_RL_CAN_FOV_VER;
SIG_GROUP_ 331 MRR_RL_Header_AlignmentState 1 : MRR_RL_CAN_HRZNTL_ALIGN_UPDATES_ MRR_RL_CAN_VRTCL_ALIGN_UPDATES_N MRR_RL_Header_AlignmentState_CRC MRR_RL_Header_AlignmentState_MC MRR_RL_Horizontal_Alignment_Stat MRR_RL_Vertical_Alignment_Status MRR_RL_Vertical_Alignment_State MRR_RL_Horizontal_Alignment_0000 MRR_RL_Align_Vertical_Ref MRR_RL_Align_Vertical_QF MRR_RL_Align_Vertical_Angle MRR_RL_Align_Horizontal_Angle MRR_RL_Align_Horizontal_Ref MRR_RL_Align_Horizontal_QF;
